VERSION "dbc-export 1 2025.20.8"

NS_ :

BS_:

BU_: ADSP APB APP APS APSB BB BMS CC CMP CMPD CP DAS DI DIF DIR DPB EPAS3P EPAS3S EPASTP EPASTS EPBL EPBR ESP EVSE FC GTW HCML HCMR HVP IBST ICR IDB LS OCS1P ODIN PARK PCS PLG PM PMF PMR PNCD PTC RADC RCM RCM2 RCM3 RCU SCCM SCM SCS SDCR TAS TCU TPMS TRCM UDS UI UIS UMC USM VC VCFRONT VCLEFT VCRIGHT VCSEC VEH

BO_ 1319 DI_alertLog: 8 DI
 SG_ DI_alertID M : 0|8@1+ (1,0) [0|255] "" Vector__XXX
 SG_ DI_alertState : 15|1@1+ (1,0) [0|1] "" Vector__XXX
 SG_ DI_a004_unavailableReason m4 : 16|5@1+ (1,0) [1|31] "" Vector__XXX
 SG_ DI_a007_button m7 : 16|2@1+ (1,0) [0|3] "" Vector__XXX
 SG_ DI_a007_buttonStuckTime m7 : 24|15@1+ (0.25,0) [0|8191.75] "second" Vector__XXX
 SG_ DI_a010_sccReset m10 : 16|1@1+ (1,0) [0|1] "" Vector__XXX
 SG_ DI_a010_hibernate m10 : 17|1@1+ (1,0) [0|1] "" Vector__XXX
 SG_ DI_a010_hwBist m10 : 18|1@1+ (1,0) [0|1] "" Vector__XXX
 SG_ DI_a010_nmiWatchdog m10 : 19|1@1+ (1,0) [0|1] "" Vector__XXX
 SG_ DI_a010_watchdog m10 : 20|1@1+ (1,0) [0|1] "" Vector__XXX
 SG_ DI_a010_clockFailNmi m10 : 21|1@1+ (1,0) [0|1] "" Vector__XXX
 SG_ DI_a010_ramUncErrorNmi m10 : 22|1@1+ (1,0) [0|1] "" Vector__XXX
 SG_ DI_a010_flashUncErrorNmi m10 : 23|1@1+ (1,0) [0|1] "" Vector__XXX
 SG_ DI_a010_cpu1signMismatchNmi m10 : 24|1@1+ (1,0) [0|1] "" Vector__XXX
 SG_ DI_a010_cpu2signMismatchNmi m10 : 25|1@1+ (1,0) [0|1] "" Vector__XXX
 SG_ DI_a010_pieVectErrorNmi m10 : 26|1@1+ (1,0) [0|1] "" Vector__XXX
 SG_ DI_a010_sysDbgNmi m10 : 27|1@1+ (1,0) [0|1] "" Vector__XXX
 SG_ DI_a010_rlNmi m10 : 28|1@1+ (1,0) [0|1] "" Vector__XXX
 SG_ DI_a010_ovfNmi m10 : 29|1@1+ (1,0) [0|1] "" Vector__XXX
 SG_ DI_a010_wdtFlags m10 : 32|16@1+ (1,0) [0|65535] "" Vector__XXX
 SG_ DI_a012_accel1SupplyV m12 : 16|16@1+ (0.001,0) [0|65.535] "V" Vector__XXX
 SG_ DI_a012_accel2SupplyV m12 : 32|16@1+ (0.001,0) [0|65.535] "V" Vector__XXX
 SG_ DI_a013_address m13 : 16|32@1+ (1,0) [0|4294967295] "" Vector__XXX
 SG_ DI_a013_errorType m13 : 48|4@1+ (1,0) [0|15] "" Vector__XXX
 SG_ DI_a015_reason m15 : 16|1@1+ (1,0) [0|1] "" Vector__XXX
 SG_ DI_a020_difHvilStatus m20 : 16|2@1+ (1,0) [0|2] "" Vector__XXX
 SG_ DI_a020_difStatusValid m20 : 18|1@1+ (1,0) [0|1] "" Vector__XXX
 SG_ DI_a020_dirHvilStatus m20 : 19|2@1+ (1,0) [0|2] "" Vector__XXX
 SG_ DI_a020_dirStatusValid m20 : 21|1@1+ (1,0) [0|1] "" Vector__XXX
 SG_ DI_a020_vehiclePowerState m20 : 22|2@1+ (1,0) [0|3] "" Vector__XXX
 SG_ DI_a020_hvilSystemStatus m20 : 24|2@1+ (1,0) [0|2] "" Vector__XXX
 SG_ DI_a021_packVoltage m21 : 16|16@1+ (0.1,0) [0|6553.5] "V" Vector__XXX
 SG_ DI_a021_maxBusVoltage m21 : 32|16@1+ (0.1,0) [0|6553.5] "V" Vector__XXX
 SG_ DI_a024_pedalPos m24 : 16|8@1+ (0.4,0) [0|102] "%" Vector__XXX
 SG_ DI_a024_brakePressed m24 : 24|1@1+ (1,0) [0|1] "" Vector__XXX
 SG_ DI_a024_currentGear m24 : 25|3@1+ (1,0) [0|6] "" Vector__XXX
 SG_ DI_a025_backfillState m25 : 16|2@1+ (1,0) [0|3] "" Vector__XXX
 SG_ DI_a025_bfillUnavailableReason m25 : 18|5@1+ (1,0) [0|31] "" Vector__XXX
 SG_ DI_a036_numFaultedUnits m36 : 16|4@1+ (1,0) [0|15] "" Vector__XXX
 SG_ DI_a036_numAvailableUnits m36 : 20|4@1+ (1,0) [0|15] "" Vector__XXX
 SG_ DI_a040_torque m40 : 16|1@1+ (1,0) [0|1] "" Vector__XXX
 SG_ DI_a040_capability m40 : 17|1@1+ (1,0) [0|1] "" Vector__XXX
 SG_ DI_a040_power m40 : 18|1@1+ (1,0) [0|1] "" Vector__XXX
 SG_ DI_a040_status m40 : 19|1@1+ (1,0) [0|1] "" Vector__XXX
 SG_ DI_a040_capability2 m40 : 20|1@1+ (1,0) [0|1] "" Vector__XXX
 SG_ DI_a040_hvStatus m40 : 21|1@1+ (1,0) [0|1] "" Vector__XXX
 SG_ DI_a040_temperature m40 : 22|1@1+ (1,0) [0|1] "" Vector__XXX
 SG_ DI_a042_state4 m42 : 16|1@1+ (1,0) [0|1] "" Vector__XXX
 SG_ DI_a043_state4 m43 : 16|1@1+ (1,0) [0|1] "" Vector__XXX
 SG_ DI_a051_dcCableCurrentEst m51 : 16|16@1- (0.1,0) [-3276.8|3276.7] "A" Vector__XXX
 SG_ DI_a051_packCurrent m51 : 32|16@1- (0.1,0) [-3276.8|3276.7] "A" Vector__XXX
 SG_ DI_a052_torque m52 : 16|1@1+ (1,0) [0|1] "" Vector__XXX
 SG_ DI_a052_capability m52 : 17|1@1+ (1,0) [0|1] "" Vector__XXX
 SG_ DI_a052_power m52 : 18|1@1+ (1,0) [0|1] "" Vector__XXX
 SG_ DI_a052_status m52 : 19|1@1+ (1,0) [0|1] "" Vector__XXX
 SG_ DI_a052_capability2 m52 : 20|1@1+ (1,0) [0|1] "" Vector__XXX
 SG_ DI_a052_hvStatus m52 : 21|1@1+ (1,0) [0|1] "" Vector__XXX
 SG_ DI_a052_temperature m52 : 22|1@1+ (1,0) [0|1] "" Vector__XXX
 SG_ DI_a053_badValue1 m53 : 16|16@1+ (1,0) [0|65535] "" Vector__XXX
 SG_ DI_a053_badValue2 m53 : 32|16@1+ (1,0) [0|65535] "" Vector__XXX
 SG_ DI_a053_canID m53 : 48|12@1+ (1,0) [0|4095] "" Vector__XXX
 SG_ DI_a053_errorType m53 : 60|3@1+ (1,0) [0|7] "" Vector__XXX
 SG_ DI_a056_badValue1 m56 : 16|16@1+ (1,0) [0|65535] "" Vector__XXX
 SG_ DI_a056_badValue2 m56 : 32|16@1+ (1,0) [0|65535] "" Vector__XXX
 SG_ DI_a056_canID m56 : 48|12@1+ (1,0) [0|4095] "" Vector__XXX
 SG_ DI_a056_errorType m56 : 60|3@1+ (1,0) [0|7] "" Vector__XXX
 SG_ DI_a059_badValue1 m59 : 16|16@1+ (1,0) [0|65535] "" Vector__XXX
 SG_ DI_a059_badValue2 m59 : 32|16@1+ (1,0) [0|65535] "" Vector__XXX
 SG_ DI_a059_canID m59 : 48|12@1+ (1,0) [0|4095] "" Vector__XXX
 SG_ DI_a059_errorType m59 : 60|3@1+ (1,0) [0|7] "" Vector__XXX
 SG_ DI_a062_limpReason m62 : 16|6@1+ (1,0) [0|63] "" Vector__XXX
 SG_ DI_a063_gpoReason m63 : 16|4@1+ (1,0) [0|15] "" Vector__XXX
 SG_ DI_a064_hvState m64 : 16|3@1+ (1,0) [0|7] "" Vector__XXX
 SG_ DI_a064_vehiclePowerState m64 : 19|2@1+ (1,0) [0|3] "" Vector__XXX
 SG_ DI_a064_vehicleSpeed m64 : 24|12@1+ (0.08,-40) [-40|287.6] "kph" Vector__XXX
 SG_ DI_a066_badValue1 m66 : 16|16@1+ (1,0) [0|65535] "" Vector__XXX
 SG_ DI_a066_badValue2 m66 : 32|16@1+ (1,0) [0|65535] "" Vector__XXX
 SG_ DI_a066_canID m66 : 48|12@1+ (1,0) [0|4095] "" Vector__XXX
 SG_ DI_a066_errorType m66 : 60|3@1+ (1,0) [0|7] "" Vector__XXX
 SG_ DI_a076_lvSupplyV m76 : 16|16@1+ (0.001,0) [0|65.535] "V" Vector__XXX
 SG_ DI_a077_lvSupplyV m77 : 16|16@1+ (0.001,0) [0|65.535] "V" Vector__XXX
 SG_ DI_a078_adcRefChan m78 : 16|4@1+ (1,0) [0|15] "" Vector__XXX
 SG_ DI_a078_adcRefLowAvg m78 : 24|16@1+ (1,0) [0|65535] "" Vector__XXX
 SG_ DI_a079_adcRefChan m79 : 16|4@1+ (1,0) [0|15] "" Vector__XXX
 SG_ DI_a079_adcRefHighAvg m79 : 24|16@1+ (1,0) [0|65535] "" Vector__XXX
 SG_ DI_a083_brakeSwitchNO m83 : 16|1@1+ (1,0) [0|1] "" Vector__XXX
 SG_ DI_a083_brakeSwitchNC m83 : 17|1@1+ (1,0) [0|1] "" Vector__XXX
 SG_ DI_a083_brakeSwitchIrrationalNO m83 : 18|1@1+ (1,0) [0|1] "" Vector__XXX
 SG_ DI_a083_brakeSwitchIrrationalNC m83 : 19|1@1+ (1,0) [0|1] "" Vector__XXX
 SG_ DI_a086_DPB_actuator3 m86 : 16|1@1+ (1,0) [0|1] "" Vector__XXX
 SG_ DI_a087_gtwCarConfig m87 : 16|1@1+ (1,0) [0|1] "" Vector__XXX
 SG_ DI_a087_gtwTime m87 : 17|1@1+ (1,0) [0|1] "" Vector__XXX
 SG_ DI_a087_gtwUpdateStatus m87 : 18|1@1+ (1,0) [0|1] "" Vector__XXX
 SG_ DI_a087_gearControl m87 : 19|1@1+ (1,0) [0|1] "" Vector__XXX
 SG_ DI_a087_carState m87 : 20|1@1+ (1,0) [0|1] "" Vector__XXX
 SG_ DI_a089_SCCM_rightStalk m89 : 16|1@1+ (1,0) [0|1] "" Vector__XXX
 SG_ DI_a090_reason m90 : 16|1@1+ (1,0) [0|1] "" Vector__XXX
 SG_ DI_a090_systemState m90 : 17|1@1+ (1,0) [0|1] "" Vector__XXX
 SG_ DI_a090_state m90 : 18|1@1+ (1,0) [0|1] "" Vector__XXX
 SG_ DI_a090_locState m90 : 19|1@1+ (1,0) [0|1] "" Vector__XXX
 SG_ DI_a090_state2 m90 : 20|1@1+ (1,0) [0|1] "" Vector__XXX
 SG_ DI_a090_state4 m90 : 21|1@1+ (1,0) [0|1] "" Vector__XXX
 SG_ DI_a091_ESP_brakeTorque m91 : 16|1@1+ (1,0) [0|1] "" Vector__XXX
 SG_ DI_a091_ESP_wheelSpeeds m91 : 17|1@1+ (1,0) [0|1] "" Vector__XXX
 SG_ DI_a091_ESP_wheelRotation m91 : 18|1@1+ (1,0) [0|1] "" Vector__XXX
 SG_ DI_a091_ESP_motorLimits m91 : 19|1@1+ (1,0) [0|1] "" Vector__XXX
 SG_ DI_a091_ESP_offsets m91 : 20|1@1+ (1,0) [0|1] "" Vector__XXX
 SG_ DI_a091_ESP_status m91 : 21|1@1+ (1,0) [0|1] "" Vector__XXX
 SG_ DI_a091_ESP_party3 m91 : 22|1@1+ (1,0) [0|1] "" Vector__XXX
 SG_ DI_a092_bmsStatus m92 : 16|1@1+ (1,0) [0|1] "" Vector__XXX
 SG_ DI_a092_bmsDriveLimits m92 : 17|1@1+ (1,0) [0|1] "" Vector__XXX
 SG_ DI_a092_bmsHvBusStatus m92 : 18|1@1+ (1,0) [0|1] "" Vector__XXX
 SG_ DI_a092_bmsPowerAvailable m92 : 19|1@1+ (1,0) [0|1] "" Vector__XXX
 SG_ DI_a092_bmsBmbMinMax m92 : 20|1@1+ (1,0) [0|1] "" Vector__XXX
 SG_ DI_a092_bmsSocStatus m92 : 21|1@1+ (1,0) [0|1] "" Vector__XXX
 SG_ DI_a092_bmsThermalStatus m92 : 22|1@1+ (1,0) [0|1] "" Vector__XXX
 SG_ DI_a092_bmsCtrStatus m92 : 23|1@1+ (1,0) [0|1] "" Vector__XXX
 SG_ DI_a092_bmsVoltageRegGain m92 : 24|1@1+ (1,0) [0|1] "" Vector__XXX
 SG_ DI_a092_bmsPackConfig m92 : 25|1@1+ (1,0) [0|1] "" Vector__XXX
 SG_ DI_a092_bmsSystemStatus m92 : 26|1@1+ (1,0) [0|1] "" Vector__XXX
 SG_ DI_a094_canID m94 : 16|12@1+ (1,0) [0|4095] "" Vector__XXX
 SG_ DI_a094_errorType m94 : 28|3@1+ (1,0) [0|7] "" Vector__XXX
 SG_ DI_a094_badValue1 m94 : 32|16@1+ (1,0) [0|65535] "" Vector__XXX
 SG_ DI_a094_badValue2 m94 : 48|16@1+ (1,0) [0|65535] "" Vector__XXX
 SG_ DI_a096_const_fast m96 : 16|1@1+ (1,0) [0|1] "" Vector__XXX
 SG_ DI_a096_text_fast m96 : 17|1@1+ (1,0) [0|1] "" Vector__XXX
 SG_ DI_a096_text_flash m96 : 18|1@1+ (1,0) [0|1] "" Vector__XXX
 SG_ DI_a096_mem_data m96 : 19|1@1+ (1,0) [0|1] "" Vector__XXX
 SG_ DI_a096_mem_regs m96 : 20|1@1+ (1,0) [0|1] "" Vector__XXX
 SG_ DI_a096_boot_flash m96 : 21|1@1+ (1,0) [0|1] "" Vector__XXX
 SG_ DI_a096_word1 m96 : 24|16@1+ (1,0) [0|65535] "" Vector__XXX
 SG_ DI_a096_word2 m96 : 40|16@1+ (1,0) [0|65535] "" Vector__XXX
 SG_ DI_a097_errorType m97 : 16|3@1+ (1,0) [0|7] "" Vector__XXX
 SG_ DI_a097_lineNumber m97 : 24|16@1+ (1,0) [0|65535] "" Vector__XXX
 SG_ DI_a097_argument m97 : 40|16@1+ (1,0) [0|65535] "" Vector__XXX
 SG_ DI_a098_page0Counter m98 : 16|8@1+ (1,0) [0|255] "" Vector__XXX
 SG_ DI_a098_page1Counter m98 : 24|8@1+ (1,0) [0|255] "" Vector__XXX
 SG_ DI_a098_page2Counter m98 : 32|8@1+ (1,0) [0|255] "" Vector__XXX
 SG_ DI_a098_pageID m98 : 40|2@1+ (1,0) [0|3] "" Vector__XXX
 SG_ DI_a098_recordID m98 : 42|4@1+ (1,0) [0|15] "" Vector__XXX
 SG_ DI_a098_errorCode m98 : 48|4@1+ (1,0) [0|15] "" Vector__XXX
 SG_ DI_a103_BB_status m103 : 16|1@1+ (1,0) [0|1] "" Vector__XXX
 SG_ DI_a103_BB_brakeActuation m103 : 17|1@1+ (1,0) [0|1] "" Vector__XXX
 SG_ DI_a104_proxIrrationalReason m104 : 16|1@1+ (1,0) [0|1] "" Vector__XXX
 SG_ DI_a105_cpStatus m105 : 16|1@1+ (1,0) [0|1] "" Vector__XXX
 SG_ DI_a110_EPBL_status m110 : 16|1@1+ (1,0) [0|1] "" Vector__XXX
 SG_ DI_a110_EPBR_status m110 : 17|1@1+ (1,0) [0|1] "" Vector__XXX
 SG_ DI_a115_faultAddress m115 : 16|32@1+ (1,0) [0|4294967295] "" Vector__XXX
 SG_ DI_a115_isWriteNotRead m115 : 48|1@1+ (1,0) [0|1] "" Vector__XXX
 SG_ DI_a120_blendingState m120 : 16|2@1+ (1,0) [0|3] "" Vector__XXX
 SG_ DI_a120_blendingUnavailableReaso m120 : 18|5@1+ (1,0) [0|31] "" Vector__XXX
 SG_ DI_a124_undrivenWheelMPH m124 : 16|16@1+ (0.1,0) [0|6553.5] "MPH" Vector__XXX
 SG_ DI_a124_cruiseFaultReason m124 : 32|5@1+ (1,0) [0|31] "" Vector__XXX
 SG_ DI_a125_maxDischargeCurrent m125 : 16|16@1- (0.1,0) [-3276.8|3276.7] "A" Vector__XXX
 SG_ DI_a125_maxChargeCurrent m125 : 32|16@1- (0.1,0) [-3276.8|3276.7] "A" Vector__XXX
 SG_ DI_a125_minBusVoltage m125 : 48|16@1+ (0.1,0) [0|6553.5] "V" Vector__XXX
 SG_ DI_a130_aebFaultReason m130 : 16|4@1+ (1,0) [0|15] "" Vector__XXX
 SG_ DI_a130_aebSmState m130 : 20|3@1+ (1,0) [0|7] "" Vector__XXX
 SG_ DI_a130_dasAebEvent m130 : 24|2@1+ (1,0) [0|2] "" Vector__XXX
 SG_ DI_a130_aebBrakeTorqueCommand m130 : 26|13@1+ (3,0) [0|24573] "Nm" Vector__XXX
 SG_ DI_a131_totalTimeRemaining m131 : 16|16@1+ (1,0) [0|65535] "" Vector__XXX
 SG_ DI_a131_warnSpeedLimit m131 : 32|16@1+ (1,0) [0|65535] "RPM" Vector__XXX
 SG_ DI_a131_warnTimeRemaining m131 : 48|16@1+ (1,0) [0|65535] "" Vector__XXX
 SG_ DI_a133_vhldSmState m133 : 16|4@1+ (1,0) [0|15] "" Vector__XXX
 SG_ DI_a133_reverseGear m133 : 20|1@1+ (1,0) [0|1] "" Vector__XXX
 SG_ DI_a133_vhldGrade m133 : 24|8@1+ (0.01,-1) [-1|1.55] "G" Vector__XXX
 SG_ DI_a134_wheelSpeedDiffFrL m134 : 16|12@1- (0.0625,0) [-128|127.9375] "kph" Vector__XXX
 SG_ DI_a134_wheelSpeedDiffFrR m134 : 28|12@1- (0.0625,0) [-128|127.9375] "kph" Vector__XXX
 SG_ DI_a134_wheelSpeedDiffReL m134 : 40|12@1- (0.0625,0) [-128|127.9375] "kph" Vector__XXX
 SG_ DI_a134_wheelSpeedDiffReR m134 : 52|12@1- (0.0625,0) [-128|127.9375] "kph" Vector__XXX
 SG_ DI_a135_vhldFaultReason m135 : 16|4@1+ (1,0) [0|15] "" Vector__XXX
 SG_ DI_a135_vhldSmState m135 : 20|4@1+ (1,0) [0|15] "" Vector__XXX
 SG_ DI_a135_vhldBrakeApply m135 : 24|1@1+ (1,0) [0|1] "" Vector__XXX
 SG_ DI_a135_vhldBrakeTorqueCommand m135 : 25|10@1+ (10,0) [0|10230] "Nm" Vector__XXX
 SG_ DI_a135_vhldTotalBrakeTorque m135 : 35|10@1+ (10,0) [0|10230] "Nm" Vector__XXX
 SG_ DI_a135_vhldPropulsiveTorque m135 : 45|10@1- (1,0) [-512|511] "Nm" Vector__XXX
 SG_ DI_a135_vhldGrade m135 : 56|8@1+ (0.01,-1) [-1|1.55] "G" Vector__XXX
 SG_ DI_a140_PTC_feedbackStatus m140 : 16|1@1+ (1,0) [0|1] "" Vector__XXX
 SG_ DI_a141_DAS_control m141 : 16|1@1+ (1,0) [0|1] "" Vector__XXX
 SG_ DI_a141_DAS_pmmControl m141 : 17|1@1+ (1,0) [0|1] "" Vector__XXX
 SG_ DI_a141_DAS_status m141 : 18|1@1+ (1,0) [0|1] "" Vector__XXX
 SG_ DI_a141_DAS_status2 m141 : 19|1@1+ (1,0) [0|1] "" Vector__XXX
 SG_ DI_a141_DAS_smartShift m141 : 20|1@1+ (1,0) [0|1] "" Vector__XXX
 SG_ DI_a141_DAS_longControl m141 : 21|1@1+ (1,0) [0|1] "" Vector__XXX
 SG_ DI_a141_DAS_longControlTuningPar m141 : 22|1@1+ (1,0) [0|1] "" Vector__XXX
 SG_ DI_a141_DAS_autonomyControl m141 : 23|1@1+ (1,0) [0|1] "" Vector__XXX
 SG_ DI_a143_mechPowerLimit m143 : 16|1@1+ (1,0) [0|1] "" Vector__XXX
 SG_ DI_a143_systemTorqueLimit m143 : 17|1@1+ (1,0) [0|1] "" Vector__XXX
 SG_ DI_a144_autopilot m144 : 16|1@1+ (1,0) [0|1] "" Vector__XXX
 SG_ DI_a144_chassisType m144 : 17|1@1+ (1,0) [0|1] "" Vector__XXX
 SG_ DI_a144_drivetrainType m144 : 18|1@1+ (1,0) [0|1] "" Vector__XXX
 SG_ DI_a144_packEnergy m144 : 19|1@1+ (1,0) [0|1] "" Vector__XXX
 SG_ DI_a144_packPerformanceDeviation m144 : 20|1@1+ (1,0) [0|1] "" Vector__XXX
 SG_ DI_a144_performancePackage m144 : 21|1@1+ (1,0) [0|1] "" Vector__XXX
 SG_ DI_a144_vdcType m144 : 22|1@1+ (1,0) [0|1] "" Vector__XXX
 SG_ DI_a144_brakeHWType m144 : 23|1@1+ (1,0) [0|1] "" Vector__XXX
 SG_ DI_a144_inverterHardware m144 : 24|1@1+ (1,0) [0|1] "" Vector__XXX
 SG_ DI_a144_cabinPTCHeaterType m144 : 25|1@1+ (1,0) [0|1] "" Vector__XXX
 SG_ DI_a144_frunkLatchType m144 : 26|1@1+ (1,0) [0|1] "" Vector__XXX
 SG_ DI_a144_platformMaxBusVoltage m144 : 27|1@1+ (1,0) [0|1] "" Vector__XXX
 SG_ DI_a144_oilPump1HwType m144 : 28|1@1+ (1,0) [0|1] "" Vector__XXX
 SG_ DI_a144_oilPump2HwType m144 : 29|1@1+ (1,0) [0|1] "" Vector__XXX
 SG_ DI_a144_heatsinkType m144 : 30|1@1+ (1,0) [0|1] "" Vector__XXX
 SG_ DI_a144_softPerformanceLimit m144 : 31|1@1+ (1,0) [0|1] "" Vector__XXX
 SG_ DI_a144_brakeActuationType m144 : 32|1@1+ (1,0) [0|1] "" Vector__XXX
 SG_ DI_a144_dasHw m144 : 33|1@1+ (1,0) [0|1] "" Vector__XXX
 SG_ DI_a144_chassisSubType m144 : 34|1@1+ (1,0) [0|1] "" Vector__XXX
 SG_ DI_a146_panicReason m146 : 16|3@1+ (1,0) [0|7] "" Vector__XXX
 SG_ DI_a155_sensors m155 : 16|1@1+ (1,0) [0|1] "" Vector__XXX
 SG_ DI_a155_coolant m155 : 17|1@1+ (1,0) [0|1] "" Vector__XXX
 SG_ DI_a155_LVPowerState m155 : 18|1@1+ (1,0) [0|1] "" Vector__XXX
 SG_ DI_a155_vehicleStatus m155 : 19|1@1+ (1,0) [0|1] "" Vector__XXX
 SG_ DI_a155_status m155 : 20|1@1+ (1,0) [0|1] "" Vector__XXX
 SG_ DI_a155_leftDoorStatus m155 : 21|1@1+ (1,0) [0|1] "" Vector__XXX
 SG_ DI_a155_rightDoorStatus m155 : 22|1@1+ (1,0) [0|1] "" Vector__XXX
 SG_ DI_a155_vcleftSwitchStatus m155 : 23|1@1+ (1,0) [0|1] "" Vector__XXX
 SG_ DI_a155_restraintStatus m155 : 24|1@1+ (1,0) [0|1] "" Vector__XXX
 SG_ DI_a155_systemStatus m155 : 25|1@1+ (1,0) [0|1] "" Vector__XXX
 SG_ DI_a155_prndStatus m155 : 26|1@1+ (1,0) [0|1] "" Vector__XXX
 SG_ DI_a155_liftgateStatus m155 : 27|1@1+ (1,0) [0|1] "" Vector__XXX
 SG_ DI_a157_RCM_inertial1 m157 : 16|1@1+ (1,0) [0|1] "" Vector__XXX
 SG_ DI_a157_RCM_inertial2 m157 : 17|1@1+ (1,0) [0|1] "" Vector__XXX
 SG_ DI_a158_IBST_party1 m158 : 16|1@1+ (1,0) [0|1] "" Vector__XXX
 SG_ DI_a158_BUS1_IBST_status m158 : 17|1@1+ (1,0) [0|1] "" Vector__XXX
 SG_ DI_a158_BUS2_IBST_status m158 : 18|1@1+ (1,0) [0|1] "" Vector__XXX
 SG_ DI_a160_kTire m160 : 16|7@1+ (0.001,0.008) [0.008|0.135] "-" Vector__XXX
 SG_ DI_a160_tireFitment m160 : 24|2@1+ (1,0) [0|2] "" Vector__XXX
 SG_ DI_a160_wearFactorFrL m160 : 26|6@1+ (0.00125,0.96) [0.96|1.03875] "ratio" Vector__XXX
 SG_ DI_a160_wearFactorFrR m160 : 32|6@1+ (0.00125,0.96) [0.96|1.03875] "ratio" Vector__XXX
 SG_ DI_a160_wearFactorReL m160 : 40|6@1+ (0.00125,0.96) [0.96|1.03875] "ratio" Vector__XXX
 SG_ DI_a160_distanceSinceLastTireCon m160 : 48|12@1+ (0.01,0) [0|40.94] "km" Vector__XXX
 SG_ DI_a161_EPAS3P_sysStatus m161 : 16|1@1+ (1,0) [0|1] "" Vector__XXX
 SG_ DI_a161_EPAS3P_angleCalib m161 : 17|1@1+ (1,0) [0|1] "" Vector__XXX
 SG_ DI_a162_shiftDeniedReason m162 : 16|4@1+ (1,0) [0|15] "" Vector__XXX
 SG_ DI_a162_motorSpeed m162 : 20|10@1- (0.2,0) [-102.4|102.2] "MPH" Vector__XXX
 SG_ DI_a162_essContClosed m162 : 30|1@1+ (1,0) [0|1] "" Vector__XXX
 SG_ DI_a162_manualDrivingProhibited m162 : 31|1@1+ (1,0) [0|1] "" Vector__XXX
 SG_ DI_a162_pedalPos m162 : 32|8@1+ (0.4,0) [0|102] "%" Vector__XXX
 SG_ DI_a162_currentGear m162 : 40|3@1+ (1,0) [0|6] "" Vector__XXX
 SG_ DI_a162_requestedGear m162 : 43|3@1+ (1,0) [0|6] "" Vector__XXX
 SG_ DI_a162_requestSource m162 : 46|4@1+ (1,0) [0|15] "" Vector__XXX
 SG_ DI_a162_timeSinceCruiseCancel m162 : 50|7@1+ (0.5,0) [0|63.5] "second" Vector__XXX
 SG_ DI_a162_chargeCableConnected m162 : 57|1@1+ (1,0) [0|1] "" Vector__XXX
 SG_ DI_a162_frunkOpen m162 : 58|1@1+ (1,0) [0|1] "" Vector__XXX
 SG_ DI_a162_sysStateExitCondition m162 : 59|5@1+ (1,0) [0|31] "" Vector__XXX
 SG_ DI_a163_motorSpeed m163 : 16|16@1- (0.01,0) [-327.68|327.67] "MPH" Vector__XXX
 SG_ DI_a163_currentGear m163 : 32|3@1+ (1,0) [0|6] "" Vector__XXX
 SG_ DI_a163_requestedGear m163 : 35|3@1+ (1,0) [0|6] "" Vector__XXX
 SG_ DI_a163_requestSource m163 : 40|4@1+ (1,0) [0|15] "" Vector__XXX
 SG_ DI_a164_motorSpeed m164 : 16|16@1- (0.01,0) [-327.68|327.67] "MPH" Vector__XXX
 SG_ DI_a164_pedalPos m164 : 32|8@1+ (0.4,0) [0|102] "%" Vector__XXX
 SG_ DI_a164_torqueDriver m164 : 40|14@1- (0.2,0) [-1638.4|1638.2] "Nm" Vector__XXX
 SG_ DI_a165_crsCancelReason m165 : 16|4@1+ (1,0) [0|15] "" Vector__XXX
 SG_ DI_a170_tireSeasonSelected m170 : 16|1@1+ (1,0) [0|1] "" Vector__XXX
 SG_ DI_a170_kTire m170 : 17|7@1+ (0.001,0.008) [0.008|0.135] "-" Vector__XXX
 SG_ DI_a170_tireFitment m170 : 24|2@1+ (1,0) [0|2] "" Vector__XXX
 SG_ DI_a170_wearFactorFrL m170 : 26|6@1+ (0.00125,0.96) [0.96|1.03875] "ratio" Vector__XXX
 SG_ DI_a170_wearFactorFrR m170 : 32|6@1+ (0.00125,0.96) [0.96|1.03875] "ratio" Vector__XXX
 SG_ DI_a170_wearFactorReL m170 : 38|6@1+ (0.00125,0.96) [0.96|1.03875] "ratio" Vector__XXX
 SG_ DI_a170_odometer m170 : 44|12@1+ (500,0) [0|2047000] "km" Vector__XXX
 SG_ DI_a170_distanceSinceLastTireCon m170 : 56|6@1+ (500,0) [0|31000] "km" Vector__XXX
 SG_ DI_a170_treadDepthAlertSet m170 : 62|1@1+ (1,0) [0|1] "" Vector__XXX
 SG_ DI_a172_motorSpeed m172 : 16|16@1- (0.01,0) [-327.68|327.67] "MPH" Vector__XXX
 SG_ DI_a172_pedalPos m172 : 32|8@1+ (0.4,0) [0|102] "%" Vector__XXX
 SG_ DI_a172_currentGear m172 : 40|3@1+ (1,0) [0|6] "" Vector__XXX
 SG_ DI_a172_timeSinceCruiseCancel m172 : 48|7@1+ (0.5,0) [0|63.5] "second" Vector__XXX
 SG_ DI_a173_brakeApply m173 : 16|16@1- (0.01,0) [-327.68|327.67] "bar" Vector__XXX
 SG_ DI_a173_pedalPos m173 : 32|8@1+ (0.4,0) [0|102] "%" Vector__XXX
 SG_ DI_a175_crsNotAvailableReason m175 : 16|6@1+ (1,0) [0|63] "" Vector__XXX
 SG_ DI_a177_newFitment m177 : 16|2@1+ (1,0) [0|2] "" Vector__XXX
 SG_ DI_a178_offsetValue m178 : 16|8@1- (0.16,0) [-20.48|20.32] "deg" Vector__XXX
 SG_ DI_a180_crsNotAvailableReason m180 : 16|6@1+ (1,0) [0|63] "" Vector__XXX
 SG_ DI_a184_apcCancelReason m184 : 16|5@1+ (1,0) [0|31] "" Vector__XXX
 SG_ DI_a184_apcUnavailableReason m184 : 24|4@1+ (1,0) [0|15] "" Vector__XXX
 SG_ DI_a184_autoparkInternalState m184 : 32|5@1+ (1,0) [0|31] "" Vector__XXX
 SG_ DI_a185_summonActive m185 : 16|1@1+ (1,0) [0|1] "" Vector__XXX
 SG_ DI_a185_apcCancelReason m185 : 17|5@1+ (1,0) [0|31] "" Vector__XXX
 SG_ DI_a185_apcUnavailableReason m185 : 24|4@1+ (1,0) [0|15] "" Vector__XXX
 SG_ DI_a185_crsNotAvailableReason m185 : 32|6@1+ (1,0) [0|63] "" Vector__XXX
 SG_ DI_a185_crsFaultReason m185 : 40|5@1+ (1,0) [0|31] "" Vector__XXX
 SG_ DI_a185_autoparkInternalState m185 : 48|5@1+ (1,0) [0|31] "" Vector__XXX
 SG_ DI_a187_filteredAccel m187 : 16|16@1- (0.01,0) [-327.68|327.67] "m/s^2" Vector__XXX
 SG_ DI_a187_rawPedal m187 : 32|8@1+ (0.4,0) [0|102] "%" Vector__XXX
 SG_ DI_a187_systemTorqueCommand m187 : 40|16@1- (1,0) [-32768|32767] "Nm" Vector__XXX
 SG_ DI_a189_accelPedal m189 : 16|5@1+ (3.125,0) [0|96.875] "%" Vector__XXX
 SG_ DI_a189_grade m189 : 24|4@1- (4,0) [-32|28] "%" Vector__XXX
 SG_ DI_a189_brakePressed m189 : 28|1@1+ (1,0) [0|1] "" Vector__XXX
 SG_ DI_a189_systemTorque m189 : 32|8@1- (10,0) [-1280|1270] "Nm" Vector__XXX
 SG_ DI_a189_motorSpeed m189 : 40|5@1- (0.5,0) [-8|7.5] "MPH" Vector__XXX
 SG_ DI_a190_relativeTireTreadDepth m190 : 16|6@1+ (0.2,0) [0|12.6] "mm" Vector__XXX
 SG_ DI_a190_treadWearFactorFrL m190 : 24|6@1+ (0.001,0.969) [0.969|1.032] "ratio" Vector__XXX
 SG_ DI_a190_treadWearFactorFrR m190 : 32|6@1+ (0.001,0.969) [0.969|1.032] "ratio" Vector__XXX
 SG_ DI_a190_treadWearFactorReL m190 : 40|6@1+ (0.001,0.969) [0.969|1.032] "ratio" Vector__XXX
 SG_ DI_a190_treadWearFactorAvgConfid m190 : 48|5@1+ (0.05,0) [0|1.55] "ratio" Vector__XXX
 SG_ DI_a191_motorSpeed m191 : 16|16@1- (0.01,0) [-327.68|327.67] "MPH" Vector__XXX
 SG_ DI_a191_reverseDeniedAfterCruise m191 : 32|1@1+ (1,0) [0|1] "" Vector__XXX
 SG_ DI_a191_currentGear m191 : 33|3@1+ (1,0) [0|6] "" Vector__XXX
 SG_ DI_a191_requestedGear m191 : 36|3@1+ (1,0) [0|6] "" Vector__XXX
 SG_ DI_a191_requestSource m191 : 40|4@1+ (1,0) [0|15] "" Vector__XXX
 SG_ DI_a191_timeSinceCruiseCancel m191 : 48|7@1+ (0.5,0) [0|63.5] "second" Vector__XXX
 SG_ DI_a193_brakeTorqueFrL m193 : 16|3@1+ (1,0) [0|7] "" Vector__XXX
 SG_ DI_a193_brakeTorqueFrLLastVal m193 : 19|10@1+ (12,0) [0|12276] "Nm" Vector__XXX
 SG_ DI_a193_brakeTorqueFrLCurrVal m193 : 29|10@1+ (12,0) [0|12276] "Nm" Vector__XXX
 SG_ DI_a193_brakeTorqueFrR m193 : 40|3@1+ (1,0) [0|7] "" Vector__XXX
 SG_ DI_a193_brakeTorqueFrRLastVal m193 : 43|10@1+ (12,0) [0|12276] "Nm" Vector__XXX
 SG_ DI_a193_brakeTorqueFrRCurrVal m193 : 53|10@1+ (12,0) [0|12276] "Nm" Vector__XXX
 SG_ DI_a194_brakeTorqueReL m194 : 16|3@1+ (1,0) [0|7] "" Vector__XXX
 SG_ DI_a194_brakeTorqueReLLastVal m194 : 19|10@1+ (12,0) [0|12276] "Nm" Vector__XXX
 SG_ DI_a194_brakeTorqueReLCurrVal m194 : 29|10@1+ (12,0) [0|12276] "Nm" Vector__XXX
 SG_ DI_a194_brakeTorqueReR m194 : 40|3@1+ (1,0) [0|7] "" Vector__XXX
 SG_ DI_a194_brakeTorqueReRLastVal m194 : 43|10@1+ (12,0) [0|12276] "Nm" Vector__XXX
 SG_ DI_a194_brakeTorqueReRCurrVal m194 : 53|10@1+ (12,0) [0|12276] "Nm" Vector__XXX
 SG_ DI_a199_muVehicleLearnDown m199 : 16|5@1+ (0.05,0) [0|1.55] "-" Vector__XXX
 SG_ DI_a199_muVehicleDecFilt m199 : 21|5@1+ (0.05,0) [0|1.55] "-" Vector__XXX
 SG_ DI_a199_bankAngle m199 : 26|6@1- (0.016,0) [-0.512|0.496] "rad" Vector__XXX
 SG_ DI_a199_lateralAccelFilt m199 : 32|6@1- (0.5,0) [-16|15.5] "m/s^2" Vector__XXX
 SG_ DI_a199_driverIntendedYawRate m199 : 38|7@1- (0.024,0) [-1.536|1.512] "rad/s" Vector__XXX
 SG_ DI_a199_vehicleVelocity m199 : 45|5@1+ (2,0) [0|62] "m/s" Vector__XXX
 SG_ DI_a199_sensorYawRate m199 : 50|7@1- (0.024,0) [-1.536|1.512] "rad/s" Vector__XXX
 SG_ DI_a199_preControlActive m199 : 57|1@1+ (1,0) [0|1] "" Vector__XXX
 SG_ DI_a199_oversteerdMzActive m199 : 58|1@1+ (1,0) [0|1] "" Vector__XXX
 SG_ DI_a199_decelControlActive m199 : 59|1@1+ (1,0) [0|1] "" Vector__XXX
 SG_ DI_a199_understeerdMzActive m199 : 60|1@1+ (1,0) [0|1] "" Vector__XXX
 SG_ DI_a199_vdcMode m199 : 61|2@1+ (1,0) [0|3] "" Vector__XXX
 SG_ DI_a200_MBPCheckStatus m200 : 16|1@1+ (1,0) [0|1] "" Vector__XXX
 SG_ DI_a200_MBPFailedCase m200 : 17|6@1+ (1,0) [0|63] "" Vector__XXX
 SG_ DI_a200_MBPFaultProbability m200 : 24|10@1+ (0.008,0) [0|8.184] "-" Vector__XXX
 SG_ DI_a202_reason m202 : 16|4@1+ (1,0) [0|15] "" Vector__XXX
 SG_ DI_a202_movement m202 : 20|9@1+ (0.005,0) [0|2.555] "m" Vector__XXX
 SG_ DI_a202_sysStateExitCondition m202 : 32|5@1+ (1,0) [0|31] "" Vector__XXX
 SG_ DI_a203_ptcStateLocal m203 : 16|3@1+ (1,0) [0|7] "" Vector__XXX
 SG_ DI_a203_btcState m203 : 19|1@1+ (1,0) [0|1] "" Vector__XXX
 SG_ DI_a204_longAccel m204 : 16|3@1+ (1,0) [0|7] "" Vector__XXX
 SG_ DI_a204_longAccelLastVal m204 : 19|10@1- (0.08,0) [-40.96|40.88] "m/s^2" Vector__XXX
 SG_ DI_a204_longAccelCurrVal m204 : 29|10@1- (0.08,0) [-40.96|40.88] "m/s^2" Vector__XXX
 SG_ DI_a204_rollRate m204 : 40|3@1+ (1,0) [0|7] "" Vector__XXX
 SG_ DI_a204_rollRateLastVal m204 : 43|10@1- (0.006,0) [-3.072|3.066] "rad/s" Vector__XXX
 SG_ DI_a204_rollRateCurrVal m204 : 53|10@1- (0.006,0) [-3.072|3.066] "rad/s" Vector__XXX
 SG_ DI_a205_latAccel m205 : 16|3@1+ (1,0) [0|7] "" Vector__XXX
 SG_ DI_a205_latAccelLastVal m205 : 19|10@1- (0.08,0) [-40.96|40.88] "m/s^2" Vector__XXX
 SG_ DI_a205_latAccelCurrVal m205 : 29|10@1- (0.08,0) [-40.96|40.88] "m/s^2" Vector__XXX
 SG_ DI_a205_pitchRate m205 : 40|3@1+ (1,0) [0|7] "" Vector__XXX
 SG_ DI_a205_pitchRateLastVal m205 : 43|10@1- (0.006,0) [-3.072|3.066] "rad/s" Vector__XXX
 SG_ DI_a205_pitchRateCurrVal m205 : 53|10@1- (0.006,0) [-3.072|3.066] "rad/s" Vector__XXX
 SG_ DI_a206_verticalAccel m206 : 16|3@1+ (1,0) [0|7] "" Vector__XXX
 SG_ DI_a206_verticalAccelLastVal m206 : 19|10@1- (0.08,0) [-40.96|40.88] "m/s^2" Vector__XXX
 SG_ DI_a206_verticalAccelCurrVal m206 : 29|10@1- (0.08,0) [-40.96|40.88] "m/s^2" Vector__XXX
 SG_ DI_a206_yawRate m206 : 40|3@1+ (1,0) [0|7] "" Vector__XXX
 SG_ DI_a206_yawRateLastVal m206 : 43|10@1- (0.006,0) [-3.072|3.066] "rad/s" Vector__XXX
 SG_ DI_a206_yawRateCurrVal m206 : 53|10@1- (0.006,0) [-3.072|3.066] "rad/s" Vector__XXX
 SG_ DI_a210_ptcStateGlobal m210 : 16|2@1+ (1,0) [0|2] "" Vector__XXX
 SG_ DI_a210_espActuatorState m210 : 18|2@1+ (1,0) [0|3] "" Vector__XXX
 SG_ DI_a210_brakeTmpEstStateFaulted m210 : 20|1@1+ (1,0) [0|1] "" Vector__XXX
 SG_ DI_a210_secondaryBrakeActuatorIs m210 : 21|1@1+ (1,0) [0|1] "" Vector__XXX
 SG_ DI_a223_ptcStateLocal m223 : 16|3@1+ (1,0) [0|7] "" Vector__XXX
 SG_ DI_a223_btcState m223 : 19|1@1+ (1,0) [0|1] "" Vector__XXX
 SG_ DI_a223_velocityEstimatorState m223 : 20|3@1+ (1,0) [0|7] "" Vector__XXX
 SG_ DI_a223_addState_dir m223 : 24|2@1+ (1,0) [0|3] "" Vector__XXX
 SG_ DI_a223_addState_dif m223 : 26|2@1+ (1,0) [0|3] "" Vector__XXX
 SG_ DI_a223_DI_tractionControlMode m223 : 28|3@1+ (1,0) [0|7] "" Vector__XXX
 SG_ DI_a223_UI_tractionControlMode m223 : 32|3@1+ (1,0) [0|7] "" Vector__XXX
 SG_ DI_a223_vehicleVelocity m223 : 40|7@1- (1,48) [-16|111] "m/s" Vector__XXX
 SG_ DI_a223_musurf m223 : 48|4@1+ (0.1,0) [0|1.5] "-" Vector__XXX
 SG_ DI_a223_musurfHigh m223 : 52|4@1+ (0.1,0) [0|1.5] "-" Vector__XXX
 SG_ DI_a223_driveTCActive m223 : 56|1@1+ (1,0) [0|1] "" Vector__XXX
 SG_ DI_a223_regenTCActive m223 : 57|1@1+ (1,0) [0|1] "" Vector__XXX
 SG_ DI_a223_surfaceUtility m223 : 58|3@1+ (15,0) [0|105] "%" Vector__XXX
 SG_ DI_a224_brakeFLTemp m224 : 16|10@1- (1,300) [-212|811] "degC" Vector__XXX
 SG_ DI_a224_brakeFRTemp m224 : 26|10@1- (1,300) [-212|811] "degC" Vector__XXX
 SG_ DI_a224_brakeRLTemp m224 : 36|10@1- (1,300) [-212|811] "degC" Vector__XXX
 SG_ DI_a224_brakeRRTemp m224 : 46|10@1- (1,300) [-212|811] "degC" Vector__XXX
 SG_ DI_a226_systState m226 : 16|4@1+ (1,0) [0|15] "" Vector__XXX
 SG_ DI_a226_hvStateNotUpForDrive m226 : 20|1@1+ (1,0) [0|1] "" Vector__XXX
 SG_ DI_a226_frunkNotLatched m226 : 21|1@1+ (1,0) [0|1] "" Vector__XXX
 SG_ DI_a226_proxDetected m226 : 22|1@1+ (1,0) [0|1] "" Vector__XXX
 SG_ DI_a226_falconDoorOpen m226 : 23|1@1+ (1,0) [0|1] "" Vector__XXX
 SG_ DI_a226_trunkOpen m226 : 24|1@1+ (1,0) [0|1] "" Vector__XXX
 SG_ DI_a227_hvState m227 : 16|3@1+ (1,0) [0|7] "" Vector__XXX
 SG_ DI_a227_vehiclePowerState m227 : 19|2@1+ (1,0) [0|3] "" Vector__XXX
 SG_ DI_a230_CMP_HVStatus m230 : 16|1@1+ (1,0) [0|1] "" Vector__XXX
 SG_ DI_a230_CMPD_state m230 : 17|1@1+ (1,0) [0|1] "" Vector__XXX
 SG_ DI_a232_velocityEstimatorState m232 : 16|3@1+ (1,0) [0|7] "" Vector__XXX
 SG_ DI_a232_UI_tractionControlMode m232 : 19|3@1+ (1,0) [0|7] "" Vector__XXX
 SG_ DI_a232_vehicleVelocity m232 : 24|6@1+ (1,0) [0|63] "m/s" Vector__XXX
 SG_ DI_a232_musurf m232 : 32|3@1+ (0.15,0.15) [0.15|1.2] "-" Vector__XXX
 SG_ DI_a232_musurfHigh m232 : 35|3@1+ (0.15,0.15) [0.15|1.2] "-" Vector__XXX
 SG_ DI_a232_allWhlSpeedRotationAvail m232 : 38|1@1+ (1,0) [0|1] "" Vector__XXX
 SG_ DI_a232_BrakeMasterCylPressValid m232 : 39|1@1+ (1,0) [0|1] "" Vector__XXX
 SG_ DI_a232_WheelBrakeTorquesValid m232 : 40|1@1+ (1,0) [0|1] "" Vector__XXX
 SG_ DI_a232_AbsBrakeEventActiveValid m232 : 41|1@1+ (1,0) [0|1] "" Vector__XXX
 SG_ DI_a232_UndersteerActiveValid m232 : 42|1@1+ (1,0) [0|1] "" Vector__XXX
 SG_ DI_a232_OversteerActiveValid m232 : 43|1@1+ (1,0) [0|1] "" Vector__XXX
 SG_ DI_a232_allMotorTorquesValid m232 : 44|1@1+ (1,0) [0|1] "" Vector__XXX
 SG_ DI_a232_lateralAccelValid m232 : 45|1@1+ (1,0) [0|1] "" Vector__XXX
 SG_ DI_a232_longitudinalAccelValid m232 : 46|1@1+ (1,0) [0|1] "" Vector__XXX
 SG_ DI_a232_yawRateValid m232 : 47|1@1+ (1,0) [0|1] "" Vector__XXX
 SG_ DI_a232_steerAngleValid m232 : 48|1@1+ (1,0) [0|1] "" Vector__XXX
 SG_ DI_a236_states m236 : 16|1@1+ (1,0) [0|1] "" Vector__XXX
 SG_ DI_a239_numRequests m239 : 16|16@1+ (1,0) [0|65535] "" Vector__XXX
 SG_ DI_a243_RCU_status m243 : 16|1@1+ (1,0) [0|1] "" Vector__XXX
 SG_ DI_a243_RCU_actuation m243 : 17|1@1+ (1,0) [0|1] "" Vector__XXX
 SG_ DI_a245_ebrStatus m245 : 16|2@1+ (1,0) [0|3] "" Vector__XXX
 SG_ DI_a245_vehicleHoldState m245 : 18|3@1+ (1,0) [0|7] "" Vector__XXX
 SG_ DI_a246_onePedalDrivingState m246 : 16|4@1+ (1,0) [0|15] "" Vector__XXX
 SG_ DI_a246_opdUnavailableReason m246 : 24|5@1+ (1,0) [0|31] "" Vector__XXX
 SG_ DI_a249_learning_DIF m249 : 16|1@1+ (1,0) [0|1] "" Vector__XXX
 SG_ DI_a249_learning_DIR m249 : 17|1@1+ (1,0) [0|1] "" Vector__XXX
 SG_ DI_a250_tasRequest m250 : 16|1@1+ (1,0) [0|1] "" Vector__XXX
 SG_ DI_a250_tasMIA m250 : 17|1@1+ (1,0) [0|1] "" Vector__XXX

BO_ 871 DI_alertMatrix1: 8 DI
 SG_ DI_a001_frunkSpeedLimitActive : 0|1@1+ (1,0) [0|1] "" Vector__XXX
 SG_ DI_a002_parkButtonDuringStalkReq : 1|1@1+ (1,0) [0|1] "" Vector__XXX
 SG_ DI_a003_suggestedGearOverride : 2|1@1+ (1,0) [0|1] "" Vector__XXX
 SG_ DI_a004_smartShiftUnavailable : 3|1@1+ (1,0) [0|1] "" Vector__XXX
 SG_ DI_a005_stalkPanicked : 4|1@1+ (1,0) [0|1] "" Vector__XXX
 SG_ DI_a006_shifterUnavailable : 5|1@1+ (1,0) [0|1] "" Vector__XXX
 SG_ DI_a007_secGearSelButtonStuck : 6|1@1+ (1,0) [0|1] "" Vector__XXX
 SG_ DI_a010_unintendedReset : 9|1@1+ (1,0) [0|1] "" Vector__XXX
 SG_ DI_a012_accel5VSupply : 11|1@1+ (1,0) [0|1] "" Vector__XXX
 SG_ DI_a013_eccError : 12|1@1+ (1,0) [0|1] "" Vector__XXX
 SG_ DI_a014_secGearSelActivated : 13|1@1+ (1,0) [0|1] "" Vector__XXX
 SG_ DI_a015_immobilizer : 14|1@1+ (1,0) [0|1] "" Vector__XXX
 SG_ DI_a016_parkRequestByPM : 15|1@1+ (1,0) [0|1] "" Vector__XXX
 SG_ DI_a017_hwPedalMonitor : 16|1@1+ (1,0) [0|1] "" Vector__XXX
 SG_ DI_a018_hwLVSupplyUV : 17|1@1+ (1,0) [0|1] "" Vector__XXX
 SG_ DI_a019_hwAccelPedalPower : 18|1@1+ (1,0) [0|1] "" Vector__XXX
 SG_ DI_a020_systemHvilNotClosed : 19|1@1+ (1,0) [0|1] "" Vector__XXX
 SG_ DI_a021_packOvervoltage : 20|1@1+ (1,0) [0|1] "" Vector__XXX
 SG_ DI_a022_hw5vSupplyUV : 21|1@1+ (1,0) [0|1] "" Vector__XXX
 SG_ DI_a023_carNotParked : 22|1@1+ (1,0) [0|1] "" Vector__XXX
 SG_ DI_a024_holdNForNeutral : 23|1@1+ (1,0) [0|1] "" Vector__XXX
 SG_ DI_a025_regenBackfillUnavailable : 24|1@1+ (1,0) [0|1] "" Vector__XXX
 SG_ DI_a026_parkPressedWithHighAPeda : 25|1@1+ (1,0) [0|1] "" Vector__XXX
 SG_ DI_a031_closureAccelerationLimit : 30|1@1+ (1,0) [0|1] "" Vector__XXX
 SG_ DI_a036_sysStandbyUnitLimitedWai : 35|1@1+ (1,0) [0|1] "" Vector__XXX
 SG_ DI_a038_idleTaskStarving : 37|1@1+ (1,0) [0|1] "" Vector__XXX
 SG_ DI_a039_exceptionUndefinedInstru : 38|1@1+ (1,0) [0|1] "" Vector__XXX
 SG_ DI_a040_difMIA : 39|1@1+ (1,0) [0|1] "" Vector__XXX
 SG_ DI_a041_driverBrakeApplyStuck : 40|1@1+ (1,0) [0|1] "" Vector__XXX
 SG_ DI_a042_pmfMIA : 41|1@1+ (1,0) [0|1] "" Vector__XXX
 SG_ DI_a043_pmrMIA : 42|1@1+ (1,0) [0|1] "" Vector__XXX
 SG_ DI_a048_ecuLogAvailable : 47|1@1+ (1,0) [0|1] "" Vector__XXX
 SG_ DI_a049_P0632_DI_ECU_OdometerNot : 48|1@1+ (1,0) [0|1] "" Vector__XXX
 SG_ DI_a050_P1234_DI_ECU_DemoTimer : 49|1@1+ (1,0) [0|1] "" Vector__XXX
 SG_ DI_a051_batteryOvercurrent : 50|1@1+ (1,0) [0|1] "" Vector__XXX
 SG_ DI_a052_dirMIA : 51|1@1+ (1,0) [0|1] "" Vector__XXX
 SG_ DI_a053_canDataBusC : 52|1@1+ (1,0) [0|1] "" Vector__XXX
 SG_ DI_a054_canOverrunBusC : 53|1@1+ (1,0) [0|1] "" Vector__XXX
 SG_ DI_a055_canHardwareBusC : 54|1@1+ (1,0) [0|1] "" Vector__XXX
 SG_ DI_a056_canDataBusD : 55|1@1+ (1,0) [0|1] "" Vector__XXX
 SG_ DI_a057_canOverrunBusD : 56|1@1+ (1,0) [0|1] "" Vector__XXX
 SG_ DI_a058_canHardwareBusD : 57|1@1+ (1,0) [0|1] "" Vector__XXX
 SG_ DI_a059_canDataBusE : 58|1@1+ (1,0) [0|1] "" Vector__XXX
 SG_ DI_a060_canOverrunBusE : 59|1@1+ (1,0) [0|1] "" Vector__XXX
 SG_ DI_a061_canHardwareBusE : 60|1@1+ (1,0) [0|1] "" Vector__XXX
 SG_ DI_a062_systemLimpMode : 61|1@1+ (1,0) [0|1] "" Vector__XXX
 SG_ DI_a063_systemGracefulPowerOff : 62|1@1+ (1,0) [0|1] "" Vector__XXX
 SG_ DI_a064_pmsrmUnitMiaWithHvDown : 63|1@1+ (1,0) [0|1] "" Vector__XXX

BO_ 872 DI_alertMatrix2: 8 DI
 SG_ DI_a065_canHardwareBusB : 0|1@1+ (1,0) [0|1] "" Vector__XXX
 SG_ DI_a066_canDataBusB : 1|1@1+ (1,0) [0|1] "" Vector__XXX
 SG_ DI_a067_canOverrunBusB : 2|1@1+ (1,0) [0|1] "" Vector__XXX
 SG_ DI_a068_secondaryWheelSpeedIrrat : 3|1@1+ (1,0) [0|1] "" Vector__XXX
 SG_ DI_a069_P1234_DI_ECU_DemoWindow : 4|1@1+ (1,0) [0|1] "" Vector__XXX
 SG_ DI_a070_udsTransactionInitiated : 5|1@1+ (1,0) [0|1] "" Vector__XXX
 SG_ DI_a076_lvSupplyOV : 11|1@1+ (1,0) [0|1] "" Vector__XXX
 SG_ DI_a077_lvSupplyUV : 12|1@1+ (1,0) [0|1] "" Vector__XXX
 SG_ DI_a078_adcRefLow : 13|1@1+ (1,0) [0|1] "" Vector__XXX
 SG_ DI_a079_adcRefHigh : 14|1@1+ (1,0) [0|1] "" Vector__XXX
 SG_ DI_a080_accelSynch : 15|1@1+ (1,0) [0|1] "" Vector__XXX
 SG_ DI_a081_accelTrack1 : 16|1@1+ (1,0) [0|1] "" Vector__XXX
 SG_ DI_a082_accelTrack2 : 17|1@1+ (1,0) [0|1] "" Vector__XXX
 SG_ DI_a083_brakePedalSensor : 18|1@1+ (1,0) [0|1] "" Vector__XXX
 SG_ DI_a084_eccTestData0 : 19|1@1+ (1,0) [0|1] "" Vector__XXX
 SG_ DI_a085_proximityInEnable : 20|1@1+ (1,0) [0|1] "" Vector__XXX
 SG_ DI_a086_dpbMIA : 21|1@1+ (1,0) [0|1] "" Vector__XXX
 SG_ DI_a087_gtwMIA : 22|1@1+ (1,0) [0|1] "" Vector__XXX
 SG_ DI_a088_uiMIA : 23|1@1+ (1,0) [0|1] "" Vector__XXX
 SG_ DI_a089_sccmMIA : 24|1@1+ (1,0) [0|1] "" Vector__XXX
 SG_ DI_a090_pmMIA : 25|1@1+ (1,0) [0|1] "" Vector__XXX
 SG_ DI_a091_espMIA : 26|1@1+ (1,0) [0|1] "" Vector__XXX
 SG_ DI_a092_bmsMIA : 27|1@1+ (1,0) [0|1] "" Vector__XXX
 SG_ DI_a093_canHardwareBusA : 28|1@1+ (1,0) [0|1] "" Vector__XXX
 SG_ DI_a094_canDataBusA : 29|1@1+ (1,0) [0|1] "" Vector__XXX
 SG_ DI_a095_canOverrunBusA : 30|1@1+ (1,0) [0|1] "" Vector__XXX
 SG_ DI_a096_memoryError : 31|1@1+ (1,0) [0|1] "" Vector__XXX
 SG_ DI_a097_eepromError : 32|1@1+ (1,0) [0|1] "" Vector__XXX
 SG_ DI_a098_eepromManagerError : 33|1@1+ (1,0) [0|1] "" Vector__XXX
 SG_ DI_a099_threadOverrun : 34|1@1+ (1,0) [0|1] "" Vector__XXX
 SG_ DI_a100_nvramError : 35|1@1+ (1,0) [0|1] "" Vector__XXX
 SG_ DI_a101_eccTestData1 : 36|1@1+ (1,0) [0|1] "" Vector__XXX
 SG_ DI_a102_exceptionPrefetchAbort : 37|1@1+ (1,0) [0|1] "" Vector__XXX
 SG_ DI_a103_bbMIA : 38|1@1+ (1,0) [0|1] "" Vector__XXX
 SG_ DI_a104_proximityIrrational : 39|1@1+ (1,0) [0|1] "" Vector__XXX
 SG_ DI_a105_cpMIA : 40|1@1+ (1,0) [0|1] "" Vector__XXX
 SG_ DI_a108_appMIA : 43|1@1+ (1,0) [0|1] "" Vector__XXX
 SG_ DI_a109_ahbWriteError : 44|1@1+ (1,0) [0|1] "" Vector__XXX
 SG_ DI_a110_brakeMIA : 45|1@1+ (1,0) [0|1] "" Vector__XXX
 SG_ DI_a112_accelTrack1Incons : 47|1@1+ (1,0) [0|1] "" Vector__XXX
 SG_ DI_a114_exceptionDataAbort : 49|1@1+ (1,0) [0|1] "" Vector__XXX
 SG_ DI_a115_exceptionDataAbort2 : 50|1@1+ (1,0) [0|1] "" Vector__XXX
 SG_ DI_a116_motorRecovered : 51|1@1+ (1,0) [0|1] "" Vector__XXX
 SG_ DI_a117_latentFaultCheckTripped : 52|1@1+ (1,0) [0|1] "" Vector__XXX
 SG_ DI_a118_diImmobilizedForFactoryF : 53|1@1+ (1,0) [0|1] "" Vector__XXX
 SG_ DI_a119_latentFaultCheckFailedOn : 54|1@1+ (1,0) [0|1] "" Vector__XXX
 SG_ DI_a120_regenBlendingUnavailable : 55|1@1+ (1,0) [0|1] "" Vector__XXX
 SG_ DI_a121_qualifiedBrakeEventMitig : 56|1@1+ (1,0) [0|1] "" Vector__XXX
 SG_ DI_a122_highStackUsage : 57|1@1+ (1,0) [0|1] "" Vector__XXX
 SG_ DI_a124_cruiseFault : 59|1@1+ (1,0) [0|1] "" Vector__XXX
 SG_ DI_a125_noBatteryPower : 60|1@1+ (1,0) [0|1] "" Vector__XXX

BO_ 875 DI_alertMatrix3: 8 DI
 SG_ DI_a129_epbNotApplied : 0|1@1+ (1,0) [0|1] "" Vector__XXX
 SG_ DI_a130_aebFault : 1|1@1+ (1,0) [0|1] "" Vector__XXX
 SG_ DI_a131_highSpeedWearLimit : 2|1@1+ (1,0) [0|1] "" Vector__XXX
 SG_ DI_a133_vehicleHoldTimedOut : 4|1@1+ (1,0) [0|1] "" Vector__XXX
 SG_ DI_a134_wheelSpeedIrrational : 5|1@1+ (1,0) [0|1] "" Vector__XXX
 SG_ DI_a135_vehicleHoldFault : 6|1@1+ (1,0) [0|1] "" Vector__XXX
 SG_ DI_a137_noCapableDriveUnits : 8|1@1+ (1,0) [0|1] "" Vector__XXX
 SG_ DI_a138_frontUnitDisabled : 9|1@1+ (1,0) [0|1] "" Vector__XXX
 SG_ DI_a139_rearUnitDisabled : 10|1@1+ (1,0) [0|1] "" Vector__XXX
 SG_ DI_a140_ptcMIA : 11|1@1+ (1,0) [0|1] "" Vector__XXX
 SG_ DI_a141_dasMIA : 12|1@1+ (1,0) [0|1] "" Vector__XXX
 SG_ DI_a142_potholeDetected : 13|1@1+ (1,0) [0|1] "" Vector__XXX
 SG_ DI_a143_mcuLimitActive : 14|1@1+ (1,0) [0|1] "" Vector__XXX
 SG_ DI_a144_configMismatch : 15|1@1+ (1,0) [0|1] "" Vector__XXX
 SG_ DI_a146_pbrkPanicEpbFault : 17|1@1+ (1,0) [0|1] "" Vector__XXX
 SG_ DI_a154_vdcRearSteering : 25|1@1+ (1,0) [0|1] "" Vector__XXX
 SG_ DI_a155_vcfrontMIA : 26|1@1+ (1,0) [0|1] "" Vector__XXX
 SG_ DI_a157_rcmMIA : 28|1@1+ (1,0) [0|1] "" Vector__XXX
 SG_ DI_a158_ibstMIA : 29|1@1+ (1,0) [0|1] "" Vector__XXX
 SG_ DI_a159_cruiseSelfCheck : 30|1@1+ (1,0) [0|1] "" Vector__XXX
 SG_ DI_a160_fastLearnComplete : 31|1@1+ (1,0) [0|1] "" Vector__XXX
 SG_ DI_a161_epas3pMIA : 32|1@1+ (1,0) [0|1] "" Vector__XXX
 SG_ DI_a162_shiftDenied : 33|1@1+ (1,0) [0|1] "" Vector__XXX
 SG_ DI_a163_shiftMotorSpeed : 34|1@1+ (1,0) [0|1] "" Vector__XXX
 SG_ DI_a164_brakeOverride : 35|1@1+ (1,0) [0|1] "" Vector__XXX
 SG_ DI_a165_cruiseCancelled : 36|1@1+ (1,0) [0|1] "" Vector__XXX
 SG_ DI_a166_driverLeft : 37|1@1+ (1,0) [0|1] "" Vector__XXX
 SG_ DI_a167_keyNotAuthenticated : 38|1@1+ (1,0) [0|1] "" Vector__XXX
 SG_ DI_a168_proximityDriveDenial : 39|1@1+ (1,0) [0|1] "" Vector__XXX
 SG_ DI_a169_regenOffOverride : 40|1@1+ (1,0) [0|1] "" Vector__XXX
 SG_ DI_a170_tireConfigUpdated : 41|1@1+ (1,0) [0|1] "" Vector__XXX
 SG_ DI_a171_driveRailNotRequested : 42|1@1+ (1,0) [0|1] "" Vector__XXX
 SG_ DI_a172_accelPressedInNP : 43|1@1+ (1,0) [0|1] "" Vector__XXX
 SG_ DI_a173_bothPedalsPressed : 44|1@1+ (1,0) [0|1] "" Vector__XXX
 SG_ DI_a174_notOkToStartDrive : 45|1@1+ (1,0) [0|1] "" Vector__XXX
 SG_ DI_a175_crsNotAvailable : 46|1@1+ (1,0) [0|1] "" Vector__XXX
 SG_ DI_a176_EBRreleased : 47|1@1+ (1,0) [0|1] "" Vector__XXX
 SG_ DI_a177_tireFitmentChanged : 48|1@1+ (1,0) [0|1] "" Vector__XXX
 SG_ DI_a178_steeringAngleOffsetFault : 49|1@1+ (1,0) [0|1] "" Vector__XXX
 SG_ DI_a179_steeringAngleOffsetWarni : 50|1@1+ (1,0) [0|1] "" Vector__XXX
 SG_ DI_a180_crsSeatbeltUnbuckled : 51|1@1+ (1,0) [0|1] "" Vector__XXX
 SG_ DI_a181_rearMotorMode : 52|1@1+ (1,0) [0|1] "" Vector__XXX
 SG_ DI_a182_frontMotorMode : 53|1@1+ (1,0) [0|1] "" Vector__XXX
 SG_ DI_a183_holdReleaseRqrd : 54|1@1+ (1,0) [0|1] "" Vector__XXX
 SG_ DI_a184_autoparkCanceled : 55|1@1+ (1,0) [0|1] "" Vector__XXX
 SG_ DI_a185_autoparkAborted : 56|1@1+ (1,0) [0|1] "" Vector__XXX
 SG_ DI_a186_brakeStand : 57|1@1+ (1,0) [0|1] "" Vector__XXX
 SG_ DI_a187_pedalMisapplication : 58|1@1+ (1,0) [0|1] "" Vector__XXX
 SG_ DI_a188_tireRotationRecommendedG : 59|1@1+ (1,0) [0|1] "" Vector__XXX
 SG_ DI_a189_garageShiftWithPedal : 60|1@1+ (1,0) [0|1] "" Vector__XXX
 SG_ DI_a190_tireRotationRecommended : 61|1@1+ (1,0) [0|1] "" Vector__XXX
 SG_ DI_a191_brakeShiftReq : 62|1@1+ (1,0) [0|1] "" Vector__XXX
 SG_ DI_a192_invalidOdometer : 63|1@1+ (1,0) [0|1] "" Vector__XXX

BO_ 878 DI_alertMatrix4: 8 DI
 SG_ DI_a193_vdcBrakeTorqueFr : 0|1@1+ (1,0) [0|1] "" Vector__XXX
 SG_ DI_a194_vdcBrakeTorqueRe : 1|1@1+ (1,0) [0|1] "" Vector__XXX
 SG_ DI_a195_vdcEspSlipFr : 2|1@1+ (1,0) [0|1] "" Vector__XXX
 SG_ DI_a196_vdcEspSlipRe : 3|1@1+ (1,0) [0|1] "" Vector__XXX
 SG_ DI_a197_vdcEspWheelSaturations : 4|1@1+ (1,0) [0|1] "" Vector__XXX
 SG_ DI_a198_vdcEspMCPressAndSteering : 5|1@1+ (1,0) [0|1] "" Vector__XXX
 SG_ DI_a199_vdcFaulted : 6|1@1+ (1,0) [0|1] "" Vector__XXX
 SG_ DI_a200_vdcModelBasedPlausibilit : 7|1@1+ (1,0) [0|1] "" Vector__XXX
 SG_ DI_a201_decelTorqueLimited : 8|1@1+ (1,0) [0|1] "" Vector__XXX
 SG_ DI_a202_excessHeatUnavailable : 9|1@1+ (1,0) [0|1] "" Vector__XXX
 SG_ DI_a203_TCReducedByADD : 10|1@1+ (1,0) [0|1] "" Vector__XXX
 SG_ DI_a204_vdcRcmLongitudinal : 11|1@1+ (1,0) [0|1] "" Vector__XXX
 SG_ DI_a205_vdcRcmLateral : 12|1@1+ (1,0) [0|1] "" Vector__XXX
 SG_ DI_a206_vdcRcmVertical : 13|1@1+ (1,0) [0|1] "" Vector__XXX
 SG_ DI_a207_vdcPowertrainTorque_dif : 14|1@1+ (1,0) [0|1] "" Vector__XXX
 SG_ DI_a208_vdcPowertrainTorque_dir : 15|1@1+ (1,0) [0|1] "" Vector__XXX
 SG_ DI_a210_vdcOtherControllerStates : 17|1@1+ (1,0) [0|1] "" Vector__XXX
 SG_ DI_a211_vdcMotorSpeed_dif : 18|1@1+ (1,0) [0|1] "" Vector__XXX
 SG_ DI_a212_vdcWheelRotations : 19|1@1+ (1,0) [0|1] "" Vector__XXX
 SG_ DI_a213_lowMuProbabilityChange : 20|1@1+ (1,0) [0|1] "" Vector__XXX
 SG_ DI_a214_vdcWheelSpeedFr : 21|1@1+ (1,0) [0|1] "" Vector__XXX
 SG_ DI_a215_vdcWheelSpeedRe : 22|1@1+ (1,0) [0|1] "" Vector__XXX
 SG_ DI_a216_vdcMBPAlmostTripped : 23|1@1+ (1,0) [0|1] "" Vector__XXX
 SG_ DI_a217_vdcOutputIrrational : 24|1@1+ (1,0) [0|1] "" Vector__XXX
 SG_ DI_a218_vdcOSPreControlActive : 25|1@1+ (1,0) [0|1] "" Vector__XXX
 SG_ DI_a219_vdcOversteerdMzActive : 26|1@1+ (1,0) [0|1] "" Vector__XXX
 SG_ DI_a220_vdcUndersteerDecelActive : 27|1@1+ (1,0) [0|1] "" Vector__XXX
 SG_ DI_a221_vdcUndersteerdMzActive : 28|1@1+ (1,0) [0|1] "" Vector__XXX
 SG_ DI_a222_vdcDisabled : 29|1@1+ (1,0) [0|1] "" Vector__XXX
 SG_ DI_a223_tractionControlDisabled : 30|1@1+ (1,0) [0|1] "" Vector__XXX
 SG_ DI_a224_brakeOverTemp : 31|1@1+ (1,0) [0|1] "" Vector__XXX
 SG_ DI_a225_vyEstimatorDegradedDebug : 32|1@1+ (1,0) [0|1] "" Vector__XXX
 SG_ DI_a226_sysStartConditionNotMet : 33|1@1+ (1,0) [0|1] "" Vector__XXX
 SG_ DI_a227_contactorsNotClosed : 34|1@1+ (1,0) [0|1] "" Vector__XXX
 SG_ DI_a228_brakeTempEstUnavailable : 35|1@1+ (1,0) [0|1] "" Vector__XXX
 SG_ DI_a230_cmpMIA : 37|1@1+ (1,0) [0|1] "" Vector__XXX
 SG_ DI_a231_unintendedReset2 : 38|1@1+ (1,0) [0|1] "" Vector__XXX
 SG_ DI_a232_velocityEstimatorDegrade : 39|1@1+ (1,0) [0|1] "" Vector__XXX
 SG_ DI_a233_frontWheelImpactDetected : 40|1@1+ (1,0) [0|1] "" Vector__XXX
 SG_ DI_a235_trackModeActive : 42|1@1+ (1,0) [0|1] "" Vector__XXX
 SG_ DI_a236_tasMIA : 43|1@1+ (1,0) [0|1] "" Vector__XXX
 SG_ DI_a237_undersideAbuse : 44|1@1+ (1,0) [0|1] "" Vector__XXX
 SG_ DI_a238_secondaryCollisionMitiga : 45|1@1+ (1,0) [0|1] "" Vector__XXX
 SG_ DI_a239_neutralRequestByPM : 46|1@1+ (1,0) [0|1] "" Vector__XXX
 SG_ DI_a240_torqueSplitStuck : 47|1@1+ (1,0) [0|1] "" Vector__XXX
 SG_ DI_a241_vdcMotorSpeed_dir : 48|1@1+ (1,0) [0|1] "" Vector__XXX
 SG_ DI_a242_vdcTrailerSwayDetected : 49|1@1+ (1,0) [0|1] "" Vector__XXX
 SG_ DI_a243_rcuMIA : 50|1@1+ (1,0) [0|1] "" Vector__XXX
 SG_ DI_a244_vseRLSMassMismatch : 51|1@1+ (1,0) [0|1] "" Vector__XXX
 SG_ DI_a245_opdReducedWithoutEbr : 52|1@1+ (1,0) [0|1] "" Vector__XXX
 SG_ DI_a246_opdUnavailable : 53|1@1+ (1,0) [0|1] "" Vector__XXX
 SG_ DI_a248_vdcPreControlHighDynamic : 55|1@1+ (1,0) [0|1] "" Vector__XXX
 SG_ DI_a249_spinDownLearningInProgre : 56|1@1+ (1,0) [0|1] "" Vector__XXX
 SG_ DI_a250_tasSpeedLimitActive : 57|1@1+ (1,0) [0|1] "" Vector__XXX
 SG_ DI_a251_diPowerOnStateMismatch : 58|1@1+ (1,0) [0|1] "" Vector__XXX
 SG_ DI_a253_accelSynchWarn : 60|1@1+ (1,0) [0|1] "" Vector__XXX
 SG_ DI_a254_vehicleStuckDetected : 61|1@1+ (1,0) [0|1] "" Vector__XXX

BO_ 328 DI_chassisControl: 8 DI
 SG_ DI_chassisControlChecksum : 0|8@1+ (1,0) [0|255] "" Vector__XXX
 SG_ DI_chassisControlCounter : 8|4@1+ (1,0) [0|15] "" Vector__XXX
 SG_ DI_imuOffsetLearnRequest : 12|2@1+ (1,0) [0|3] "" Vector__XXX
 SG_ DI_brakeCommandType : 14|1@1+ (1,0) [0|1] "" Vector__XXX
 SG_ DI_brakeTorqueRequestActive : 15|1@1+ (1,0) [0|1] "" Vector__XXX
 SG_ DI_brakeTorqueCommand : 16|13@1+ (3,0) [0|24573] "Nm" Vector__XXX
 SG_ DI_ptcStateGlobal : 29|2@1+ (1,0) [0|2] "" Vector__XXX
 SG_ DI_ptcActive : 31|1@1+ (1,0) [0|1] "" Vector__XXX
 SG_ DI_vdcState : 32|2@1+ (1,0) [0|3] "" Vector__XXX
 SG_ DI_isAnyVdcControlActive : 34|2@1+ (1,0) [0|3] "" Vector__XXX
 SG_ DI_vdcMode : 36|2@1+ (1,0) [0|3] "" Vector__XXX
 SG_ DI_pedalAssistCurveSelect : 38|4@1+ (1,0) [0|15] "" Vector__XXX
 SG_ DI_isAnyTcActive : 42|1@1+ (1,0) [0|1] "" Vector__XXX
 SG_ DI_VehicleMuConfidence : 43|6@1+ (0.02,0) [0|1.26] "-" Vector__XXX
 SG_ DI_VehicleMu : 49|6@1+ (0.024,0) [0|1.512] "-" Vector__XXX
 SG_ DI_trailerSwayIndex : 55|5@1+ (0.035,0) [0|1] "-" Vector__XXX
 SG_ DI_vdcControlActive : 60|3@1+ (1,0) [0|7] "" Vector__XXX
 SG_ DI_treadDepthAlertSet : 63|1@1+ (1,0) [0|1] "" Vector__XXX

BO_ 1861 DI_chassisControl2: 8 DI
 SG_ DI_gradeAngle : 0|6@1- (0.01,0) [-0.3125|0.31] "rad" Vector__XXX
 SG_ DI_bankAngle : 6|6@1- (0.01,0) [-0.3125|0.31] "rad" Vector__XXX
 SG_ DI_chassisControlVideoRequest : 12|4@1+ (1,0) [0|15] "" Vector__XXX
 SG_ DI_tireUtilizationRatioFrL : 17|5@1+ (0.0625,0) [0|1.9375] "-" Vector__XXX
 SG_ DI_tireUtilizationRatioFrR : 22|5@1+ (0.0625,0) [0|1.9375] "-" Vector__XXX
 SG_ DI_tireUtilizationRatioReL : 27|5@1+ (0.0625,0) [0|1.9375] "-" Vector__XXX
 SG_ DI_tireUtilizationRatioReR : 32|5@1+ (0.0625,0) [0|1.9375] "-" Vector__XXX
 SG_ DI_counterSteerTarget : 37|2@1+ (1,0) [0|3] "" Vector__XXX
 SG_ DI_splitMuProbability : 39|2@1+ (0.334,0) [0|1] "-" Vector__XXX
 SG_ DI_mzError : 41|2@1+ (1667,0) [0|5000] "Nm" Vector__XXX
 SG_ DI_slipDifferenceFrontRear : 43|3@1- (0.133,0) [-0.52|0.399] "rad" Vector__XXX
 SG_ DI_highFreqYawRate : 46|2@1+ (0.334,0) [0|1] "-" Vector__XXX
 SG_ DI_turnDirection : 48|1@1+ (1,0) [0|1] "" Vector__XXX
 SG_ DI_absolutePreControlRequest : 49|2@1+ (5000,0) [0|15000] "Nm" Vector__XXX
 SG_ DI_oppositeBuildDirFrontAxle : 51|1@1+ (1,0) [0|1] "" Vector__XXX
 SG_ DI_oppositeBuildDirRearAxle : 52|1@1+ (1,0) [0|1] "" Vector__XXX
 SG_ DI_saturatedEffectiveness : 53|1@1+ (1,0) [0|1] "" Vector__XXX
 SG_ DI_driverPanicIndex : 54|2@1+ (0.334,0) [0|1] "-" Vector__XXX
 SG_ DI_learnDownMu : 56|2@1+ (0.334,0) [0|1] "mu" Vector__XXX
 SG_ DI_preControlOpposingTurnDir : 58|1@1+ (1,0) [0|1] "" Vector__XXX
 SG_ DI_driverFxError : 59|2@1+ (1000,0) [0|3000] "N" Vector__XXX
 SG_ DI_targetSaturation : 61|3@1+ (0.572,0) [0|4] "G" Vector__XXX

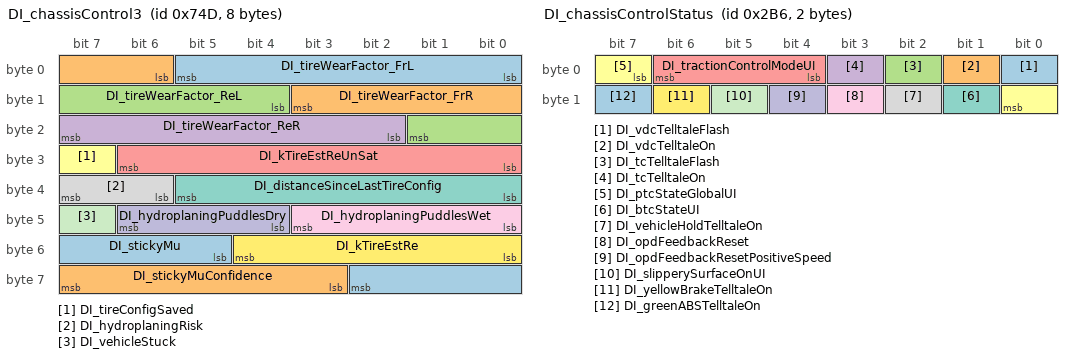
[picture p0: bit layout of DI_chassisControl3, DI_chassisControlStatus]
BO_ 1869 DI_chassisControl3: 8 DI
 SG_ DI_tireWearFactor_FrL : 0|6@1+ (0.00125,0.96) [0.96|1.03875] "ratio" Vector__XXX
 SG_ DI_tireWearFactor_FrR : 6|6@1+ (0.00125,0.96) [0.96|1.03875] "ratio" Vector__XXX
 SG_ DI_tireWearFactor_ReL : 12|6@1+ (0.00125,0.96) [0.96|1.03875] "ratio" Vector__XXX
 SG_ DI_tireWearFactor_ReR : 18|6@1+ (0.00125,0.96) [0.96|1.03875] "ratio" Vector__XXX
 SG_ DI_kTireEstReUnSat : 24|7@1+ (0.001,0.008) [0.008|0.075] "-" Vector__XXX
 SG_ DI_tireConfigSaved : 31|1@1+ (1,0) [0|1] "" Vector__XXX
 SG_ DI_distanceSinceLastTireConfig : 32|6@1+ (500,0) [0|31000] "km" Vector__XXX
 SG_ DI_hydroplaningRisk : 38|2@1+ (0.333333343267,0) [0|1] "-" Vector__XXX
 SG_ DI_hydroplaningPuddlesWet : 40|4@1+ (1,0) [0|15] "-" Vector__XXX
 SG_ DI_hydroplaningPuddlesDry : 44|3@1+ (1,0) [0|7] "-" Vector__XXX
 SG_ DI_vehicleStuck : 47|1@1+ (1,0) [0|1] "" Vector__XXX
 SG_ DI_kTireEstRe : 48|5@1+ (0.001,0.03) [0.03|0.06] "-" Vector__XXX
 SG_ DI_stickyMu : 53|6@1+ (0.025,0) [0|1.575] "-" Vector__XXX
 SG_ DI_stickyMuConfidence : 59|5@1+ (0.1,0) [0|3] "probability" Vector__XXX

BO_ 694 DI_chassisControlStatus: 2 DI
 SG_ DI_vdcTelltaleFlash : 0|1@1+ (1,0) [0|1] "" Vector__XXX
 SG_ DI_vdcTelltaleOn : 1|1@1+ (1,0) [0|1] "" Vector__XXX
 SG_ DI_tcTelltaleFlash : 2|1@1+ (1,0) [0|1] "" Vector__XXX
 SG_ DI_tcTelltaleOn : 3|1@1+ (1,0) [0|1] "" Vector__XXX
 SG_ DI_tractionControlModeUI : 4|3@1+ (1,0) [0|7] "" Vector__XXX
 SG_ DI_ptcStateGlobalUI : 7|2@1+ (1,0) [0|2] "" Vector__XXX
 SG_ DI_btcStateUI : 9|1@1+ (1,0) [0|1] "" Vector__XXX
 SG_ DI_vehicleHoldTelltaleOn : 10|1@1+ (1,0) [0|1] "" Vector__XXX
 SG_ DI_opdFeedbackReset : 11|1@1+ (1,0) [0|1] "" Vector__XXX
 SG_ DI_opdFeedbackResetPositiveSpeed : 12|1@1+ (1,0) [0|1] "" Vector__XXX
 SG_ DI_slipperySurfaceOnUI : 13|1@1+ (1,0) [0|1] "" Vector__XXX
 SG_ DI_yellowBrakeTelltaleOn : 14|1@1+ (1,0) [0|1] "" Vector__XXX
 SG_ DI_greenABSTelltaleOn : 15|1@1+ (1,0) [0|1] "" Vector__XXX

BO_ 2007 DI_debug: 8 DI
 SG_ DI_debugSelector M : 0|8@1+ (1,0) [0|255] "" Vector__XXX
 SG_ DI_regenBackfillCmd m39 : 8|13@1+ (2,0) [0|16382] "Nm" Vector__XXX
 SG_ DI_regenBackfillUnavailableReaso m39 : 21|5@1+ (1,0) [0|31] "" Vector__XXX
 SG_ DI_regenBackfillAbsSatState m39 : 26|2@1+ (1,0) [0|3] "" Vector__XXX
 SG_ DI_sysHeatPowerOptimal m50 : 8|8@1+ (0.08,0) [0|20] "kW" Vector__XXX
 SG_ DI_sysPostPedalMinTorque m53 : 8|15@1+ (0.5,-13000) [-13000|0] "Nm" Vector__XXX
 SG_ DI_sysPostPedalMaxTorque m53 : 24|15@1+ (0.5,0) [0|13000] "Nm" Vector__XXX
 SG_ DI_systemTorqueCommand m53 : 40|16@1- (0.5,0) [-13000|13000] "Nm" Vector__XXX

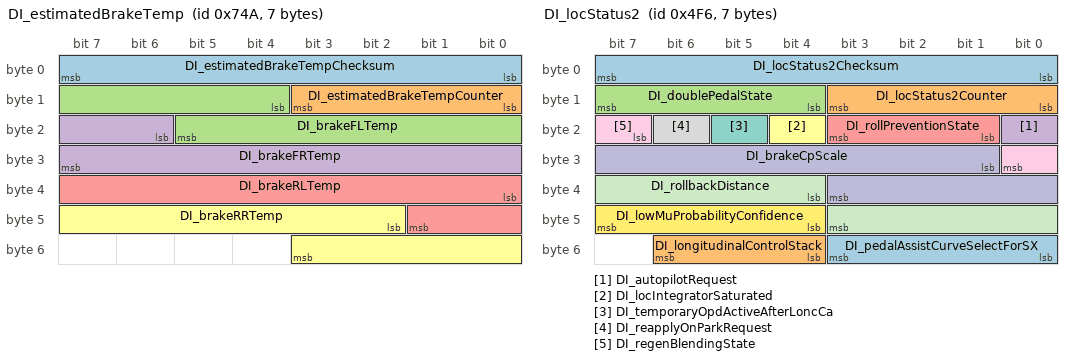
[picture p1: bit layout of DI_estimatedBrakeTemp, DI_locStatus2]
BO_ 1866 DI_estimatedBrakeTemp: 7 DI
 SG_ DI_estimatedBrakeTempChecksum : 0|8@1+ (1,0) [0|255] "" Vector__XXX
 SG_ DI_estimatedBrakeTempCounter : 8|4@1+ (1,0) [0|15] "" Vector__XXX
 SG_ DI_brakeFLTemp : 12|10@1+ (1,-40) [-40|982] "DegC" Vector__XXX
 SG_ DI_brakeFRTemp : 22|10@1+ (1,-40) [-40|982] "DegC" Vector__XXX
 SG_ DI_brakeRLTemp : 32|10@1+ (1,-40) [-40|982] "DegC" Vector__XXX
 SG_ DI_brakeRRTemp : 42|10@1+ (1,-40) [-40|982] "DegC" Vector__XXX

BO_ 1623 DI_info: 8 DI
 SG_ DI_infoIndex M : 0|8@1+ (1,0) [0|255] "" Vector__XXX
 SG_ DI_buildType m10 : 8|3@1+ (1,0) [0|7] "" Vector__XXX
 SG_ DI_buildConfigurationId m10 : 16|16@1+ (1,0) [0|65535] "" Vector__XXX
 SG_ DI_hardwareId m10 : 32|8@1+ (1,0) [0|252] "" Vector__XXX
 SG_ DI_componentId m10 : 48|16@1+ (1,0) [0|65535] "" Vector__XXX
 SG_ DI_pcbaId m11 : 16|8@1+ (1,0) [0|255] "" Vector__XXX
 SG_ DI_assemblyId m11 : 24|8@1+ (1,0) [0|255] "" Vector__XXX
 SG_ DI_usageId m11 : 32|16@1+ (1,0) [0|65535] "" Vector__XXX
 SG_ DI_subUsageId m11 : 48|16@1+ (1,0) [0|65535] "" Vector__XXX
 SG_ DI_applicationCrc m13 : 32|32@1+ (1,0) [0|4294967295] "" Vector__XXX
 SG_ DI_bootGitHash m18 : 8|56@1+ (1,0) [0|7.20575940379e+16] "" Vector__XXX

BO_ 646 DI_locStatus: 8 DI
 SG_ DI_locStatusChecksum : 0|8@1+ (1,0) [0|255] "" Vector__XXX
 SG_ DI_locStatusCounter : 8|4@1+ (1,0) [0|15] "" Vector__XXX
 SG_ DI_cruiseState : 12|3@1+ (1,0) [0|7] "" Vector__XXX
 SG_ DI_cruiseSetSpeed : 15|9@1+ (0.5,0) [0|255.5] "speed" Vector__XXX
 SG_ DI_cruiseSetSpeedUnits : 24|1@1+ (1,0) [0|1] "" Vector__XXX
 SG_ DI_autoparkState : 25|4@1+ (1,0) [0|14] "" Vector__XXX
 SG_ DI_parkBrakeState : 29|4@1+ (1,0) [0|14] "" Vector__XXX
 SG_ DI_aebState : 33|3@1+ (1,0) [0|6] "" Vector__XXX
 SG_ DI_loncDeactivationReason : 36|2@1+ (1,0) [0|3] "" Vector__XXX
 SG_ DI_vehicleHoldState : 38|3@1+ (1,0) [0|7] "" Vector__XXX
 SG_ DI_summonInPanic : 41|1@1+ (1,0) [0|1] "" Vector__XXX
 SG_ DI_onePedalDrivingState : 42|4@1+ (1,0) [0|15] "" Vector__XXX
 SG_ DI_brakeStandActive : 46|1@1+ (1,0) [0|1] "" Vector__XXX
 SG_ DI_regenBackfillState : 47|2@1+ (1,0) [0|3] "" Vector__XXX
 SG_ DI_cruiseNotAvailableReason : 49|6@1+ (1,0) [0|63] "" Vector__XXX
 SG_ DI_cruiseFaultReason : 55|5@1+ (1,0) [0|31] "" Vector__XXX
 SG_ DI_cruiseCancelReason : 60|4@1+ (1,0) [0|15] "" Vector__XXX

BO_ 1270 DI_locStatus2: 7 DI
 SG_ DI_locStatus2Checksum : 0|8@1+ (1,0) [0|255] "" Vector__XXX
 SG_ DI_locStatus2Counter : 8|4@1+ (1,0) [0|15] "" Vector__XXX
 SG_ DI_doublePedalState : 12|4@1+ (1,0) [0|15] "" Vector__XXX
 SG_ DI_autopilotRequest : 16|1@1+ (1,0) [0|1] "" Vector__XXX
 SG_ DI_rollPreventionState : 17|3@1+ (1,0) [0|7] "" Vector__XXX
 SG_ DI_locIntegratorSaturated : 20|1@1+ (1,0) [0|1] "" Vector__XXX
 SG_ DI_temporaryOpdActiveAfterLoncCa : 21|1@1+ (1,0) [0|1] "" Vector__XXX
 SG_ DI_reapplyOnParkRequest : 22|1@1+ (1,0) [0|1] "" Vector__XXX
 SG_ DI_regenBlendingState : 23|2@1+ (1,0) [0|3] "" Vector__XXX
 SG_ DI_brakeCpScale : 25|11@1+ (0.005,0) [0|10] "N/N" Vector__XXX
 SG_ DI_rollbackDistance : 36|8@1+ (0.005,0) [0|1.275] "m" Vector__XXX
 SG_ DI_lowMuProbabilityConfidence : 44|4@1+ (0.06666667,0) [0|1] "-" Vector__XXX
 SG_ DI_pedalAssistCurveSelectForSX : 48|4@1+ (1,0) [0|15] "" Vector__XXX
 SG_ DI_longitudinalControlStack : 52|3@1+ (1,0) [1|7] "" Vector__XXX

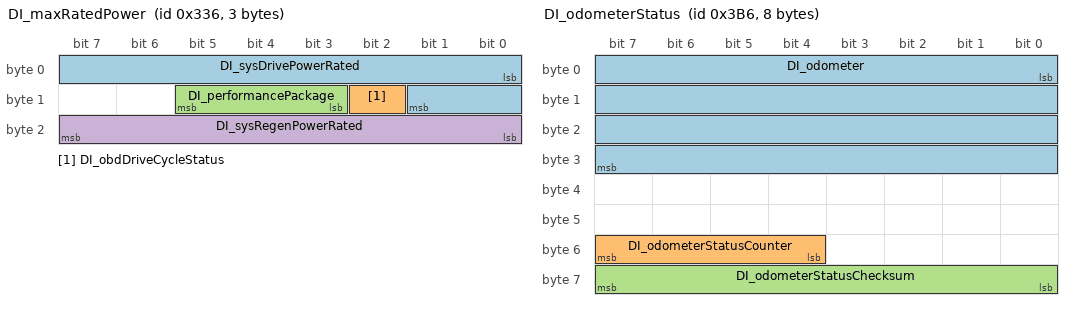
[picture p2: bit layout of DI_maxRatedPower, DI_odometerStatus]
BO_ 822 DI_maxRatedPower: 3 DI
 SG_ DI_sysDrivePowerRated : 0|10@1+ (1,0) [0|1023] "kW" Vector__XXX
 SG_ DI_obdDriveCycleStatus : 10|1@1+ (1,0) [0|1] "" Vector__XXX
 SG_ DI_performancePackage : 11|3@1+ (1,0) [0|6] "" Vector__XXX
 SG_ DI_sysRegenPowerRated : 16|8@1+ (1,-100) [-100|0] "kW" Vector__XXX

BO_ 950 DI_odometerStatus: 8 DI
 SG_ DI_odometer : 0|32@1+ (0.001,0) [0|4294967.294] "km" Vector__XXX
 SG_ DI_odometerStatusCounter : 52|4@1+ (1,0) [0|15] "" Vector__XXX
 SG_ DI_odometerStatusChecksum : 56|8@1+ (1,0) [0|255] "" Vector__XXX

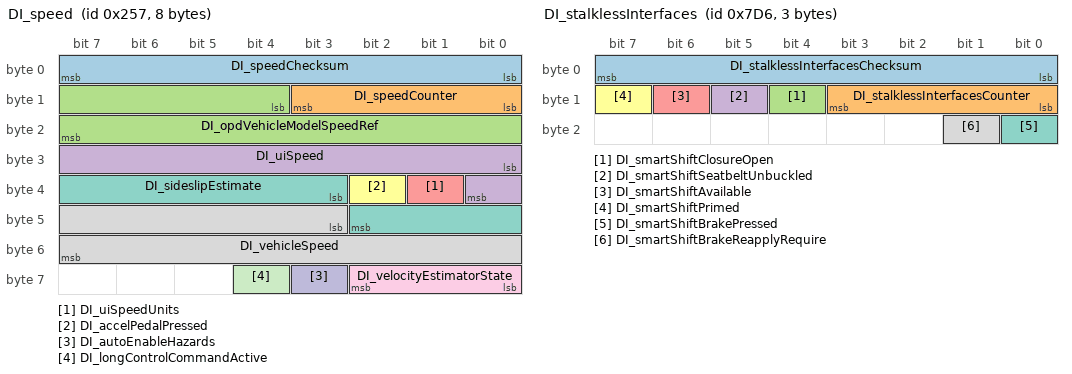
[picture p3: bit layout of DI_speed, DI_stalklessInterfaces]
BO_ 599 DI_speed: 8 DI
 SG_ DI_speedChecksum : 0|8@1+ (1,0) [0|255] "" Vector__XXX
 SG_ DI_speedCounter : 8|4@1+ (1,0) [0|15] "" Vector__XXX
 SG_ DI_opdVehicleModelSpeedRef : 12|12@1+ (0.08,-40) [-40|287.6] "kph" Vector__XXX
 SG_ DI_uiSpeed : 24|9@1+ (1,0) [0|510] "" Vector__XXX
 SG_ DI_uiSpeedUnits : 33|1@1+ (1,0) [0|1] "" Vector__XXX
 SG_ DI_accelPedalPressed : 34|1@1+ (1,0) [0|1] "" Vector__XXX
 SG_ DI_sideslipEstimate : 35|8@1- (0.0025,0) [-0.32|0.3175] "rad" Vector__XXX
 SG_ DI_vehicleSpeed : 43|13@1+ (0.08,-40) [-40|480] "kph" Vector__XXX
 SG_ DI_velocityEstimatorState : 56|3@1+ (1,0) [0|7] "" Vector__XXX
 SG_ DI_autoEnableHazards : 59|1@1+ (1,0) [0|1] "" Vector__XXX
 SG_ DI_longControlCommandActive : 60|1@1+ (1,0) [0|1] "" Vector__XXX

BO_ 2006 DI_stalklessInterfaces: 3 DI
 SG_ DI_stalklessInterfacesChecksum : 0|8@1+ (1,0) [0|255] "" Vector__XXX
 SG_ DI_stalklessInterfacesCounter : 8|4@1+ (1,0) [0|15] "" Vector__XXX
 SG_ DI_smartShiftClosureOpen : 12|1@1+ (1,0) [0|1] "" Vector__XXX
 SG_ DI_smartShiftSeatbeltUnbuckled : 13|1@1+ (1,0) [0|1] "" Vector__XXX
 SG_ DI_smartShiftAvailable : 14|1@1+ (1,0) [0|1] "" Vector__XXX
 SG_ DI_smartShiftPrimed : 15|1@1+ (1,0) [0|1] "" Vector__XXX
 SG_ DI_smartShiftBrakePressed : 16|1@1+ (1,0) [0|1] "" Vector__XXX
 SG_ DI_smartShiftBrakeReapplyRequire : 17|1@1+ (1,0) [0|1] "" Vector__XXX

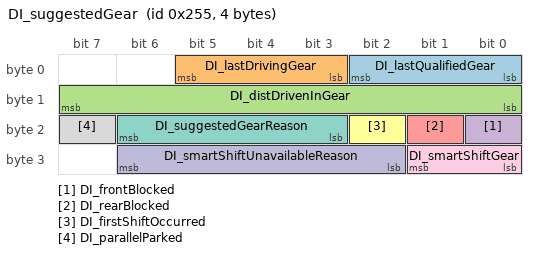
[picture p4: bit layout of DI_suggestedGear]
BO_ 597 DI_suggestedGear: 4 DI
 SG_ DI_lastQualifiedGear : 0|3@1+ (1,0) [0|6] "" Vector__XXX
 SG_ DI_lastDrivingGear : 3|3@1+ (1,0) [0|6] "" Vector__XXX
 SG_ DI_distDrivenInGear : 8|8@1+ (0.0235294122249,0) [0|6] "m" Vector__XXX
 SG_ DI_frontBlocked : 16|1@1+ (1,0) [0|1] "" Vector__XXX
 SG_ DI_rearBlocked : 17|1@1+ (1,0) [0|1] "" Vector__XXX
 SG_ DI_firstShiftOccurred : 18|1@1+ (1,0) [0|1] "" Vector__XXX
 SG_ DI_suggestedGearReason : 19|4@1+ (1,0) [0|15] "" Vector__XXX
 SG_ DI_parallelParked : 23|1@1+ (1,0) [0|1] "" Vector__XXX
 SG_ DI_smartShiftGear : 24|2@1+ (1,0) [0|3] "" Vector__XXX
 SG_ DI_smartShiftUnavailableReason : 26|5@1+ (1,0) [1|31] "" Vector__XXX

BO_ 296 DI_systemLimits: 4 DI
 SG_ DI_limitRegenPower : 0|1@1+ (1,0) [0|1] "" Vector__XXX
 SG_ DI_limitIBat : 1|1@1+ (1,0) [0|1] "" Vector__XXX
 SG_ DI_limitVBatLow : 2|1@1+ (1,0) [0|1] "" Vector__XXX
 SG_ DI_limitVBatHigh : 3|1@1+ (1,0) [0|1] "" Vector__XXX
 SG_ DI_limitObstacleDetection : 4|1@1+ (1,0) [0|1] "" Vector__XXX
 SG_ DI_limitSystemLimp : 5|1@1+ (1,0) [0|1] "" Vector__XXX
 SG_ DI_limitSystemGPO : 6|1@1+ (1,0) [0|1] "" Vector__XXX
 SG_ DI_limitShift : 7|1@1+ (1,0) [0|1] "" Vector__XXX
 SG_ DI_limitDriveTorque : 8|1@1+ (1,0) [0|1] "" Vector__XXX
 SG_ DI_limitRegenTorque : 9|1@1+ (1,0) [0|1] "" Vector__XXX
 SG_ DI_limitVehicleSpeed : 10|1@1+ (1,0) [0|1] "" Vector__XXX
 SG_ DI_limitBmsMiaFreeze : 11|1@1+ (1,0) [0|1] "" Vector__XXX
 SG_ DI_limitSystemSpinDownLearning : 12|1@1+ (1,0) [0|1] "" Vector__XXX
 SG_ DI_limitCdp : 13|1@1+ (1,0) [0|1] "" Vector__XXX
 SG_ DI_vehicleSpeedLimitType : 14|2@1+ (1,0) [0|3] "" Vector__XXX
 SG_ DI_vehicleSpeedLimit : 16|9@1+ (1,0) [0|510] "kph" Vector__XXX
 SG_ DI_vehicleSpeedLimitReason : 25|4@1+ (1,0) [0|15] "" Vector__XXX
 SG_ DI_limitClosureNotClosed : 29|1@1+ (1,0) [0|1] "" Vector__XXX
 SG_ DI_proximity : 30|1@1+ (1,0) [0|1] "" Vector__XXX
 SG_ DI_undersideAbuse : 31|1@1+ (1,0) [0|1] "" Vector__XXX

BO_TX_BU_ 1319 : DI;
BO_TX_BU_ 871 : DI;
BO_TX_BU_ 872 : DI;
BO_TX_BU_ 875 : DI;
BO_TX_BU_ 878 : DI;
BO_TX_BU_ 328 : DI;
BO_TX_BU_ 1861 : DI;
BO_TX_BU_ 1869 : DI;
BO_TX_BU_ 694 : DI;
BO_TX_BU_ 2007 : DI;
BO_TX_BU_ 1866 : DI;
BO_TX_BU_ 1623 : DI;
BO_TX_BU_ 646 : DI;
BO_TX_BU_ 1270 : DI;
BO_TX_BU_ 822 : DI;
BO_TX_BU_ 950 : DI;
BO_TX_BU_ 599 : DI;
BO_TX_BU_ 2006 : DI;
BO_TX_BU_ 597 : DI;
BO_TX_BU_ 296 : DI;
CM_ BO_ 1319 "Drive inverter message: alert log";
CM_ SG_ 1319 DI_alertID "Drive inverter: alert ID";
CM_ SG_ 1319 DI_alertState "Drive inverter: alert state";
CM_ SG_ 1319 DI_a004_unavailableReason "Drive inverter: a004 unavailable reason; raw 0 = signal not available (SNA)";
CM_ SG_ 1319 DI_a007_button "Drive inverter: a007 button";
CM_ SG_ 1319 DI_a007_buttonStuckTime "Drive inverter: a007 button stuck time";
CM_ SG_ 1319 DI_a010_sccReset "Drive inverter: a010 scc reset";
CM_ SG_ 1319 DI_a010_hibernate "Drive inverter: a010 hibernate";
CM_ SG_ 1319 DI_a010_hwBist "Drive inverter: a010 hw bist";
CM_ SG_ 1319 DI_a010_nmiWatchdog "Drive inverter: a010 nmi watchdog";
CM_ SG_ 1319 DI_a010_watchdog "Drive inverter: a010 watchdog";
CM_ SG_ 1319 DI_a010_clockFailNmi "Drive inverter: a010 clock fail nmi";
CM_ SG_ 1319 DI_a010_ramUncErrorNmi "Drive inverter: a010 ram unc error nmi";
CM_ SG_ 1319 DI_a010_flashUncErrorNmi "Drive inverter: a010 flash unc error nmi";
CM_ SG_ 1319 DI_a010_cpu1signMismatchNmi "Drive inverter: a010 cpu1sign mismatch nmi";
CM_ SG_ 1319 DI_a010_cpu2signMismatchNmi "Drive inverter: a010 cpu2sign mismatch nmi";
CM_ SG_ 1319 DI_a010_pieVectErrorNmi "Drive inverter: a010 pie vect error nmi";
CM_ SG_ 1319 DI_a010_sysDbgNmi "Drive inverter: a010 sys dbg nmi";
CM_ SG_ 1319 DI_a010_rlNmi "Drive inverter: a010 rl nmi";
CM_ SG_ 1319 DI_a010_ovfNmi "Drive inverter: a010 ovf nmi";
CM_ SG_ 1319 DI_a010_wdtFlags "Drive inverter: a010 wdt flags";
CM_ SG_ 1319 DI_a012_accel1SupplyV "Drive inverter: a012 accel1 supply v";
CM_ SG_ 1319 DI_a012_accel2SupplyV "Drive inverter: a012 accel2 supply v";
CM_ SG_ 1319 DI_a013_address "Drive inverter: a013 address";
CM_ SG_ 1319 DI_a013_errorType "Drive inverter: a013 error type";
CM_ SG_ 1319 DI_a015_reason "Drive inverter: a015 reason";
CM_ SG_ 1319 DI_a020_difHvilStatus "Drive inverter: a020 dif hvil status; raw 3 = signal not available (SNA)";
CM_ SG_ 1319 DI_a020_difStatusValid "Drive inverter: a020 dif status valid";
CM_ SG_ 1319 DI_a020_dirHvilStatus "Drive inverter: a020 dir hvil status; raw 3 = signal not available (SNA)";
CM_ SG_ 1319 DI_a020_dirStatusValid "Drive inverter: a020 dir status valid";
CM_ SG_ 1319 DI_a020_vehiclePowerState "Drive inverter: a020 vehicle power state";
CM_ SG_ 1319 DI_a020_hvilSystemStatus "Drive inverter: a020 hvil system status; raw 3 = signal not available (SNA)";
CM_ SG_ 1319 DI_a021_packVoltage "Drive inverter: a021 pack voltage";
CM_ SG_ 1319 DI_a021_maxBusVoltage "Drive inverter: a021 max bus voltage";
CM_ SG_ 1319 DI_a024_pedalPos "Drive inverter: a024 pedal pos";
CM_ SG_ 1319 DI_a024_brakePressed "Drive inverter: a024 brake pressed";
CM_ SG_ 1319 DI_a024_currentGear "Drive inverter: a024 current gear; raw 7 = signal not available (SNA)";
CM_ SG_ 1319 DI_a025_backfillState "Drive inverter: a025 backfill state";
CM_ SG_ 1319 DI_a025_bfillUnavailableReason "Drive inverter: a025 bfill unavailable reason";
CM_ SG_ 1319 DI_a036_numFaultedUnits "Drive inverter: a036 num faulted units";
CM_ SG_ 1319 DI_a036_numAvailableUnits "Drive inverter: a036 num available units";
CM_ SG_ 1319 DI_a040_torque "Drive inverter: a040 torque";
CM_ SG_ 1319 DI_a040_capability "Drive inverter: a040 capability";
CM_ SG_ 1319 DI_a040_power "Drive inverter: a040 power";
CM_ SG_ 1319 DI_a040_status "Drive inverter: a040 status";
CM_ SG_ 1319 DI_a040_capability2 "Drive inverter: a040 capability2";
CM_ SG_ 1319 DI_a040_hvStatus "Drive inverter: a040 hv status";
CM_ SG_ 1319 DI_a040_temperature "Drive inverter: a040 temperature";
CM_ SG_ 1319 DI_a042_state4 "Drive inverter: a042 state4";
CM_ SG_ 1319 DI_a043_state4 "Drive inverter: a043 state4";
CM_ SG_ 1319 DI_a051_dcCableCurrentEst "Drive inverter: a051 dc cable current est";
CM_ SG_ 1319 DI_a051_packCurrent "Drive inverter: a051 pack current";
CM_ SG_ 1319 DI_a052_torque "Drive inverter: a052 torque";
CM_ SG_ 1319 DI_a052_capability "Drive inverter: a052 capability";
CM_ SG_ 1319 DI_a052_power "Drive inverter: a052 power";
CM_ SG_ 1319 DI_a052_status "Drive inverter: a052 status";
CM_ SG_ 1319 DI_a052_capability2 "Drive inverter: a052 capability2";
CM_ SG_ 1319 DI_a052_hvStatus "Drive inverter: a052 hv status";
CM_ SG_ 1319 DI_a052_temperature "Drive inverter: a052 temperature";
CM_ SG_ 1319 DI_a053_badValue1 "Drive inverter: a053 bad value1";
CM_ SG_ 1319 DI_a053_badValue2 "Drive inverter: a053 bad value2";
CM_ SG_ 1319 DI_a053_canID "Drive inverter: a053 can ID";
CM_ SG_ 1319 DI_a053_errorType "Drive inverter: a053 error type";
CM_ SG_ 1319 DI_a056_badValue1 "Drive inverter: a056 bad value1";
CM_ SG_ 1319 DI_a056_badValue2 "Drive inverter: a056 bad value2";
CM_ SG_ 1319 DI_a056_canID "Drive inverter: a056 can ID";
CM_ SG_ 1319 DI_a056_errorType "Drive inverter: a056 error type";
CM_ SG_ 1319 DI_a059_badValue1 "Drive inverter: a059 bad value1";
CM_ SG_ 1319 DI_a059_badValue2 "Drive inverter: a059 bad value2";
CM_ SG_ 1319 DI_a059_canID "Drive inverter: a059 can ID";
CM_ SG_ 1319 DI_a059_errorType "Drive inverter: a059 error type";
CM_ SG_ 1319 DI_a062_limpReason "Drive inverter: a062 limp reason";
CM_ SG_ 1319 DI_a063_gpoReason "Drive inverter: a063 gpo reason";
CM_ SG_ 1319 DI_a064_hvState "Drive inverter: a064 hv state";
CM_ SG_ 1319 DI_a064_vehiclePowerState "Drive inverter: a064 vehicle power state";
CM_ SG_ 1319 DI_a064_vehicleSpeed "Drive inverter: a064 vehicle speed";
CM_ SG_ 1319 DI_a066_badValue1 "Drive inverter: a066 bad value1";
CM_ SG_ 1319 DI_a066_badValue2 "Drive inverter: a066 bad value2";
CM_ SG_ 1319 DI_a066_canID "Drive inverter: a066 can ID";
CM_ SG_ 1319 DI_a066_errorType "Drive inverter: a066 error type";
CM_ SG_ 1319 DI_a076_lvSupplyV "Drive inverter: a076 lv supply v";
CM_ SG_ 1319 DI_a077_lvSupplyV "Drive inverter: a077 lv supply v";
CM_ SG_ 1319 DI_a078_adcRefChan "Drive inverter: a078 adc ref chan";
CM_ SG_ 1319 DI_a078_adcRefLowAvg "Drive inverter: a078 adc ref low avg";
CM_ SG_ 1319 DI_a079_adcRefChan "Drive inverter: a079 adc ref chan";
CM_ SG_ 1319 DI_a079_adcRefHighAvg "Drive inverter: a079 adc ref high avg";
CM_ SG_ 1319 DI_a083_brakeSwitchNO "Drive inverter: a083 brake switch NO";
CM_ SG_ 1319 DI_a083_brakeSwitchNC "Drive inverter: a083 brake switch NC";
CM_ SG_ 1319 DI_a083_brakeSwitchIrrationalNO "Drive inverter: a083 brake switch irrational NO";
CM_ SG_ 1319 DI_a083_brakeSwitchIrrationalNC "Drive inverter: a083 brake switch irrational NC";
CM_ SG_ 1319 DI_a086_DPB_actuator3 "Drive inverter: a086 DPB actuator3";
CM_ SG_ 1319 DI_a087_gtwCarConfig "Drive inverter: a087 gtw car config";
CM_ SG_ 1319 DI_a087_gtwTime "Drive inverter: a087 gtw time";
CM_ SG_ 1319 DI_a087_gtwUpdateStatus "Drive inverter: a087 gtw update status";
CM_ SG_ 1319 DI_a087_gearControl "Drive inverter: a087 gear control";
CM_ SG_ 1319 DI_a087_carState "Drive inverter: a087 car state";
CM_ SG_ 1319 DI_a089_SCCM_rightStalk "Drive inverter: a089 SCCM right stalk";
CM_ SG_ 1319 DI_a090_reason "Drive inverter: a090 reason";
CM_ SG_ 1319 DI_a090_systemState "Drive inverter: a090 system state";
CM_ SG_ 1319 DI_a090_state "Drive inverter: a090 state";
CM_ SG_ 1319 DI_a090_locState "Drive inverter: a090 loc state";
CM_ SG_ 1319 DI_a090_state2 "Drive inverter: a090 state2";
CM_ SG_ 1319 DI_a090_state4 "Drive inverter: a090 state4";
CM_ SG_ 1319 DI_a091_ESP_brakeTorque "Drive inverter: a091 ESP brake torque";
CM_ SG_ 1319 DI_a091_ESP_wheelSpeeds "Drive inverter: a091 ESP wheel speeds";
CM_ SG_ 1319 DI_a091_ESP_wheelRotation "Drive inverter: a091 ESP wheel rotation";
CM_ SG_ 1319 DI_a091_ESP_motorLimits "Drive inverter: a091 ESP motor limits";
CM_ SG_ 1319 DI_a091_ESP_offsets "Drive inverter: a091 ESP offsets";
CM_ SG_ 1319 DI_a091_ESP_status "Drive inverter: a091 ESP status";
CM_ SG_ 1319 DI_a091_ESP_party3 "Drive inverter: a091 ESP party3";
CM_ SG_ 1319 DI_a092_bmsStatus "Drive inverter: a092 bms status";
CM_ SG_ 1319 DI_a092_bmsDriveLimits "Drive inverter: a092 bms drive limits";
CM_ SG_ 1319 DI_a092_bmsHvBusStatus "Drive inverter: a092 bms hv bus status";
CM_ SG_ 1319 DI_a092_bmsPowerAvailable "Drive inverter: a092 bms power available";
CM_ SG_ 1319 DI_a092_bmsBmbMinMax "Drive inverter: a092 bms bmb min max";
CM_ SG_ 1319 DI_a092_bmsSocStatus "Drive inverter: a092 bms soc status";
CM_ SG_ 1319 DI_a092_bmsThermalStatus "Drive inverter: a092 bms thermal status";
CM_ SG_ 1319 DI_a092_bmsCtrStatus "Drive inverter: a092 bms ctr status";
CM_ SG_ 1319 DI_a092_bmsVoltageRegGain "Drive inverter: a092 bms voltage reg gain";
CM_ SG_ 1319 DI_a092_bmsPackConfig "Drive inverter: a092 bms pack config";
CM_ SG_ 1319 DI_a092_bmsSystemStatus "Drive inverter: a092 bms system status";
CM_ SG_ 1319 DI_a094_canID "Drive inverter: a094 can ID";
CM_ SG_ 1319 DI_a094_errorType "Drive inverter: a094 error type";
CM_ SG_ 1319 DI_a094_badValue1 "Drive inverter: a094 bad value1";
CM_ SG_ 1319 DI_a094_badValue2 "Drive inverter: a094 bad value2";
CM_ SG_ 1319 DI_a096_const_fast "Drive inverter: a096 const fast";
CM_ SG_ 1319 DI_a096_text_fast "Drive inverter: a096 text fast";
CM_ SG_ 1319 DI_a096_text_flash "Drive inverter: a096 text flash";
CM_ SG_ 1319 DI_a096_mem_data "Drive inverter: a096 mem data";
CM_ SG_ 1319 DI_a096_mem_regs "Drive inverter: a096 mem regs";
CM_ SG_ 1319 DI_a096_boot_flash "Drive inverter: a096 boot flash";
CM_ SG_ 1319 DI_a096_word1 "Drive inverter: a096 word1";
CM_ SG_ 1319 DI_a096_word2 "Drive inverter: a096 word2";
CM_ SG_ 1319 DI_a097_errorType "Drive inverter: a097 error type";
CM_ SG_ 1319 DI_a097_lineNumber "Drive inverter: a097 line number";
CM_ SG_ 1319 DI_a097_argument "Drive inverter: a097 argument";
CM_ SG_ 1319 DI_a098_page0Counter "Drive inverter: a098 page0 counter";
CM_ SG_ 1319 DI_a098_page1Counter "Drive inverter: a098 page1 counter";
CM_ SG_ 1319 DI_a098_page2Counter "Drive inverter: a098 page2 counter";
CM_ SG_ 1319 DI_a098_pageID "Drive inverter: a098 page ID";
CM_ SG_ 1319 DI_a098_recordID "Drive inverter: a098 record ID";
CM_ SG_ 1319 DI_a098_errorCode "Drive inverter: a098 error code";
CM_ SG_ 1319 DI_a103_BB_status "Drive inverter: a103 BB status";
CM_ SG_ 1319 DI_a103_BB_brakeActuation "Drive inverter: a103 BB brake actuation";
CM_ SG_ 1319 DI_a104_proxIrrationalReason "Drive inverter: a104 prox irrational reason";
CM_ SG_ 1319 DI_a105_cpStatus "Drive inverter: a105 cp status";
CM_ SG_ 1319 DI_a110_EPBL_status "Drive inverter: a110 EPBL status";
CM_ SG_ 1319 DI_a110_EPBR_status "Drive inverter: a110 EPBR status";
CM_ SG_ 1319 DI_a115_faultAddress "Drive inverter: a115 fault address";
CM_ SG_ 1319 DI_a115_isWriteNotRead "Drive inverter: a115 is write not read";
CM_ SG_ 1319 DI_a120_blendingState "Drive inverter: a120 blending state";
CM_ SG_ 1319 DI_a120_blendingUnavailableReaso "Drive inverter: a120 blending unavailable reason";
CM_ SG_ 1319 DI_a124_undrivenWheelMPH "Drive inverter: a124 undriven wheel MPH";
CM_ SG_ 1319 DI_a124_cruiseFaultReason "Drive inverter: a124 cruise fault reason; raw 17 = signal not available (SNA)";
CM_ SG_ 1319 DI_a125_maxDischargeCurrent "Drive inverter: a125 max discharge current";
CM_ SG_ 1319 DI_a125_maxChargeCurrent "Drive inverter: a125 max charge current";
CM_ SG_ 1319 DI_a125_minBusVoltage "Drive inverter: a125 min bus voltage";
CM_ SG_ 1319 DI_a130_aebFaultReason "Drive inverter: a130 aeb fault reason; raw 6 = signal not available (SNA)";
CM_ SG_ 1319 DI_a130_aebSmState "Drive inverter: a130 aeb sm state";
CM_ SG_ 1319 DI_a130_dasAebEvent "Drive inverter: a130 das aeb event; raw 3 = signal not available (SNA)";
CM_ SG_ 1319 DI_a130_aebBrakeTorqueCommand "Drive inverter: a130 aeb brake torque command";
CM_ SG_ 1319 DI_a131_totalTimeRemaining "Drive inverter: a131 total time remaining";
CM_ SG_ 1319 DI_a131_warnSpeedLimit "Drive inverter: a131 warn speed limit";
CM_ SG_ 1319 DI_a131_warnTimeRemaining "Drive inverter: a131 warn time remaining";
CM_ SG_ 1319 DI_a133_vhldSmState "Drive inverter: a133 vhld sm state";
CM_ SG_ 1319 DI_a133_reverseGear "Drive inverter: a133 reverse gear";
CM_ SG_ 1319 DI_a133_vhldGrade "Drive inverter: a133 vhld grade";
CM_ SG_ 1319 DI_a134_wheelSpeedDiffFrL "Drive inverter: a134 wheel speed diff fr l";
CM_ SG_ 1319 DI_a134_wheelSpeedDiffFrR "Drive inverter: a134 wheel speed diff fr r";
CM_ SG_ 1319 DI_a134_wheelSpeedDiffReL "Drive inverter: a134 wheel speed diff re l";
CM_ SG_ 1319 DI_a134_wheelSpeedDiffReR "Drive inverter: a134 wheel speed diff re r";
CM_ SG_ 1319 DI_a135_vhldFaultReason "Drive inverter: a135 vhld fault reason";
CM_ SG_ 1319 DI_a135_vhldSmState "Drive inverter: a135 vhld sm state";
CM_ SG_ 1319 DI_a135_vhldBrakeApply "Drive inverter: a135 vhld brake apply";
CM_ SG_ 1319 DI_a135_vhldBrakeTorqueCommand "Drive inverter: a135 vhld brake torque command";
CM_ SG_ 1319 DI_a135_vhldTotalBrakeTorque "Drive inverter: a135 vhld total brake torque";
CM_ SG_ 1319 DI_a135_vhldPropulsiveTorque "Drive inverter: a135 vhld propulsive torque";
CM_ SG_ 1319 DI_a135_vhldGrade "Drive inverter: a135 vhld grade";
CM_ SG_ 1319 DI_a140_PTC_feedbackStatus "Drive inverter: a140 PTC feedback status";
CM_ SG_ 1319 DI_a141_DAS_control "Drive inverter: a141 DAS control";
CM_ SG_ 1319 DI_a141_DAS_pmmControl "Drive inverter: a141 DAS pmm control";
CM_ SG_ 1319 DI_a141_DAS_status "Drive inverter: a141 DAS status";
CM_ SG_ 1319 DI_a141_DAS_status2 "Drive inverter: a141 DAS status2";
CM_ SG_ 1319 DI_a141_DAS_smartShift "Drive inverter: a141 DAS smart shift";
CM_ SG_ 1319 DI_a141_DAS_longControl "Drive inverter: a141 DAS long control";
CM_ SG_ 1319 DI_a141_DAS_longControlTuningPar "Drive inverter: a141 DAS long control tuning parameters";
CM_ SG_ 1319 DI_a141_DAS_autonomyControl "Drive inverter: a141 DAS autonomy control";
CM_ SG_ 1319 DI_a143_mechPowerLimit "Drive inverter: a143 mech power limit";
CM_ SG_ 1319 DI_a143_systemTorqueLimit "Drive inverter: a143 system torque limit";
CM_ SG_ 1319 DI_a144_autopilot "Drive inverter: a144 autopilot";
CM_ SG_ 1319 DI_a144_chassisType "Drive inverter: a144 chassis type";
CM_ SG_ 1319 DI_a144_drivetrainType "Drive inverter: a144 drivetrain type";
CM_ SG_ 1319 DI_a144_packEnergy "Drive inverter: a144 pack energy";
CM_ SG_ 1319 DI_a144_packPerformanceDeviation "Drive inverter: a144 pack performance deviation";
CM_ SG_ 1319 DI_a144_performancePackage "Drive inverter: a144 performance package";
CM_ SG_ 1319 DI_a144_vdcType "Drive inverter: a144 vdc type";
CM_ SG_ 1319 DI_a144_brakeHWType "Drive inverter: a144 brake HW type";
CM_ SG_ 1319 DI_a144_inverterHardware "Drive inverter: a144 inverter hardware";
CM_ SG_ 1319 DI_a144_cabinPTCHeaterType "Drive inverter: a144 cabin PTC heater type";
CM_ SG_ 1319 DI_a144_frunkLatchType "Drive inverter: a144 frunk latch type";
CM_ SG_ 1319 DI_a144_platformMaxBusVoltage "Drive inverter: a144 platform max bus voltage";
CM_ SG_ 1319 DI_a144_oilPump1HwType "Drive inverter: a144 oil pump1 hw type";
CM_ SG_ 1319 DI_a144_oilPump2HwType "Drive inverter: a144 oil pump2 hw type";
CM_ SG_ 1319 DI_a144_heatsinkType "Drive inverter: a144 heatsink type";
CM_ SG_ 1319 DI_a144_softPerformanceLimit "Drive inverter: a144 soft performance limit";
CM_ SG_ 1319 DI_a144_brakeActuationType "Drive inverter: a144 brake actuation type";
CM_ SG_ 1319 DI_a144_dasHw "Drive inverter: a144 das hw";
CM_ SG_ 1319 DI_a144_chassisSubType "Drive inverter: a144 chassis sub type";
CM_ SG_ 1319 DI_a146_panicReason "Drive inverter: a146 panic reason";
CM_ SG_ 1319 DI_a155_sensors "Drive inverter: a155 sensors";
CM_ SG_ 1319 DI_a155_coolant "Drive inverter: a155 coolant";
CM_ SG_ 1319 DI_a155_LVPowerState "Drive inverter: a155 LV power state";
CM_ SG_ 1319 DI_a155_vehicleStatus "Drive inverter: a155 vehicle status";
CM_ SG_ 1319 DI_a155_status "Drive inverter: a155 status";
CM_ SG_ 1319 DI_a155_leftDoorStatus "Drive inverter: a155 left door status";
CM_ SG_ 1319 DI_a155_rightDoorStatus "Drive inverter: a155 right door status";
CM_ SG_ 1319 DI_a155_vcleftSwitchStatus "Drive inverter: a155 vcleft switch status";
CM_ SG_ 1319 DI_a155_restraintStatus "Drive inverter: a155 restraint status";
CM_ SG_ 1319 DI_a155_systemStatus "Drive inverter: a155 system status";
CM_ SG_ 1319 DI_a155_prndStatus "Drive inverter: a155 prnd status";
CM_ SG_ 1319 DI_a155_liftgateStatus "Drive inverter: a155 liftgate status";
CM_ SG_ 1319 DI_a157_RCM_inertial1 "Drive inverter: a157 RCM inertial1";
CM_ SG_ 1319 DI_a157_RCM_inertial2 "Drive inverter: a157 RCM inertial2";
CM_ SG_ 1319 DI_a158_IBST_party1 "Drive inverter: a158 IBST party1";
CM_ SG_ 1319 DI_a158_BUS1_IBST_status "Drive inverter: a158 BUS1 IBST status";
CM_ SG_ 1319 DI_a158_BUS2_IBST_status "Drive inverter: a158 BUS2 IBST status";
CM_ SG_ 1319 DI_a160_kTire "Drive inverter: a160 k tire";
CM_ SG_ 1319 DI_a160_tireFitment "Drive inverter: a160 tire fitment; raw 3 = signal not available (SNA)";
CM_ SG_ 1319 DI_a160_wearFactorFrL "Drive inverter: a160 wear factor fr l";
CM_ SG_ 1319 DI_a160_wearFactorFrR "Drive inverter: a160 wear factor fr r";
CM_ SG_ 1319 DI_a160_wearFactorReL "Drive inverter: a160 wear factor re l";
CM_ SG_ 1319 DI_a160_distanceSinceLastTireCon "Drive inverter: a160 distance since last tire config; raw 4095 = signal not available (SNA)";
CM_ SG_ 1319 DI_a161_EPAS3P_sysStatus "Drive inverter: a161 EPAS3 p sys status";
CM_ SG_ 1319 DI_a161_EPAS3P_angleCalib "Drive inverter: a161 EPAS3 p angle calib";
CM_ SG_ 1319 DI_a162_shiftDeniedReason "Drive inverter: a162 shift denied reason";
CM_ SG_ 1319 DI_a162_motorSpeed "Drive inverter: a162 motor speed";
CM_ SG_ 1319 DI_a162_essContClosed "Drive inverter: a162 ess cont closed";
CM_ SG_ 1319 DI_a162_manualDrivingProhibited "Drive inverter: a162 manual driving prohibited";
CM_ SG_ 1319 DI_a162_pedalPos "Drive inverter: a162 pedal pos";
CM_ SG_ 1319 DI_a162_currentGear "Drive inverter: a162 current gear; raw 7 = signal not available (SNA)";
CM_ SG_ 1319 DI_a162_requestedGear "Drive inverter: a162 requested gear; raw 7 = signal not available (SNA)";
CM_ SG_ 1319 DI_a162_requestSource "Drive inverter: a162 request source";
CM_ SG_ 1319 DI_a162_timeSinceCruiseCancel "Drive inverter: a162 time since cruise cancel";
CM_ SG_ 1319 DI_a162_chargeCableConnected "Drive inverter: a162 charge cable connected";
CM_ SG_ 1319 DI_a162_frunkOpen "Drive inverter: a162 frunk open";
CM_ SG_ 1319 DI_a162_sysStateExitCondition "Drive inverter: a162 sys state exit condition";
CM_ SG_ 1319 DI_a163_motorSpeed "Drive inverter: a163 motor speed";
CM_ SG_ 1319 DI_a163_currentGear "Drive inverter: a163 current gear; raw 7 = signal not available (SNA)";
CM_ SG_ 1319 DI_a163_requestedGear "Drive inverter: a163 requested gear; raw 7 = signal not available (SNA)";
CM_ SG_ 1319 DI_a163_requestSource "Drive inverter: a163 request source";
CM_ SG_ 1319 DI_a164_motorSpeed "Drive inverter: a164 motor speed";
CM_ SG_ 1319 DI_a164_pedalPos "Drive inverter: a164 pedal pos";
CM_ SG_ 1319 DI_a164_torqueDriver "Drive inverter: a164 torque driver";
CM_ SG_ 1319 DI_a165_crsCancelReason "Drive inverter: a165 crs cancel reason";
CM_ SG_ 1319 DI_a170_tireSeasonSelected "Drive inverter: a170 tire season selected";
CM_ SG_ 1319 DI_a170_kTire "Drive inverter: a170 k tire";
CM_ SG_ 1319 DI_a170_tireFitment "Drive inverter: a170 tire fitment; raw 3 = signal not available (SNA)";
CM_ SG_ 1319 DI_a170_wearFactorFrL "Drive inverter: a170 wear factor fr l";
CM_ SG_ 1319 DI_a170_wearFactorFrR "Drive inverter: a170 wear factor fr r";
CM_ SG_ 1319 DI_a170_wearFactorReL "Drive inverter: a170 wear factor re l";
CM_ SG_ 1319 DI_a170_odometer "Drive inverter: a170 odometer; raw 4095 = signal not available (SNA)";
CM_ SG_ 1319 DI_a170_distanceSinceLastTireCon "Drive inverter: a170 distance since last tire config; raw 63 = signal not available (SNA)";
CM_ SG_ 1319 DI_a170_treadDepthAlertSet "Drive inverter: a170 tread depth alert set";
CM_ SG_ 1319 DI_a172_motorSpeed "Drive inverter: a172 motor speed";
CM_ SG_ 1319 DI_a172_pedalPos "Drive inverter: a172 pedal pos";
CM_ SG_ 1319 DI_a172_currentGear "Drive inverter: a172 current gear; raw 7 = signal not available (SNA)";
CM_ SG_ 1319 DI_a172_timeSinceCruiseCancel "Drive inverter: a172 time since cruise cancel";
CM_ SG_ 1319 DI_a173_brakeApply "Drive inverter: a173 brake apply";
CM_ SG_ 1319 DI_a173_pedalPos "Drive inverter: a173 pedal pos";
CM_ SG_ 1319 DI_a175_crsNotAvailableReason "Drive inverter: a175 crs not available reason; raw 20 = signal not available (SNA)";
CM_ SG_ 1319 DI_a177_newFitment "Drive inverter: a177 new fitment; raw 3 = signal not available (SNA)";
CM_ SG_ 1319 DI_a178_offsetValue "Drive inverter: a178 offset value";
CM_ SG_ 1319 DI_a180_crsNotAvailableReason "Drive inverter: a180 crs not available reason; raw 20 = signal not available (SNA)";
CM_ SG_ 1319 DI_a184_apcCancelReason "Drive inverter: a184 apc cancel reason";
CM_ SG_ 1319 DI_a184_apcUnavailableReason "Drive inverter: a184 apc unavailable reason";
CM_ SG_ 1319 DI_a184_autoparkInternalState "Drive inverter: a184 autopark internal state";
CM_ SG_ 1319 DI_a185_summonActive "Drive inverter: a185 summon active";
CM_ SG_ 1319 DI_a185_apcCancelReason "Drive inverter: a185 apc cancel reason";
CM_ SG_ 1319 DI_a185_apcUnavailableReason "Drive inverter: a185 apc unavailable reason";
CM_ SG_ 1319 DI_a185_crsNotAvailableReason "Drive inverter: a185 crs not available reason; raw 20 = signal not available (SNA)";
CM_ SG_ 1319 DI_a185_crsFaultReason "Drive inverter: a185 crs fault reason; raw 17 = signal not available (SNA)";
CM_ SG_ 1319 DI_a185_autoparkInternalState "Drive inverter: a185 autopark internal state";
CM_ SG_ 1319 DI_a187_filteredAccel "Drive inverter: a187 filtered accel";
CM_ SG_ 1319 DI_a187_rawPedal "Drive inverter: a187 raw pedal";
CM_ SG_ 1319 DI_a187_systemTorqueCommand "Drive inverter: a187 system torque command";
CM_ SG_ 1319 DI_a189_accelPedal "Drive inverter: a189 accel pedal";
CM_ SG_ 1319 DI_a189_grade "Drive inverter: a189 grade";
CM_ SG_ 1319 DI_a189_brakePressed "Drive inverter: a189 brake pressed";
CM_ SG_ 1319 DI_a189_systemTorque "Drive inverter: a189 system torque";
CM_ SG_ 1319 DI_a189_motorSpeed "Drive inverter: a189 motor speed";
CM_ SG_ 1319 DI_a190_relativeTireTreadDepth "Drive inverter: a190 relative tire tread depth";
CM_ SG_ 1319 DI_a190_treadWearFactorFrL "Drive inverter: a190 tread wear factor fr l";
CM_ SG_ 1319 DI_a190_treadWearFactorFrR "Drive inverter: a190 tread wear factor fr r";
CM_ SG_ 1319 DI_a190_treadWearFactorReL "Drive inverter: a190 tread wear factor re l";
CM_ SG_ 1319 DI_a190_treadWearFactorAvgConfid "Drive inverter: a190 tread wear factor avg confidence";
CM_ SG_ 1319 DI_a191_motorSpeed "Drive inverter: a191 motor speed";
CM_ SG_ 1319 DI_a191_reverseDeniedAfterCruise "Drive inverter: a191 reverse denied after cruise";
CM_ SG_ 1319 DI_a191_currentGear "Drive inverter: a191 current gear; raw 7 = signal not available (SNA)";
CM_ SG_ 1319 DI_a191_requestedGear "Drive inverter: a191 requested gear; raw 7 = signal not available (SNA)";
CM_ SG_ 1319 DI_a191_requestSource "Drive inverter: a191 request source";
CM_ SG_ 1319 DI_a191_timeSinceCruiseCancel "Drive inverter: a191 time since cruise cancel";
CM_ SG_ 1319 DI_a193_brakeTorqueFrL "Drive inverter: a193 brake torque fr l";
CM_ SG_ 1319 DI_a193_brakeTorqueFrLLastVal "Drive inverter: a193 brake torque fr l last val";
CM_ SG_ 1319 DI_a193_brakeTorqueFrLCurrVal "Drive inverter: a193 brake torque fr l curr val";
CM_ SG_ 1319 DI_a193_brakeTorqueFrR "Drive inverter: a193 brake torque fr r";
CM_ SG_ 1319 DI_a193_brakeTorqueFrRLastVal "Drive inverter: a193 brake torque fr r last val";
CM_ SG_ 1319 DI_a193_brakeTorqueFrRCurrVal "Drive inverter: a193 brake torque fr r curr val";
CM_ SG_ 1319 DI_a194_brakeTorqueReL "Drive inverter: a194 brake torque re l";
CM_ SG_ 1319 DI_a194_brakeTorqueReLLastVal "Drive inverter: a194 brake torque re l last val";
CM_ SG_ 1319 DI_a194_brakeTorqueReLCurrVal "Drive inverter: a194 brake torque re l curr val";
CM_ SG_ 1319 DI_a194_brakeTorqueReR "Drive inverter: a194 brake torque re r";
CM_ SG_ 1319 DI_a194_brakeTorqueReRLastVal "Drive inverter: a194 brake torque re r last val";
CM_ SG_ 1319 DI_a194_brakeTorqueReRCurrVal "Drive inverter: a194 brake torque re r curr val";
CM_ SG_ 1319 DI_a199_muVehicleLearnDown "Drive inverter: a199 mu vehicle learn down";
CM_ SG_ 1319 DI_a199_muVehicleDecFilt "Drive inverter: a199 mu vehicle dec filt";
CM_ SG_ 1319 DI_a199_bankAngle "Drive inverter: a199 bank angle";
CM_ SG_ 1319 DI_a199_lateralAccelFilt "Drive inverter: a199 lateral accel filt";
CM_ SG_ 1319 DI_a199_driverIntendedYawRate "Drive inverter: a199 driver intended yaw rate";
CM_ SG_ 1319 DI_a199_vehicleVelocity "Drive inverter: a199 vehicle velocity";
CM_ SG_ 1319 DI_a199_sensorYawRate "Drive inverter: a199 sensor yaw rate";
CM_ SG_ 1319 DI_a199_preControlActive "Drive inverter: a199 pre control active";
CM_ SG_ 1319 DI_a199_oversteerdMzActive "Drive inverter: a199 oversteerd mz active";
CM_ SG_ 1319 DI_a199_decelControlActive "Drive inverter: a199 decel control active";
CM_ SG_ 1319 DI_a199_understeerdMzActive "Drive inverter: a199 understeerd mz active";
CM_ SG_ 1319 DI_a199_vdcMode "Drive inverter: a199 vdc mode";
CM_ SG_ 1319 DI_a200_MBPCheckStatus "Drive inverter: a200 MBP check status";
CM_ SG_ 1319 DI_a200_MBPFailedCase "Drive inverter: a200 MBP failed case";
CM_ SG_ 1319 DI_a200_MBPFaultProbability "Drive inverter: a200 MBP fault probability";
CM_ SG_ 1319 DI_a202_reason "Drive inverter: a202 reason";
CM_ SG_ 1319 DI_a202_movement "Drive inverter: a202 movement";
CM_ SG_ 1319 DI_a202_sysStateExitCondition "Drive inverter: a202 sys state exit condition";
CM_ SG_ 1319 DI_a203_ptcStateLocal "Drive inverter: a203 ptc state local; raw 6 = signal not available (SNA)";
CM_ SG_ 1319 DI_a203_btcState "Drive inverter: a203 btc state";
CM_ SG_ 1319 DI_a204_longAccel "Drive inverter: a204 long accel";
CM_ SG_ 1319 DI_a204_longAccelLastVal "Drive inverter: a204 long accel last val";
CM_ SG_ 1319 DI_a204_longAccelCurrVal "Drive inverter: a204 long accel curr val";
CM_ SG_ 1319 DI_a204_rollRate "Drive inverter: a204 roll rate";
CM_ SG_ 1319 DI_a204_rollRateLastVal "Drive inverter: a204 roll rate last val";
CM_ SG_ 1319 DI_a204_rollRateCurrVal "Drive inverter: a204 roll rate curr val";
CM_ SG_ 1319 DI_a205_latAccel "Drive inverter: a205 lat accel";
CM_ SG_ 1319 DI_a205_latAccelLastVal "Drive inverter: a205 lat accel last val";
CM_ SG_ 1319 DI_a205_latAccelCurrVal "Drive inverter: a205 lat accel curr val";
CM_ SG_ 1319 DI_a205_pitchRate "Drive inverter: a205 pitch rate";
CM_ SG_ 1319 DI_a205_pitchRateLastVal "Drive inverter: a205 pitch rate last val";
CM_ SG_ 1319 DI_a205_pitchRateCurrVal "Drive inverter: a205 pitch rate curr val";
CM_ SG_ 1319 DI_a206_verticalAccel "Drive inverter: a206 vertical accel";
CM_ SG_ 1319 DI_a206_verticalAccelLastVal "Drive inverter: a206 vertical accel last val";
CM_ SG_ 1319 DI_a206_verticalAccelCurrVal "Drive inverter: a206 vertical accel curr val";
CM_ SG_ 1319 DI_a206_yawRate "Drive inverter: a206 yaw rate";
CM_ SG_ 1319 DI_a206_yawRateLastVal "Drive inverter: a206 yaw rate last val";
CM_ SG_ 1319 DI_a206_yawRateCurrVal "Drive inverter: a206 yaw rate curr val";
CM_ SG_ 1319 DI_a210_ptcStateGlobal "Drive inverter: a210 ptc state global; raw 3 = signal not available (SNA)";
CM_ SG_ 1319 DI_a210_espActuatorState "Drive inverter: a210 esp actuator state";
CM_ SG_ 1319 DI_a210_brakeTmpEstStateFaulted "Drive inverter: a210 brake tmp est state faulted";
CM_ SG_ 1319 DI_a210_secondaryBrakeActuatorIs "Drive inverter: a210 secondary brake actuator is master";
CM_ SG_ 1319 DI_a223_ptcStateLocal "Drive inverter: a223 ptc state local; raw 6 = signal not available (SNA)";
CM_ SG_ 1319 DI_a223_btcState "Drive inverter: a223 btc state";
CM_ SG_ 1319 DI_a223_velocityEstimatorState "Drive inverter: a223 velocity estimator state";
CM_ SG_ 1319 DI_a223_addState_dir "Drive inverter: a223 add state dir";
CM_ SG_ 1319 DI_a223_addState_dif "Drive inverter: a223 add state dif";
CM_ SG_ 1319 DI_a223_DI_tractionControlMode "Drive inverter: a223 DI traction control mode";
CM_ SG_ 1319 DI_a223_UI_tractionControlMode "Drive inverter: a223 UI traction control mode";
CM_ SG_ 1319 DI_a223_vehicleVelocity "Drive inverter: a223 vehicle velocity";
CM_ SG_ 1319 DI_a223_musurf "Drive inverter: a223 musurf";
CM_ SG_ 1319 DI_a223_musurfHigh "Drive inverter: a223 musurf high";
CM_ SG_ 1319 DI_a223_driveTCActive "Drive inverter: a223 drive TC active";
CM_ SG_ 1319 DI_a223_regenTCActive "Drive inverter: a223 regen TC active";
CM_ SG_ 1319 DI_a223_surfaceUtility "Drive inverter: a223 surface utility";
CM_ SG_ 1319 DI_a224_brakeFLTemp "Drive inverter: a224 brake FL temp";
CM_ SG_ 1319 DI_a224_brakeFRTemp "Drive inverter: a224 brake FR temp";
CM_ SG_ 1319 DI_a224_brakeRLTemp "Drive inverter: a224 brake RL temp";
CM_ SG_ 1319 DI_a224_brakeRRTemp "Drive inverter: a224 brake RR temp";
CM_ SG_ 1319 DI_a226_systState "Drive inverter: a226 syst state";
CM_ SG_ 1319 DI_a226_hvStateNotUpForDrive "Drive inverter: a226 hv state not up for drive";
CM_ SG_ 1319 DI_a226_frunkNotLatched "Drive inverter: a226 frunk not latched";
CM_ SG_ 1319 DI_a226_proxDetected "Drive inverter: a226 prox detected";
CM_ SG_ 1319 DI_a226_falconDoorOpen "Drive inverter: a226 falcon door open";
CM_ SG_ 1319 DI_a226_trunkOpen "Drive inverter: a226 trunk open";
CM_ SG_ 1319 DI_a227_hvState "Drive inverter: a227 hv state";
CM_ SG_ 1319 DI_a227_vehiclePowerState "Drive inverter: a227 vehicle power state";
CM_ SG_ 1319 DI_a230_CMP_HVStatus "Drive inverter: a230 CMP HV status";
CM_ SG_ 1319 DI_a230_CMPD_state "Drive inverter: a230 CMPD state";
CM_ SG_ 1319 DI_a232_velocityEstimatorState "Drive inverter: a232 velocity estimator state";
CM_ SG_ 1319 DI_a232_UI_tractionControlMode "Drive inverter: a232 UI traction control mode";
CM_ SG_ 1319 DI_a232_vehicleVelocity "Drive inverter: a232 vehicle velocity";
CM_ SG_ 1319 DI_a232_musurf "Drive inverter: a232 musurf";
CM_ SG_ 1319 DI_a232_musurfHigh "Drive inverter: a232 musurf high";
CM_ SG_ 1319 DI_a232_allWhlSpeedRotationAvail "Drive inverter: a232 all whl speed rotation avail";
CM_ SG_ 1319 DI_a232_BrakeMasterCylPressValid "Drive inverter: a232 brake master cyl press valid";
CM_ SG_ 1319 DI_a232_WheelBrakeTorquesValid "Drive inverter: a232 wheel brake torques valid";
CM_ SG_ 1319 DI_a232_AbsBrakeEventActiveValid "Drive inverter: a232 abs brake event active valid";
CM_ SG_ 1319 DI_a232_UndersteerActiveValid "Drive inverter: a232 understeer active valid";
CM_ SG_ 1319 DI_a232_OversteerActiveValid "Drive inverter: a232 oversteer active valid";
CM_ SG_ 1319 DI_a232_allMotorTorquesValid "Drive inverter: a232 all motor torques valid";
CM_ SG_ 1319 DI_a232_lateralAccelValid "Drive inverter: a232 lateral accel valid";
CM_ SG_ 1319 DI_a232_longitudinalAccelValid "Drive inverter: a232 longitudinal accel valid";
CM_ SG_ 1319 DI_a232_yawRateValid "Drive inverter: a232 yaw rate valid";
CM_ SG_ 1319 DI_a232_steerAngleValid "Drive inverter: a232 steer angle valid";
CM_ SG_ 1319 DI_a236_states "Drive inverter: a236 states";
CM_ SG_ 1319 DI_a239_numRequests "Drive inverter: a239 num requests";
CM_ SG_ 1319 DI_a243_RCU_status "Drive inverter: a243 RCU status";
CM_ SG_ 1319 DI_a243_RCU_actuation "Drive inverter: a243 RCU actuation";
CM_ SG_ 1319 DI_a245_ebrStatus "Drive inverter: a245 ebr status";
CM_ SG_ 1319 DI_a245_vehicleHoldState "Drive inverter: a245 vehicle hold state";
CM_ SG_ 1319 DI_a246_onePedalDrivingState "Drive inverter: a246 one pedal driving state";
CM_ SG_ 1319 DI_a246_opdUnavailableReason "Drive inverter: a246 opd unavailable reason";
CM_ SG_ 1319 DI_a249_learning_DIF "Drive inverter: a249 learning DIF";
CM_ SG_ 1319 DI_a249_learning_DIR "Drive inverter: a249 learning DIR";
CM_ SG_ 1319 DI_a250_tasRequest "Drive inverter: a250 tas request";
CM_ SG_ 1319 DI_a250_tasMIA "Drive inverter: a250 tas MIA";
CM_ BO_ 871 "Drive inverter message: alert matrix1";
CM_ SG_ 871 DI_a001_frunkSpeedLimitActive "Drive inverter: a001 frunk speed limit active";
CM_ SG_ 871 DI_a002_parkButtonDuringStalkReq "Drive inverter: a002 park button during stalk req";
CM_ SG_ 871 DI_a003_suggestedGearOverride "Drive inverter: a003 suggested gear override";
CM_ SG_ 871 DI_a004_smartShiftUnavailable "Drive inverter: a004 smart shift unavailable";
CM_ SG_ 871 DI_a005_stalkPanicked "Drive inverter: a005 stalk panicked";
CM_ SG_ 871 DI_a006_shifterUnavailable "Drive inverter: a006 shifter unavailable";
CM_ SG_ 871 DI_a007_secGearSelButtonStuck "Drive inverter: a007 sec gear sel button stuck";
CM_ SG_ 871 DI_a010_unintendedReset "Drive inverter: a010 unintended reset";
CM_ SG_ 871 DI_a012_accel5VSupply "Drive inverter: a012 accel5 v supply";
CM_ SG_ 871 DI_a013_eccError "Drive inverter: a013 ecc error";
CM_ SG_ 871 DI_a014_secGearSelActivated "Drive inverter: a014 sec gear sel activated";
CM_ SG_ 871 DI_a015_immobilizer "Drive inverter: a015 immobilizer";
CM_ SG_ 871 DI_a016_parkRequestByPM "Drive inverter: a016 park request by PM";
CM_ SG_ 871 DI_a017_hwPedalMonitor "Drive inverter: a017 hw pedal monitor";
CM_ SG_ 871 DI_a018_hwLVSupplyUV "Drive inverter: a018 hw LV supply UV";
CM_ SG_ 871 DI_a019_hwAccelPedalPower "Drive inverter: a019 hw accel pedal power";
CM_ SG_ 871 DI_a020_systemHvilNotClosed "Drive inverter: a020 system hvil not closed";
CM_ SG_ 871 DI_a021_packOvervoltage "Drive inverter: a021 pack overvoltage";
CM_ SG_ 871 DI_a022_hw5vSupplyUV "Drive inverter: a022 hw5v supply UV";
CM_ SG_ 871 DI_a023_carNotParked "Drive inverter: a023 car not parked";
CM_ SG_ 871 DI_a024_holdNForNeutral "Drive inverter: a024 hold n for neutral";
CM_ SG_ 871 DI_a025_regenBackfillUnavailable "Drive inverter: a025 regen backfill unavailable";
CM_ SG_ 871 DI_a026_parkPressedWithHighAPeda "Drive inverter: a026 park pressed with high a pedal";
CM_ SG_ 871 DI_a031_closureAccelerationLimit "Drive inverter: a031 closure acceleration limit";
CM_ SG_ 871 DI_a036_sysStandbyUnitLimitedWai "Drive inverter: a036 sys standby unit limited wait";
CM_ SG_ 871 DI_a038_idleTaskStarving "Drive inverter: a038 idle task starving";
CM_ SG_ 871 DI_a039_exceptionUndefinedInstru "Drive inverter: a039 exception undefined instruction";
CM_ SG_ 871 DI_a040_difMIA "Drive inverter: a040 dif MIA";
CM_ SG_ 871 DI_a041_driverBrakeApplyStuck "Drive inverter: a041 driver brake apply stuck";
CM_ SG_ 871 DI_a042_pmfMIA "Drive inverter: a042 pmf MIA";
CM_ SG_ 871 DI_a043_pmrMIA "Drive inverter: a043 pmr MIA";
CM_ SG_ 871 DI_a048_ecuLogAvailable "Drive inverter: a048 ecu log available";
CM_ SG_ 871 DI_a049_P0632_DI_ECU_OdometerNot "Drive inverter: a049 P0632 DI ECU odometer not programmed";
CM_ SG_ 871 DI_a050_P1234_DI_ECU_DemoTimer "Drive inverter: a050 P1234 DI ECU demo timer";
CM_ SG_ 871 DI_a051_batteryOvercurrent "Drive inverter: a051 battery overcurrent";
CM_ SG_ 871 DI_a052_dirMIA "Drive inverter: a052 dir MIA";
CM_ SG_ 871 DI_a053_canDataBusC "Drive inverter: a053 can data bus c";
CM_ SG_ 871 DI_a054_canOverrunBusC "Drive inverter: a054 can overrun bus c";
CM_ SG_ 871 DI_a055_canHardwareBusC "Drive inverter: a055 can hardware bus c";
CM_ SG_ 871 DI_a056_canDataBusD "Drive inverter: a056 can data bus d";
CM_ SG_ 871 DI_a057_canOverrunBusD "Drive inverter: a057 can overrun bus d";
CM_ SG_ 871 DI_a058_canHardwareBusD "Drive inverter: a058 can hardware bus d";
CM_ SG_ 871 DI_a059_canDataBusE "Drive inverter: a059 can data bus e";
CM_ SG_ 871 DI_a060_canOverrunBusE "Drive inverter: a060 can overrun bus e";
CM_ SG_ 871 DI_a061_canHardwareBusE "Drive inverter: a061 can hardware bus e";
CM_ SG_ 871 DI_a062_systemLimpMode "Drive inverter: a062 system limp mode";
CM_ SG_ 871 DI_a063_systemGracefulPowerOff "Drive inverter: a063 system graceful power off";
CM_ SG_ 871 DI_a064_pmsrmUnitMiaWithHvDown "Drive inverter: a064 pmsrm unit mia with hv down";
CM_ BO_ 872 "Drive inverter message: alert matrix2";
CM_ SG_ 872 DI_a065_canHardwareBusB "Drive inverter: a065 can hardware bus b";
CM_ SG_ 872 DI_a066_canDataBusB "Drive inverter: a066 can data bus b";
CM_ SG_ 872 DI_a067_canOverrunBusB "Drive inverter: a067 can overrun bus b";
CM_ SG_ 872 DI_a068_secondaryWheelSpeedIrrat "Drive inverter: a068 secondary wheel speed irrational";
CM_ SG_ 872 DI_a069_P1234_DI_ECU_DemoWindow "Drive inverter: a069 P1234 DI ECU demo window";
CM_ SG_ 872 DI_a070_udsTransactionInitiated "Drive inverter: a070 uds transaction initiated";
CM_ SG_ 872 DI_a076_lvSupplyOV "Drive inverter: a076 lv supply OV";
CM_ SG_ 872 DI_a077_lvSupplyUV "Drive inverter: a077 lv supply UV";
CM_ SG_ 872 DI_a078_adcRefLow "Drive inverter: a078 adc ref low";
CM_ SG_ 872 DI_a079_adcRefHigh "Drive inverter: a079 adc ref high";
CM_ SG_ 872 DI_a080_accelSynch "Drive inverter: a080 accel synch";
CM_ SG_ 872 DI_a081_accelTrack1 "Drive inverter: a081 accel track1";
CM_ SG_ 872 DI_a082_accelTrack2 "Drive inverter: a082 accel track2";
CM_ SG_ 872 DI_a083_brakePedalSensor "Drive inverter: a083 brake pedal sensor";
CM_ SG_ 872 DI_a084_eccTestData0 "Drive inverter: a084 ecc test data0";
CM_ SG_ 872 DI_a085_proximityInEnable "Drive inverter: a085 proximity in enable";
CM_ SG_ 872 DI_a086_dpbMIA "Drive inverter: a086 dpb MIA";
CM_ SG_ 872 DI_a087_gtwMIA "Drive inverter: a087 gtw MIA";
CM_ SG_ 872 DI_a088_uiMIA "Drive inverter: a088 ui MIA";
CM_ SG_ 872 DI_a089_sccmMIA "Drive inverter: a089 sccm MIA";
CM_ SG_ 872 DI_a090_pmMIA "Drive inverter: a090 pm MIA";
CM_ SG_ 872 DI_a091_espMIA "Drive inverter: a091 esp MIA";
CM_ SG_ 872 DI_a092_bmsMIA "Drive inverter: a092 bms MIA";
CM_ SG_ 872 DI_a093_canHardwareBusA "Drive inverter: a093 can hardware bus a";
CM_ SG_ 872 DI_a094_canDataBusA "Drive inverter: a094 can data bus a";
CM_ SG_ 872 DI_a095_canOverrunBusA "Drive inverter: a095 can overrun bus a";
CM_ SG_ 872 DI_a096_memoryError "Drive inverter: a096 memory error";
CM_ SG_ 872 DI_a097_eepromError "Drive inverter: a097 eeprom error";
CM_ SG_ 872 DI_a098_eepromManagerError "Drive inverter: a098 eeprom manager error";
CM_ SG_ 872 DI_a099_threadOverrun "Drive inverter: a099 thread overrun";
CM_ SG_ 872 DI_a100_nvramError "Drive inverter: a100 nvram error";
CM_ SG_ 872 DI_a101_eccTestData1 "Drive inverter: a101 ecc test data1";
CM_ SG_ 872 DI_a102_exceptionPrefetchAbort "Drive inverter: a102 exception prefetch abort";
CM_ SG_ 872 DI_a103_bbMIA "Drive inverter: a103 bb MIA";
CM_ SG_ 872 DI_a104_proximityIrrational "Drive inverter: a104 proximity irrational";
CM_ SG_ 872 DI_a105_cpMIA "Drive inverter: a105 cp MIA";
CM_ SG_ 872 DI_a108_appMIA "Drive inverter: a108 app MIA";
CM_ SG_ 872 DI_a109_ahbWriteError "Drive inverter: a109 ahb write error";
CM_ SG_ 872 DI_a110_brakeMIA "Drive inverter: a110 brake MIA";
CM_ SG_ 872 DI_a112_accelTrack1Incons "Drive inverter: a112 accel track1 incons";
CM_ SG_ 872 DI_a114_exceptionDataAbort "Drive inverter: a114 exception data abort";
CM_ SG_ 872 DI_a115_exceptionDataAbort2 "Drive inverter: a115 exception data abort2";
CM_ SG_ 872 DI_a116_motorRecovered "Drive inverter: a116 motor recovered";
CM_ SG_ 872 DI_a117_latentFaultCheckTripped "Drive inverter: a117 latent fault check tripped";
CM_ SG_ 872 DI_a118_diImmobilizedForFactoryF "Drive inverter: a118 di immobilized for factory failsafe";
CM_ SG_ 872 DI_a119_latentFaultCheckFailedOn "Drive inverter: a119 latent fault check failed once";
CM_ SG_ 872 DI_a120_regenBlendingUnavailable "Drive inverter: a120 regen blending unavailable";
CM_ SG_ 872 DI_a121_qualifiedBrakeEventMitig "Drive inverter: a121 qualified brake event mitigation";
CM_ SG_ 872 DI_a122_highStackUsage "Drive inverter: a122 high stack usage";
CM_ SG_ 872 DI_a124_cruiseFault "Drive inverter: a124 cruise fault";
CM_ SG_ 872 DI_a125_noBatteryPower "Drive inverter: a125 no battery power";
CM_ BO_ 875 "Drive inverter message: alert matrix3";
CM_ SG_ 875 DI_a129_epbNotApplied "Drive inverter: a129 epb not applied";
CM_ SG_ 875 DI_a130_aebFault "Drive inverter: a130 aeb fault";
CM_ SG_ 875 DI_a131_highSpeedWearLimit "Drive inverter: a131 high speed wear limit";
CM_ SG_ 875 DI_a133_vehicleHoldTimedOut "Drive inverter: a133 vehicle hold timed out";
CM_ SG_ 875 DI_a134_wheelSpeedIrrational "Drive inverter: a134 wheel speed irrational";
CM_ SG_ 875 DI_a135_vehicleHoldFault "Drive inverter: a135 vehicle hold fault";
CM_ SG_ 875 DI_a137_noCapableDriveUnits "Drive inverter: a137 no capable drive units";
CM_ SG_ 875 DI_a138_frontUnitDisabled "Drive inverter: a138 front unit disabled";
CM_ SG_ 875 DI_a139_rearUnitDisabled "Drive inverter: a139 rear unit disabled";
CM_ SG_ 875 DI_a140_ptcMIA "Drive inverter: a140 ptc MIA";
CM_ SG_ 875 DI_a141_dasMIA "Drive inverter: a141 das MIA";
CM_ SG_ 875 DI_a142_potholeDetected "Drive inverter: a142 pothole detected";
CM_ SG_ 875 DI_a143_mcuLimitActive "Drive inverter: a143 mcu limit active";
CM_ SG_ 875 DI_a144_configMismatch "Drive inverter: a144 config mismatch";
CM_ SG_ 875 DI_a146_pbrkPanicEpbFault "Drive inverter: a146 pbrk panic epb fault";
CM_ SG_ 875 DI_a154_vdcRearSteering "Drive inverter: a154 vdc rear steering";
CM_ SG_ 875 DI_a155_vcfrontMIA "Drive inverter: a155 vcfront MIA";
CM_ SG_ 875 DI_a157_rcmMIA "Drive inverter: a157 rcm MIA";
CM_ SG_ 875 DI_a158_ibstMIA "Drive inverter: a158 ibst MIA";
CM_ SG_ 875 DI_a159_cruiseSelfCheck "Drive inverter: a159 cruise self check";
CM_ SG_ 875 DI_a160_fastLearnComplete "Drive inverter: a160 fast learn complete";
CM_ SG_ 875 DI_a161_epas3pMIA "Drive inverter: a161 epas3p MIA";
CM_ SG_ 875 DI_a162_shiftDenied "Drive inverter: a162 shift denied";
CM_ SG_ 875 DI_a163_shiftMotorSpeed "Drive inverter: a163 shift motor speed";
CM_ SG_ 875 DI_a164_brakeOverride "Drive inverter: a164 brake override";
CM_ SG_ 875 DI_a165_cruiseCancelled "Drive inverter: a165 cruise cancelled";
CM_ SG_ 875 DI_a166_driverLeft "Drive inverter: a166 driver left";
CM_ SG_ 875 DI_a167_keyNotAuthenticated "Drive inverter: a167 key not authenticated";
CM_ SG_ 875 DI_a168_proximityDriveDenial "Drive inverter: a168 proximity drive denial";
CM_ SG_ 875 DI_a169_regenOffOverride "Drive inverter: a169 regen off override";
CM_ SG_ 875 DI_a170_tireConfigUpdated "Drive inverter: a170 tire config updated";
CM_ SG_ 875 DI_a171_driveRailNotRequested "Drive inverter: a171 drive rail not requested";
CM_ SG_ 875 DI_a172_accelPressedInNP "Drive inverter: a172 accel pressed in NP";
CM_ SG_ 875 DI_a173_bothPedalsPressed "Drive inverter: a173 both pedals pressed";
CM_ SG_ 875 DI_a174_notOkToStartDrive "Drive inverter: a174 not ok to start drive";
CM_ SG_ 875 DI_a175_crsNotAvailable "Drive inverter: a175 crs not available";
CM_ SG_ 875 DI_a176_EBRreleased "Drive inverter: a176 EB rreleased";
CM_ SG_ 875 DI_a177_tireFitmentChanged "Drive inverter: a177 tire fitment changed";
CM_ SG_ 875 DI_a178_steeringAngleOffsetFault "Drive inverter: a178 steering angle offset fault";
CM_ SG_ 875 DI_a179_steeringAngleOffsetWarni "Drive inverter: a179 steering angle offset warning";
CM_ SG_ 875 DI_a180_crsSeatbeltUnbuckled "Drive inverter: a180 crs seatbelt unbuckled";
CM_ SG_ 875 DI_a181_rearMotorMode "Drive inverter: a181 rear motor mode";
CM_ SG_ 875 DI_a182_frontMotorMode "Drive inverter: a182 front motor mode";
CM_ SG_ 875 DI_a183_holdReleaseRqrd "Drive inverter: a183 hold release rqrd";
CM_ SG_ 875 DI_a184_autoparkCanceled "Drive inverter: a184 autopark canceled";
CM_ SG_ 875 DI_a185_autoparkAborted "Drive inverter: a185 autopark aborted";
CM_ SG_ 875 DI_a186_brakeStand "Drive inverter: a186 brake stand";
CM_ SG_ 875 DI_a187_pedalMisapplication "Drive inverter: a187 pedal misapplication";
CM_ SG_ 875 DI_a188_tireRotationRecommendedG "Drive inverter: a188 tire rotation recommended ghosted";
CM_ SG_ 875 DI_a189_garageShiftWithPedal "Drive inverter: a189 garage shift with pedal";
CM_ SG_ 875 DI_a190_tireRotationRecommended "Drive inverter: a190 tire rotation recommended";
CM_ SG_ 875 DI_a191_brakeShiftReq "Drive inverter: a191 brake shift req";
CM_ SG_ 875 DI_a192_invalidOdometer "Drive inverter: a192 invalid odometer";
CM_ BO_ 878 "Drive inverter message: alert matrix4";
CM_ SG_ 878 DI_a193_vdcBrakeTorqueFr "Drive inverter: a193 vdc brake torque fr";
CM_ SG_ 878 DI_a194_vdcBrakeTorqueRe "Drive inverter: a194 vdc brake torque re";
CM_ SG_ 878 DI_a195_vdcEspSlipFr "Drive inverter: a195 vdc esp slip fr";
CM_ SG_ 878 DI_a196_vdcEspSlipRe "Drive inverter: a196 vdc esp slip re";
CM_ SG_ 878 DI_a197_vdcEspWheelSaturations "Drive inverter: a197 vdc esp wheel saturations";
CM_ SG_ 878 DI_a198_vdcEspMCPressAndSteering "Drive inverter: a198 vdc esp MC press and steering";
CM_ SG_ 878 DI_a199_vdcFaulted "Drive inverter: a199 vdc faulted";
CM_ SG_ 878 DI_a200_vdcModelBasedPlausibilit "Drive inverter: a200 vdc model based plausibility";
CM_ SG_ 878 DI_a201_decelTorqueLimited "Drive inverter: a201 decel torque limited";
CM_ SG_ 878 DI_a202_excessHeatUnavailable "Drive inverter: a202 excess heat unavailable";
CM_ SG_ 878 DI_a203_TCReducedByADD "Drive inverter: a203 TC reduced by ADD";
CM_ SG_ 878 DI_a204_vdcRcmLongitudinal "Drive inverter: a204 vdc rcm longitudinal";
CM_ SG_ 878 DI_a205_vdcRcmLateral "Drive inverter: a205 vdc rcm lateral";
CM_ SG_ 878 DI_a206_vdcRcmVertical "Drive inverter: a206 vdc rcm vertical";
CM_ SG_ 878 DI_a207_vdcPowertrainTorque_dif "Drive inverter: a207 vdc powertrain torque dif";
CM_ SG_ 878 DI_a208_vdcPowertrainTorque_dir "Drive inverter: a208 vdc powertrain torque dir";
CM_ SG_ 878 DI_a210_vdcOtherControllerStates "Drive inverter: a210 vdc other controller states";
CM_ SG_ 878 DI_a211_vdcMotorSpeed_dif "Drive inverter: a211 vdc motor speed dif";
CM_ SG_ 878 DI_a212_vdcWheelRotations "Drive inverter: a212 vdc wheel rotations";
CM_ SG_ 878 DI_a213_lowMuProbabilityChange "Drive inverter: a213 low mu probability change";
CM_ SG_ 878 DI_a214_vdcWheelSpeedFr "Drive inverter: a214 vdc wheel speed fr";
CM_ SG_ 878 DI_a215_vdcWheelSpeedRe "Drive inverter: a215 vdc wheel speed re";
CM_ SG_ 878 DI_a216_vdcMBPAlmostTripped "Drive inverter: a216 vdc MBP almost tripped";
CM_ SG_ 878 DI_a217_vdcOutputIrrational "Drive inverter: a217 vdc output irrational";
CM_ SG_ 878 DI_a218_vdcOSPreControlActive "Drive inverter: a218 vdc OS pre control active";
CM_ SG_ 878 DI_a219_vdcOversteerdMzActive "Drive inverter: a219 vdc oversteerd mz active";
CM_ SG_ 878 DI_a220_vdcUndersteerDecelActive "Drive inverter: a220 vdc understeer decel active";
CM_ SG_ 878 DI_a221_vdcUndersteerdMzActive "Drive inverter: a221 vdc understeerd mz active";
CM_ SG_ 878 DI_a222_vdcDisabled "Drive inverter: a222 vdc disabled";
CM_ SG_ 878 DI_a223_tractionControlDisabled "Drive inverter: a223 traction control disabled";
CM_ SG_ 878 DI_a224_brakeOverTemp "Drive inverter: a224 brake over temp";
CM_ SG_ 878 DI_a225_vyEstimatorDegradedDebug "Drive inverter: a225 vy estimator degraded debug";
CM_ SG_ 878 DI_a226_sysStartConditionNotMet "Drive inverter: a226 sys start condition not met";
CM_ SG_ 878 DI_a227_contactorsNotClosed "Drive inverter: a227 contactors not closed";
CM_ SG_ 878 DI_a228_brakeTempEstUnavailable "Drive inverter: a228 brake temp est unavailable";
CM_ SG_ 878 DI_a230_cmpMIA "Drive inverter: a230 cmp MIA";
CM_ SG_ 878 DI_a231_unintendedReset2 "Drive inverter: a231 unintended reset2";
CM_ SG_ 878 DI_a232_velocityEstimatorDegrade "Drive inverter: a232 velocity estimator degraded";
CM_ SG_ 878 DI_a233_frontWheelImpactDetected "Drive inverter: a233 front wheel impact detected";
CM_ SG_ 878 DI_a235_trackModeActive "Drive inverter: a235 track mode active";
CM_ SG_ 878 DI_a236_tasMIA "Drive inverter: a236 tas MIA";
CM_ SG_ 878 DI_a237_undersideAbuse "Drive inverter: a237 underside abuse";
CM_ SG_ 878 DI_a238_secondaryCollisionMitiga "Drive inverter: a238 secondary collision mitigation active";
CM_ SG_ 878 DI_a239_neutralRequestByPM "Drive inverter: a239 neutral request by PM";
CM_ SG_ 878 DI_a240_torqueSplitStuck "Drive inverter: a240 torque split stuck";
CM_ SG_ 878 DI_a241_vdcMotorSpeed_dir "Drive inverter: a241 vdc motor speed dir";
CM_ SG_ 878 DI_a242_vdcTrailerSwayDetected "Drive inverter: a242 vdc trailer sway detected";
CM_ SG_ 878 DI_a243_rcuMIA "Drive inverter: a243 rcu MIA";
CM_ SG_ 878 DI_a244_vseRLSMassMismatch "Drive inverter: a244 vse RLS mass mismatch";
CM_ SG_ 878 DI_a245_opdReducedWithoutEbr "Drive inverter: a245 opd reduced without ebr";
CM_ SG_ 878 DI_a246_opdUnavailable "Drive inverter: a246 opd unavailable";
CM_ SG_ 878 DI_a248_vdcPreControlHighDynamic "Drive inverter: a248 vdc pre control high dynamic active";
CM_ SG_ 878 DI_a249_spinDownLearningInProgre "Drive inverter: a249 spin down learning in progress";
CM_ SG_ 878 DI_a250_tasSpeedLimitActive "Drive inverter: a250 tas speed limit active";
CM_ SG_ 878 DI_a251_diPowerOnStateMismatch "Drive inverter: a251 di power on state mismatch";
CM_ SG_ 878 DI_a253_accelSynchWarn "Drive inverter: a253 accel synch warn";
CM_ SG_ 878 DI_a254_vehicleStuckDetected "Drive inverter: a254 vehicle stuck detected";
CM_ BO_ 328 "Drive inverter message: chassis control";
CM_ SG_ 328 DI_chassisControlChecksum "Drive inverter: chassis control checksum";
CM_ SG_ 328 DI_chassisControlCounter "Drive inverter: chassis control counter";
CM_ SG_ 328 DI_imuOffsetLearnRequest "Drive inverter: imu offset learn request";
CM_ SG_ 328 DI_brakeCommandType "Drive inverter: brake command type";
CM_ SG_ 328 DI_brakeTorqueRequestActive "Drive inverter: brake torque request active";
CM_ SG_ 328 DI_brakeTorqueCommand "Brake torque command to ESP";
CM_ SG_ 328 DI_ptcStateGlobal "Indicates state of Tesla traction control system; raw 3 = signal not available (SNA)";
CM_ SG_ 328 DI_ptcActive "TRUE when pedal-positive (drive) traction control is active";
CM_ SG_ 328 DI_vdcState "Status of VDC";
CM_ SG_ 328 DI_isAnyVdcControlActive "Drive inverter: is any vdc control active";
CM_ SG_ 328 DI_vdcMode "Indicates mode of VDC";
CM_ SG_ 328 DI_pedalAssistCurveSelect "Drive inverter: pedal assist curve select";
CM_ SG_ 328 DI_isAnyTcActive "TRUE when either drive or regen traction control is active";
CM_ SG_ 328 DI_VehicleMuConfidence "Confidence in surface mu estimate for development use only";
CM_ SG_ 328 DI_VehicleMu "Learn-up estimate of surface mu for development use only";
CM_ SG_ 328 DI_trailerSwayIndex "VDC trailer sway index";
CM_ SG_ 328 DI_vdcControlActive "Type of VDC control while VDC is actuating";
CM_ SG_ 328 DI_treadDepthAlertSet "Drive inverter: tread depth alert set";
CM_ BO_ 1861 "Drive inverter message: chassis control2";
CM_ SG_ 1861 DI_gradeAngle "Reports the grade angle.";
CM_ SG_ 1861 DI_bankAngle "Reports the bank angle.";
CM_ SG_ 1861 DI_chassisControlVideoRequest "Drive inverter: chassis control video request";
CM_ SG_ 1861 DI_tireUtilizationRatioFrL "Drive inverter: tire utilization ratio fr l";
CM_ SG_ 1861 DI_tireUtilizationRatioFrR "Drive inverter: tire utilization ratio fr r";
CM_ SG_ 1861 DI_tireUtilizationRatioReL "Drive inverter: tire utilization ratio re l";
CM_ SG_ 1861 DI_tireUtilizationRatioReR "Drive inverter: tire utilization ratio re r";
CM_ SG_ 1861 DI_counterSteerTarget "Drive inverter: counter steer target";
CM_ SG_ 1861 DI_splitMuProbability "Drive inverter: split mu probability";
CM_ SG_ 1861 DI_mzError "Drive inverter: mz error";
CM_ SG_ 1861 DI_slipDifferenceFrontRear "Drive inverter: slip difference front rear";
CM_ SG_ 1861 DI_highFreqYawRate "Drive inverter: high freq yaw rate";
CM_ SG_ 1861 DI_turnDirection "Drive inverter: turn direction";
CM_ SG_ 1861 DI_absolutePreControlRequest "Drive inverter: absolute pre control request";
CM_ SG_ 1861 DI_oppositeBuildDirFrontAxle "Drive inverter: opposite build dir front axle";
CM_ SG_ 1861 DI_oppositeBuildDirRearAxle "Drive inverter: opposite build dir rear axle";
CM_ SG_ 1861 DI_saturatedEffectiveness "Drive inverter: saturated effectiveness";
CM_ SG_ 1861 DI_driverPanicIndex "Drive inverter: driver panic index";
CM_ SG_ 1861 DI_learnDownMu "Drive inverter: learn down mu";
CM_ SG_ 1861 DI_preControlOpposingTurnDir "Drive inverter: pre control opposing turn dir";
CM_ SG_ 1861 DI_driverFxError "Drive inverter: driver fx error";
CM_ SG_ 1861 DI_targetSaturation "Drive inverter: target saturation";
CM_ BO_ 1869 "Drive inverter message: chassis control3";
CM_ SG_ 1869 DI_tireWearFactor_FrL "Drive inverter: tire wear factor fr l";
CM_ SG_ 1869 DI_tireWearFactor_FrR "Drive inverter: tire wear factor fr r";
CM_ SG_ 1869 DI_tireWearFactor_ReL "Drive inverter: tire wear factor re l";
CM_ SG_ 1869 DI_tireWearFactor_ReR "Drive inverter: tire wear factor re r";
CM_ SG_ 1869 DI_kTireEstReUnSat "Drive inverter: k tire est re un sat; raw 127 = signal not available (SNA)";
CM_ SG_ 1869 DI_tireConfigSaved "Drive inverter: tire config saved";
CM_ SG_ 1869 DI_distanceSinceLastTireConfig "distance since odometer reading when Tire Configuration was last run; raw 63 = signal not available (SNA)";
CM_ SG_ 1869 DI_hydroplaningRisk "Drive inverter: hydroplaning risk";
CM_ SG_ 1869 DI_hydroplaningPuddlesWet "Drive inverter: hydroplaning puddles wet";
CM_ SG_ 1869 DI_hydroplaningPuddlesDry "Drive inverter: hydroplaning puddles dry";
CM_ SG_ 1869 DI_vehicleStuck "Drive inverter: vehicle stuck";
CM_ SG_ 1869 DI_kTireEstRe "Drive inverter: k tire est re; raw 31 = signal not available (SNA)";
CM_ SG_ 1869 DI_stickyMu "Drive inverter: sticky mu";
CM_ SG_ 1869 DI_stickyMuConfidence "Drive inverter: sticky mu confidence";
CM_ BO_ 694 "Drive inverter message: chassis control status";
CM_ SG_ 694 DI_vdcTelltaleFlash "Request to flash telltale in UI when VDC is active";
CM_ SG_ 694 DI_vdcTelltaleOn "Request to turn telltale ON in UI when VDC is faulted";
CM_ SG_ 694 DI_tcTelltaleFlash "Request to flash telltale in UI when TC is active";
CM_ SG_ 694 DI_tcTelltaleOn "Request to turn telltale ON in UI when TC is faulted";
CM_ SG_ 694 DI_tractionControlModeUI "Drive inverter: traction control mode UI";
CM_ SG_ 694 DI_ptcStateGlobalUI "Drive inverter: ptc state global UI; raw 3 = signal not available (SNA)";
CM_ SG_ 694 DI_btcStateUI "Drive inverter: btc state UI";
CM_ SG_ 694 DI_vehicleHoldTelltaleOn "Drive inverter: vehicle hold telltale on";
CM_ SG_ 694 DI_opdFeedbackReset "Drive inverter: opd feedback reset";
CM_ SG_ 694 DI_opdFeedbackResetPositiveSpeed "Drive inverter: opd feedback reset positive speeds";
CM_ SG_ 694 DI_slipperySurfaceOnUI "Drive inverter: slippery surface on UI";
CM_ SG_ 694 DI_yellowBrakeTelltaleOn "Request to turn yellow BRAKE telltale ON in UI";
CM_ SG_ 694 DI_greenABSTelltaleOn "Drive inverter: green ABS telltale on";
CM_ BO_ 2007 "Drive inverter message: debug";
CM_ SG_ 2007 DI_debugSelector "Drive inverter: debug selector";
CM_ SG_ 2007 DI_regenBackfillCmd "Drive inverter: regen backfill cmd";
CM_ SG_ 2007 DI_regenBackfillUnavailableReaso "Drive inverter: regen backfill unavailable reason";
CM_ SG_ 2007 DI_regenBackfillAbsSatState "Drive inverter: regen backfill abs sat state";
CM_ SG_ 2007 DI_sysHeatPowerOptimal "Drive inverter: sys heat power optimal";
CM_ SG_ 2007 DI_sysPostPedalMinTorque "Drive inverter: sys post pedal min torque";
CM_ SG_ 2007 DI_sysPostPedalMaxTorque "Drive inverter: sys post pedal max torque";
CM_ SG_ 2007 DI_systemTorqueCommand "Drive inverter: system torque command";
CM_ BO_ 1866 "Drive inverter message: estimated brake temp";
CM_ SG_ 1866 DI_estimatedBrakeTempChecksum "Drive inverter: estimated brake temp checksum";
CM_ SG_ 1866 DI_estimatedBrakeTempCounter "Drive inverter: estimated brake temp counter";
CM_ SG_ 1866 DI_brakeFLTemp "Drive inverter: brake FL temp; raw 1023 = signal not available (SNA)";
CM_ SG_ 1866 DI_brakeFRTemp "Drive inverter: brake FR temp; raw 1023 = signal not available (SNA)";
CM_ SG_ 1866 DI_brakeRLTemp "Drive inverter: brake RL temp; raw 1023 = signal not available (SNA)";
CM_ SG_ 1866 DI_brakeRRTemp "Drive inverter: brake RR temp; raw 1023 = signal not available (SNA)";
CM_ BO_ 1623 "Drive inverter message: info";
CM_ SG_ 1623 DI_infoIndex "Drive inverter: info index";
CM_ SG_ 1623 DI_buildType "Drive inverter: build type";
CM_ SG_ 1623 DI_buildConfigurationId "Drive inverter: build configuration id";
CM_ SG_ 1623 DI_hardwareId "Drive inverter: hardware id";
CM_ SG_ 1623 DI_componentId "Drive inverter: component id";
CM_ SG_ 1623 DI_pcbaId "Drive inverter: pcba id";
CM_ SG_ 1623 DI_assemblyId "Drive inverter: assembly id";
CM_ SG_ 1623 DI_usageId "Drive inverter: usage id";
CM_ SG_ 1623 DI_subUsageId "Drive inverter: sub usage id";
CM_ SG_ 1623 DI_applicationCrc "Drive inverter: application crc";
CM_ SG_ 1623 DI_bootGitHash "Drive inverter: boot git hash";
CM_ BO_ 646 "Drive inverter message: loc status";
CM_ SG_ 646 DI_locStatusChecksum "Drive inverter: loc status checksum";
CM_ SG_ 646 DI_locStatusCounter "Drive inverter: loc status counter";
CM_ SG_ 646 DI_cruiseState "Cruise control state.";
CM_ SG_ 646 DI_cruiseSetSpeed "Cruise control set point.";
CM_ SG_ 646 DI_cruiseSetSpeedUnits "Drive inverter: cruise set speed units";
CM_ SG_ 646 DI_autoparkState "Drive inverter: autopark state; raw 15 = signal not available (SNA)";
CM_ SG_ 646 DI_parkBrakeState "DI Park Brake control and EPB interface state; raw 15 = signal not available (SNA)";
CM_ SG_ 646 DI_aebState "Reports the Automatic Emergency Braking (AEB) state; raw 7 = signal not available (SNA)";
CM_ SG_ 646 DI_loncDeactivationReason "Drive inverter: lonc deactivation reason";
CM_ SG_ 646 DI_vehicleHoldState "Vehicle hold state.";
CM_ SG_ 646 DI_summonInPanic "Drive inverter: summon in panic";
CM_ SG_ 646 DI_onePedalDrivingState "One Pedal Driving State machine state";
CM_ SG_ 646 DI_brakeStandActive "Detects active brake stand.";
CM_ SG_ 646 DI_regenBackfillState "Regen backfill state";
CM_ SG_ 646 DI_cruiseNotAvailableReason "Drive inverter: cruise not available reason; raw 20 = signal not available (SNA)";
CM_ SG_ 646 DI_cruiseFaultReason "Cruise control fault reason; raw 17 = signal not available (SNA)";
CM_ SG_ 646 DI_cruiseCancelReason "Cruise control cancel reason";
CM_ BO_ 1270 "Drive inverter message: loc status2";
CM_ SG_ 1270 DI_locStatus2Checksum "Drive inverter: loc status2 checksum";
CM_ SG_ 1270 DI_locStatus2Counter "Drive inverter: loc status2 counter";
CM_ SG_ 1270 DI_doublePedalState "Drive inverter: double pedal state";
CM_ SG_ 1270 DI_autopilotRequest "Drive inverter: autopilot request";
CM_ SG_ 1270 DI_rollPreventionState "Drive inverter: roll prevention state";
CM_ SG_ 1270 DI_locIntegratorSaturated "Drive inverter: loc integrator saturated";
CM_ SG_ 1270 DI_temporaryOpdActiveAfterLoncCa "Drive inverter: temporary opd active after lonc cancel";
CM_ SG_ 1270 DI_reapplyOnParkRequest "Drive inverter: reapply on park request";
CM_ SG_ 1270 DI_regenBlendingState "Drive inverter: regen blending state";
CM_ SG_ 1270 DI_brakeCpScale "Drive inverter: brake cp scale";
CM_ SG_ 1270 DI_rollbackDistance "Maximum vehicle rollback distance in current stopping event when OPD/Cruise is active";
CM_ SG_ 1270 DI_lowMuProbabilityConfidence "Drive inverter: low mu probability confidence";
CM_ SG_ 1270 DI_pedalAssistCurveSelectForSX "Drive inverter: pedal assist curve select for SX";
CM_ SG_ 1270 DI_longitudinalControlStack "Drive inverter: longitudinal control stack; raw 0 = signal not available (SNA)";
CM_ BO_ 822 "Drive inverter message: max rated power";
CM_ SG_ 822 DI_sysDrivePowerRated "Drive inverter: sys drive power rated; raw 511 = signal not available (SNA)";
CM_ SG_ 822 DI_obdDriveCycleStatus "OBD qualified drive cycle status";
CM_ SG_ 822 DI_performancePackage "Drive inverter: performance package; raw 7 = signal not available (SNA)";
CM_ SG_ 822 DI_sysRegenPowerRated "Drive inverter: sys regen power rated; raw 255 = signal not available (SNA)";
CM_ BO_ 950 "Drive inverter message: odometer status";
CM_ SG_ 950 DI_odometer "Total traveled distance; raw 4294967295 = signal not available (SNA)";
CM_ SG_ 950 DI_odometerStatusCounter "Drive inverter: odometer status counter";
CM_ SG_ 950 DI_odometerStatusChecksum "Drive inverter: odometer status checksum";
CM_ BO_ 599 "Drive inverter message: speed";
CM_ SG_ 599 DI_speedChecksum "Drive inverter: speed checksum";
CM_ SG_ 599 DI_speedCounter "Drive inverter: speed counter";
CM_ SG_ 599 DI_opdVehicleModelSpeedRef "Drive inverter: opd vehicle model speed ref";
CM_ SG_ 599 DI_uiSpeed "Drive inverter: ui speed; raw 511 = signal not available (SNA)";
CM_ SG_ 599 DI_uiSpeedUnits "Drive inverter: ui speed units";
CM_ SG_ 599 DI_accelPedalPressed "TRUE when the calibrated accel pedal position > 0.0";
CM_ SG_ 599 DI_sideslipEstimate "Drive inverter: sideslip estimate";
CM_ SG_ 599 DI_vehicleSpeed "Reports vehicle speed; raw 8191 = signal not available (SNA)";
CM_ SG_ 599 DI_velocityEstimatorState "Drive inverter: velocity estimator state";
CM_ SG_ 599 DI_autoEnableHazards "Drive inverter: auto enable hazards";
CM_ SG_ 599 DI_longControlCommandActive "Drive inverter: long control command active";
CM_ BO_ 2006 "Drive inverter message: stalkless interfaces";
CM_ SG_ 2006 DI_stalklessInterfacesChecksum "Drive inverter: stalkless interfaces checksum";
CM_ SG_ 2006 DI_stalklessInterfacesCounter "Drive inverter: stalkless interfaces counter";
CM_ SG_ 2006 DI_smartShiftClosureOpen "Drive inverter: smart shift closure open";
CM_ SG_ 2006 DI_smartShiftSeatbeltUnbuckled "Drive inverter: smart shift seatbelt unbuckled";
CM_ SG_ 2006 DI_smartShiftAvailable "Drive inverter: smart shift available";
CM_ SG_ 2006 DI_smartShiftPrimed "Drive inverter: smart shift primed";
CM_ SG_ 2006 DI_smartShiftBrakePressed "Drive inverter: smart shift brake pressed";
CM_ SG_ 2006 DI_smartShiftBrakeReapplyRequire "Drive inverter: smart shift brake reapply required";
CM_ BO_ 597 "Drive inverter message: suggested gear";
CM_ SG_ 597 DI_lastQualifiedGear "Drive inverter: last qualified gear; raw 7 = signal not available (SNA)";
CM_ SG_ 597 DI_lastDrivingGear "Drive inverter: last driving gear; raw 7 = signal not available (SNA)";
CM_ SG_ 597 DI_distDrivenInGear "Drive inverter: dist driven in gear";
CM_ SG_ 597 DI_frontBlocked "Drive inverter: front blocked";
CM_ SG_ 597 DI_rearBlocked "Drive inverter: rear blocked";
CM_ SG_ 597 DI_firstShiftOccurred "Drive inverter: first shift occurred";
CM_ SG_ 597 DI_suggestedGearReason "Reason for the suggested gear";
CM_ SG_ 597 DI_parallelParked "Drive inverter: parallel parked";
CM_ SG_ 597 DI_smartShiftGear "Gear vehicle will shift into if smart shift occurs";
CM_ SG_ 597 DI_smartShiftUnavailableReason "Reports the reason why Smart Shift is unavailable; raw 0 = signal not available (SNA)";
CM_ BO_ 296 "Drive inverter message: system limits";
CM_ SG_ 296 DI_limitRegenPower "TRUE when torque is limited due to regen power limit.";
CM_ SG_ 296 DI_limitIBat "TRUE when torque is limited due to battery current.";
CM_ SG_ 296 DI_limitVBatLow "Drive inverter: limit v bat low";
CM_ SG_ 296 DI_limitVBatHigh "Drive inverter: limit v bat high";
CM_ SG_ 296 DI_limitObstacleDetection "TRUE when torque is limited due to obstacle detected in vehicle path.";
CM_ SG_ 296 DI_limitSystemLimp "Drive inverter: limit system limp";
CM_ SG_ 296 DI_limitSystemGPO "Drive inverter: limit system GPO";
CM_ SG_ 296 DI_limitShift "Drive inverter: limit shift";
CM_ SG_ 296 DI_limitDriveTorque "TRUE when drive torque is limited due to driver torque limit command";
CM_ SG_ 296 DI_limitRegenTorque "TRUE when regen torque is limited due to driver torque limit command";
CM_ SG_ 296 DI_limitVehicleSpeed "Drive inverter: limit vehicle speed";
CM_ SG_ 296 DI_limitBmsMiaFreeze "Drive inverter: limit bms mia freeze";
CM_ SG_ 296 DI_limitSystemSpinDownLearning "Drive inverter: limit system spin down learning";
CM_ SG_ 296 DI_limitCdp "Drive inverter: limit cdp";
CM_ SG_ 296 DI_vehicleSpeedLimitType "Speed limit source/type of DI_vehicleSpeedLimit.";
CM_ SG_ 296 DI_vehicleSpeedLimit "Vehicle speed limit (including powertrain limits) being enforced by the DI and published to the UI; raw 511 = signal not available (SNA)";
CM_ SG_ 296 DI_vehicleSpeedLimitReason "Speed limit reason of DI_vehicleSpeedLimit.";
CM_ SG_ 296 DI_limitClosureNotClosed "Drive inverter: limit closure not closed";
CM_ SG_ 296 DI_proximity "TRUE if the proximity hardware input signal is active.";
CM_ SG_ 296 DI_undersideAbuse "Drive inverter: underside abuse";
BA_DEF_ BO_ "GenMsgCycleTime" INT 0 3600000;
BA_DEF_ BO_ "GenMsgSendType" ENUM "Cyclic","NotUsed","NotUsed","NotUsed","NotUsed","NotUsed","NotUsed","IfActive","NoMsgSendType","NotUsed";
BA_DEF_ BO_ "VFrameFormat" ENUM "StandardCAN","ExtendedCAN","reserved","J1939PG","reserved","reserved","reserved","reserved","reserved","reserved","reserved","reserved","reserved","reserved","StandardCAN_FD","ExtendedCAN_FD";
BA_DEF_ BO_ "CANFD_BRS" ENUM "0","1";
BA_DEF_ SG_ "GenSigSNA" STRING;
BA_DEF_ SG_ "SystemSignalLongSymbol" STRING;
BA_DEF_ SG_ "Confidence" ENUM "validated","plausible","layout-only","contradicted";
BA_DEF_DEF_ "GenMsgCycleTime" 0;
BA_DEF_DEF_ "GenMsgSendType" "NoMsgSendType";
BA_DEF_DEF_ "VFrameFormat" "StandardCAN";
BA_DEF_DEF_ "CANFD_BRS" "1";
BA_DEF_DEF_ "GenSigSNA" "";
BA_DEF_DEF_ "SystemSignalLongSymbol" "";
BA_DEF_DEF_ "Confidence" "layout-only";
BA_ "GenMsgCycleTime" BO_ 871 1000;
BA_ "GenMsgSendType" BO_ 871 0;
BA_ "GenMsgCycleTime" BO_ 872 1000;
BA_ "GenMsgSendType" BO_ 872 0;
BA_ "GenMsgCycleTime" BO_ 875 1000;
BA_ "GenMsgSendType" BO_ 875 0;
BA_ "GenMsgCycleTime" BO_ 878 1000;
BA_ "GenMsgSendType" BO_ 878 0;
BA_ "GenMsgCycleTime" BO_ 328 20;
BA_ "GenMsgSendType" BO_ 328 0;
BA_ "GenMsgCycleTime" BO_ 1861 100;
BA_ "GenMsgSendType" BO_ 1861 0;
BA_ "GenMsgCycleTime" BO_ 1869 1000;
BA_ "GenMsgSendType" BO_ 1869 0;
BA_ "GenMsgCycleTime" BO_ 694 100;
BA_ "GenMsgSendType" BO_ 694 0;
BA_ "GenMsgCycleTime" BO_ 2007 100;
BA_ "GenMsgSendType" BO_ 2007 0;
BA_ "GenMsgCycleTime" BO_ 1866 1000;
BA_ "GenMsgSendType" BO_ 1866 0;
BA_ "GenMsgCycleTime" BO_ 1623 1000;
BA_ "GenMsgSendType" BO_ 1623 0;
BA_ "GenMsgCycleTime" BO_ 646 100;
BA_ "GenMsgSendType" BO_ 646 0;
BA_ "GenMsgCycleTime" BO_ 1270 100;
BA_ "GenMsgSendType" BO_ 1270 0;
BA_ "GenMsgCycleTime" BO_ 822 1000;
BA_ "GenMsgSendType" BO_ 822 0;
BA_ "GenMsgCycleTime" BO_ 950 1000;
BA_ "GenMsgSendType" BO_ 950 0;
BA_ "GenMsgCycleTime" BO_ 599 20;
BA_ "GenMsgSendType" BO_ 599 0;
BA_ "GenMsgCycleTime" BO_ 2006 100;
BA_ "GenMsgSendType" BO_ 2006 0;
BA_ "GenMsgCycleTime" BO_ 597 100;
BA_ "GenMsgSendType" BO_ 597 0;
BA_ "GenMsgCycleTime" BO_ 296 100;
BA_ "GenMsgSendType" BO_ 296 0;
BA_ "Confidence" SG_ 1319 DI_alertID 1;
BA_ "Confidence" SG_ 1319 DI_alertState 1;
BA_ "Confidence" SG_ 1319 DI_a004_unavailableReason 1;
BA_ "GenSigSNA" SG_ 1319 DI_a004_unavailableReason "0";
BA_ "Confidence" SG_ 1319 DI_a007_button 1;
BA_ "Confidence" SG_ 1319 DI_a007_buttonStuckTime 1;
BA_ "Confidence" SG_ 1319 DI_a012_accel1SupplyV 1;
BA_ "Confidence" SG_ 1319 DI_a012_accel2SupplyV 1;
BA_ "Confidence" SG_ 1319 DI_a013_errorType 1;
BA_ "Confidence" SG_ 1319 DI_a015_reason 1;
BA_ "Confidence" SG_ 1319 DI_a020_difHvilStatus 1;
BA_ "GenSigSNA" SG_ 1319 DI_a020_difHvilStatus "3";
BA_ "Confidence" SG_ 1319 DI_a020_dirHvilStatus 1;
BA_ "GenSigSNA" SG_ 1319 DI_a020_dirHvilStatus "3";
BA_ "Confidence" SG_ 1319 DI_a020_vehiclePowerState 1;
BA_ "Confidence" SG_ 1319 DI_a020_hvilSystemStatus 1;
BA_ "GenSigSNA" SG_ 1319 DI_a020_hvilSystemStatus "3";
BA_ "Confidence" SG_ 1319 DI_a021_packVoltage 1;
BA_ "Confidence" SG_ 1319 DI_a021_maxBusVoltage 1;
BA_ "Confidence" SG_ 1319 DI_a024_pedalPos 1;
BA_ "Confidence" SG_ 1319 DI_a024_currentGear 1;
BA_ "GenSigSNA" SG_ 1319 DI_a024_currentGear "7";
BA_ "Confidence" SG_ 1319 DI_a025_backfillState 1;
BA_ "Confidence" SG_ 1319 DI_a025_bfillUnavailableReason 1;
BA_ "Confidence" SG_ 1319 DI_a051_dcCableCurrentEst 1;
BA_ "Confidence" SG_ 1319 DI_a051_packCurrent 1;
BA_ "Confidence" SG_ 1319 DI_a053_canID 1;
BA_ "Confidence" SG_ 1319 DI_a053_errorType 1;
BA_ "Confidence" SG_ 1319 DI_a056_canID 1;
BA_ "Confidence" SG_ 1319 DI_a056_errorType 1;
BA_ "Confidence" SG_ 1319 DI_a059_canID 1;
BA_ "Confidence" SG_ 1319 DI_a059_errorType 1;
BA_ "Confidence" SG_ 1319 DI_a062_limpReason 1;
BA_ "Confidence" SG_ 1319 DI_a063_gpoReason 1;
BA_ "Confidence" SG_ 1319 DI_a064_hvState 1;
BA_ "Confidence" SG_ 1319 DI_a064_vehiclePowerState 1;
BA_ "Confidence" SG_ 1319 DI_a064_vehicleSpeed 1;
BA_ "Confidence" SG_ 1319 DI_a066_canID 1;
BA_ "Confidence" SG_ 1319 DI_a066_errorType 1;
BA_ "Confidence" SG_ 1319 DI_a076_lvSupplyV 1;
BA_ "Confidence" SG_ 1319 DI_a077_lvSupplyV 1;
BA_ "Confidence" SG_ 1319 DI_a090_reason 1;
BA_ "Confidence" SG_ 1319 DI_a094_canID 1;
BA_ "Confidence" SG_ 1319 DI_a094_errorType 1;
BA_ "Confidence" SG_ 1319 DI_a097_errorType 1;
BA_ "Confidence" SG_ 1319 DI_a098_errorCode 1;
BA_ "Confidence" SG_ 1319 DI_a104_proxIrrationalReason 1;
BA_ "Confidence" SG_ 1319 DI_a120_blendingState 1;
BA_ "Confidence" SG_ 1319 DI_a120_blendingUnavailableReaso 1;
BA_ "SystemSignalLongSymbol" SG_ 1319 DI_a120_blendingUnavailableReaso "DI_a120_blendingUnavailableReason";
BA_ "Confidence" SG_ 1319 DI_a124_undrivenWheelMPH 1;
BA_ "Confidence" SG_ 1319 DI_a124_cruiseFaultReason 1;
BA_ "GenSigSNA" SG_ 1319 DI_a124_cruiseFaultReason "17";
BA_ "Confidence" SG_ 1319 DI_a125_maxDischargeCurrent 1;
BA_ "Confidence" SG_ 1319 DI_a125_maxChargeCurrent 1;
BA_ "Confidence" SG_ 1319 DI_a125_minBusVoltage 1;
BA_ "Confidence" SG_ 1319 DI_a130_aebFaultReason 1;
BA_ "GenSigSNA" SG_ 1319 DI_a130_aebFaultReason "6";
BA_ "Confidence" SG_ 1319 DI_a130_aebSmState 1;
BA_ "Confidence" SG_ 1319 DI_a130_dasAebEvent 1;
BA_ "GenSigSNA" SG_ 1319 DI_a130_dasAebEvent "3";
BA_ "Confidence" SG_ 1319 DI_a130_aebBrakeTorqueCommand 1;
BA_ "Confidence" SG_ 1319 DI_a131_warnSpeedLimit 1;
BA_ "Confidence" SG_ 1319 DI_a133_vhldGrade 1;
BA_ "Confidence" SG_ 1319 DI_a134_wheelSpeedDiffFrL 1;
BA_ "Confidence" SG_ 1319 DI_a134_wheelSpeedDiffFrR 1;
BA_ "Confidence" SG_ 1319 DI_a134_wheelSpeedDiffReL 1;
BA_ "Confidence" SG_ 1319 DI_a134_wheelSpeedDiffReR 1;
BA_ "Confidence" SG_ 1319 DI_a135_vhldFaultReason 1;
BA_ "Confidence" SG_ 1319 DI_a135_vhldBrakeTorqueCommand 1;
BA_ "Confidence" SG_ 1319 DI_a135_vhldTotalBrakeTorque 1;
BA_ "Confidence" SG_ 1319 DI_a135_vhldPropulsiveTorque 1;
BA_ "Confidence" SG_ 1319 DI_a135_vhldGrade 1;
BA_ "SystemSignalLongSymbol" SG_ 1319 DI_a141_DAS_longControlTuningPar "DI_a141_DAS_longControlTuningParameters";
BA_ "Confidence" SG_ 1319 DI_a146_panicReason 1;
BA_ "Confidence" SG_ 1319 DI_a160_kTire 1;
BA_ "Confidence" SG_ 1319 DI_a160_tireFitment 1;
BA_ "GenSigSNA" SG_ 1319 DI_a160_tireFitment "3";
BA_ "Confidence" SG_ 1319 DI_a160_wearFactorFrL 1;
BA_ "Confidence" SG_ 1319 DI_a160_wearFactorFrR 1;
BA_ "Confidence" SG_ 1319 DI_a160_wearFactorReL 1;
BA_ "Confidence" SG_ 1319 DI_a160_distanceSinceLastTireCon 1;
BA_ "GenSigSNA" SG_ 1319 DI_a160_distanceSinceLastTireCon "4095";
BA_ "SystemSignalLongSymbol" SG_ 1319 DI_a160_distanceSinceLastTireCon "DI_a160_distanceSinceLastTireConfig";
BA_ "Confidence" SG_ 1319 DI_a162_shiftDeniedReason 1;
BA_ "Confidence" SG_ 1319 DI_a162_motorSpeed 1;
BA_ "Confidence" SG_ 1319 DI_a162_pedalPos 1;
BA_ "Confidence" SG_ 1319 DI_a162_currentGear 1;
BA_ "GenSigSNA" SG_ 1319 DI_a162_currentGear "7";
BA_ "Confidence" SG_ 1319 DI_a162_requestedGear 1;
BA_ "GenSigSNA" SG_ 1319 DI_a162_requestedGear "7";
BA_ "Confidence" SG_ 1319 DI_a162_requestSource 1;
BA_ "Confidence" SG_ 1319 DI_a162_timeSinceCruiseCancel 1;
BA_ "Confidence" SG_ 1319 DI_a162_sysStateExitCondition 1;
BA_ "Confidence" SG_ 1319 DI_a163_motorSpeed 1;
BA_ "Confidence" SG_ 1319 DI_a163_currentGear 1;
BA_ "GenSigSNA" SG_ 1319 DI_a163_currentGear "7";
BA_ "Confidence" SG_ 1319 DI_a163_requestedGear 1;
BA_ "GenSigSNA" SG_ 1319 DI_a163_requestedGear "7";
BA_ "Confidence" SG_ 1319 DI_a163_requestSource 1;
BA_ "Confidence" SG_ 1319 DI_a164_motorSpeed 1;
BA_ "Confidence" SG_ 1319 DI_a164_pedalPos 1;
BA_ "Confidence" SG_ 1319 DI_a164_torqueDriver 1;
BA_ "Confidence" SG_ 1319 DI_a165_crsCancelReason 1;
BA_ "Confidence" SG_ 1319 DI_a170_tireSeasonSelected 1;
BA_ "Confidence" SG_ 1319 DI_a170_kTire 1;
BA_ "Confidence" SG_ 1319 DI_a170_tireFitment 1;
BA_ "GenSigSNA" SG_ 1319 DI_a170_tireFitment "3";
BA_ "Confidence" SG_ 1319 DI_a170_wearFactorFrL 1;
BA_ "Confidence" SG_ 1319 DI_a170_wearFactorFrR 1;
BA_ "Confidence" SG_ 1319 DI_a170_wearFactorReL 1;
BA_ "Confidence" SG_ 1319 DI_a170_odometer 1;
BA_ "GenSigSNA" SG_ 1319 DI_a170_odometer "4095";
BA_ "Confidence" SG_ 1319 DI_a170_distanceSinceLastTireCon 1;
BA_ "GenSigSNA" SG_ 1319 DI_a170_distanceSinceLastTireCon "63";
BA_ "SystemSignalLongSymbol" SG_ 1319 DI_a170_distanceSinceLastTireCon "DI_a170_distanceSinceLastTireConfig";
BA_ "Confidence" SG_ 1319 DI_a172_motorSpeed 1;
BA_ "Confidence" SG_ 1319 DI_a172_pedalPos 1;
BA_ "Confidence" SG_ 1319 DI_a172_currentGear 1;
BA_ "GenSigSNA" SG_ 1319 DI_a172_currentGear "7";
BA_ "Confidence" SG_ 1319 DI_a172_timeSinceCruiseCancel 1;
BA_ "Confidence" SG_ 1319 DI_a173_brakeApply 1;
BA_ "Confidence" SG_ 1319 DI_a173_pedalPos 1;
BA_ "Confidence" SG_ 1319 DI_a175_crsNotAvailableReason 1;
BA_ "GenSigSNA" SG_ 1319 DI_a175_crsNotAvailableReason "20";
BA_ "Confidence" SG_ 1319 DI_a177_newFitment 1;
BA_ "GenSigSNA" SG_ 1319 DI_a177_newFitment "3";
BA_ "Confidence" SG_ 1319 DI_a178_offsetValue 1;
BA_ "Confidence" SG_ 1319 DI_a180_crsNotAvailableReason 1;
BA_ "GenSigSNA" SG_ 1319 DI_a180_crsNotAvailableReason "20";
BA_ "Confidence" SG_ 1319 DI_a184_apcCancelReason 1;
BA_ "Confidence" SG_ 1319 DI_a184_apcUnavailableReason 1;
BA_ "Confidence" SG_ 1319 DI_a184_autoparkInternalState 1;
BA_ "Confidence" SG_ 1319 DI_a185_apcCancelReason 1;
BA_ "Confidence" SG_ 1319 DI_a185_apcUnavailableReason 1;
BA_ "Confidence" SG_ 1319 DI_a185_crsNotAvailableReason 1;
BA_ "GenSigSNA" SG_ 1319 DI_a185_crsNotAvailableReason "20";
BA_ "Confidence" SG_ 1319 DI_a185_crsFaultReason 1;
BA_ "GenSigSNA" SG_ 1319 DI_a185_crsFaultReason "17";
BA_ "Confidence" SG_ 1319 DI_a185_autoparkInternalState 1;
BA_ "Confidence" SG_ 1319 DI_a187_filteredAccel 1;
BA_ "Confidence" SG_ 1319 DI_a187_rawPedal 1;
BA_ "Confidence" SG_ 1319 DI_a187_systemTorqueCommand 1;
BA_ "Confidence" SG_ 1319 DI_a189_accelPedal 1;
BA_ "Confidence" SG_ 1319 DI_a189_grade 1;
BA_ "Confidence" SG_ 1319 DI_a189_systemTorque 1;
BA_ "Confidence" SG_ 1319 DI_a189_motorSpeed 1;
BA_ "Confidence" SG_ 1319 DI_a190_relativeTireTreadDepth 1;
BA_ "Confidence" SG_ 1319 DI_a190_treadWearFactorFrL 1;
BA_ "Confidence" SG_ 1319 DI_a190_treadWearFactorFrR 1;
BA_ "Confidence" SG_ 1319 DI_a190_treadWearFactorReL 1;
BA_ "Confidence" SG_ 1319 DI_a190_treadWearFactorAvgConfid 1;
BA_ "SystemSignalLongSymbol" SG_ 1319 DI_a190_treadWearFactorAvgConfid "DI_a190_treadWearFactorAvgConfidence";
BA_ "Confidence" SG_ 1319 DI_a191_motorSpeed 1;
BA_ "Confidence" SG_ 1319 DI_a191_currentGear 1;
BA_ "GenSigSNA" SG_ 1319 DI_a191_currentGear "7";
BA_ "Confidence" SG_ 1319 DI_a191_requestedGear 1;
BA_ "GenSigSNA" SG_ 1319 DI_a191_requestedGear "7";
BA_ "Confidence" SG_ 1319 DI_a191_requestSource 1;
BA_ "Confidence" SG_ 1319 DI_a191_timeSinceCruiseCancel 1;
BA_ "Confidence" SG_ 1319 DI_a193_brakeTorqueFrL 1;
BA_ "Confidence" SG_ 1319 DI_a193_brakeTorqueFrLLastVal 1;
BA_ "Confidence" SG_ 1319 DI_a193_brakeTorqueFrLCurrVal 1;
BA_ "Confidence" SG_ 1319 DI_a193_brakeTorqueFrR 1;
BA_ "Confidence" SG_ 1319 DI_a193_brakeTorqueFrRLastVal 1;
BA_ "Confidence" SG_ 1319 DI_a193_brakeTorqueFrRCurrVal 1;
BA_ "Confidence" SG_ 1319 DI_a194_brakeTorqueReL 1;
BA_ "Confidence" SG_ 1319 DI_a194_brakeTorqueReLLastVal 1;
BA_ "Confidence" SG_ 1319 DI_a194_brakeTorqueReLCurrVal 1;
BA_ "Confidence" SG_ 1319 DI_a194_brakeTorqueReR 1;
BA_ "Confidence" SG_ 1319 DI_a194_brakeTorqueReRLastVal 1;
BA_ "Confidence" SG_ 1319 DI_a194_brakeTorqueReRCurrVal 1;
BA_ "Confidence" SG_ 1319 DI_a199_muVehicleLearnDown 1;
BA_ "Confidence" SG_ 1319 DI_a199_muVehicleDecFilt 1;
BA_ "Confidence" SG_ 1319 DI_a199_bankAngle 1;
BA_ "Confidence" SG_ 1319 DI_a199_lateralAccelFilt 1;
BA_ "Confidence" SG_ 1319 DI_a199_driverIntendedYawRate 1;
BA_ "Confidence" SG_ 1319 DI_a199_vehicleVelocity 1;
BA_ "Confidence" SG_ 1319 DI_a199_sensorYawRate 1;
BA_ "Confidence" SG_ 1319 DI_a199_preControlActive 1;
BA_ "Confidence" SG_ 1319 DI_a199_oversteerdMzActive 1;
BA_ "Confidence" SG_ 1319 DI_a199_decelControlActive 1;
BA_ "Confidence" SG_ 1319 DI_a199_understeerdMzActive 1;
BA_ "Confidence" SG_ 1319 DI_a199_vdcMode 1;
BA_ "Confidence" SG_ 1319 DI_a200_MBPCheckStatus 1;
BA_ "Confidence" SG_ 1319 DI_a200_MBPFailedCase 1;
BA_ "Confidence" SG_ 1319 DI_a200_MBPFaultProbability 1;
BA_ "Confidence" SG_ 1319 DI_a202_reason 1;
BA_ "Confidence" SG_ 1319 DI_a202_movement 1;
BA_ "Confidence" SG_ 1319 DI_a202_sysStateExitCondition 1;
BA_ "Confidence" SG_ 1319 DI_a203_ptcStateLocal 1;
BA_ "GenSigSNA" SG_ 1319 DI_a203_ptcStateLocal "6";
BA_ "Confidence" SG_ 1319 DI_a203_btcState 1;
BA_ "Confidence" SG_ 1319 DI_a204_longAccel 1;
BA_ "Confidence" SG_ 1319 DI_a204_longAccelLastVal 1;
BA_ "Confidence" SG_ 1319 DI_a204_longAccelCurrVal 1;
BA_ "Confidence" SG_ 1319 DI_a204_rollRate 1;
BA_ "Confidence" SG_ 1319 DI_a204_rollRateLastVal 1;
BA_ "Confidence" SG_ 1319 DI_a204_rollRateCurrVal 1;
BA_ "Confidence" SG_ 1319 DI_a205_latAccel 1;
BA_ "Confidence" SG_ 1319 DI_a205_latAccelLastVal 1;
BA_ "Confidence" SG_ 1319 DI_a205_latAccelCurrVal 1;
BA_ "Confidence" SG_ 1319 DI_a205_pitchRate 1;
BA_ "Confidence" SG_ 1319 DI_a205_pitchRateLastVal 1;
BA_ "Confidence" SG_ 1319 DI_a205_pitchRateCurrVal 1;
BA_ "Confidence" SG_ 1319 DI_a206_verticalAccel 1;
BA_ "Confidence" SG_ 1319 DI_a206_verticalAccelLastVal 1;
BA_ "Confidence" SG_ 1319 DI_a206_verticalAccelCurrVal 1;
BA_ "Confidence" SG_ 1319 DI_a206_yawRate 1;
BA_ "Confidence" SG_ 1319 DI_a206_yawRateLastVal 1;
BA_ "Confidence" SG_ 1319 DI_a206_yawRateCurrVal 1;
BA_ "Confidence" SG_ 1319 DI_a210_ptcStateGlobal 1;
BA_ "GenSigSNA" SG_ 1319 DI_a210_ptcStateGlobal "3";
BA_ "Confidence" SG_ 1319 DI_a210_espActuatorState 1;
BA_ "SystemSignalLongSymbol" SG_ 1319 DI_a210_secondaryBrakeActuatorIs "DI_a210_secondaryBrakeActuatorIsMaster";
BA_ "Confidence" SG_ 1319 DI_a223_ptcStateLocal 1;
BA_ "GenSigSNA" SG_ 1319 DI_a223_ptcStateLocal "6";
BA_ "Confidence" SG_ 1319 DI_a223_btcState 1;
BA_ "Confidence" SG_ 1319 DI_a223_velocityEstimatorState 1;
BA_ "Confidence" SG_ 1319 DI_a223_addState_dir 1;
BA_ "Confidence" SG_ 1319 DI_a223_addState_dif 1;
BA_ "Confidence" SG_ 1319 DI_a223_DI_tractionControlMode 1;
BA_ "Confidence" SG_ 1319 DI_a223_UI_tractionControlMode 1;
BA_ "Confidence" SG_ 1319 DI_a223_vehicleVelocity 1;
BA_ "Confidence" SG_ 1319 DI_a223_musurf 1;
BA_ "Confidence" SG_ 1319 DI_a223_musurfHigh 1;
BA_ "Confidence" SG_ 1319 DI_a223_driveTCActive 1;
BA_ "Confidence" SG_ 1319 DI_a223_regenTCActive 1;
BA_ "Confidence" SG_ 1319 DI_a223_surfaceUtility 1;
BA_ "Confidence" SG_ 1319 DI_a224_brakeFLTemp 1;
BA_ "Confidence" SG_ 1319 DI_a224_brakeFRTemp 1;
BA_ "Confidence" SG_ 1319 DI_a224_brakeRLTemp 1;
BA_ "Confidence" SG_ 1319 DI_a224_brakeRRTemp 1;
BA_ "Confidence" SG_ 1319 DI_a226_systState 1;
BA_ "Confidence" SG_ 1319 DI_a227_hvState 1;
BA_ "Confidence" SG_ 1319 DI_a227_vehiclePowerState 1;
BA_ "Confidence" SG_ 1319 DI_a232_velocityEstimatorState 1;
BA_ "Confidence" SG_ 1319 DI_a232_UI_tractionControlMode 1;
BA_ "Confidence" SG_ 1319 DI_a232_vehicleVelocity 1;
BA_ "Confidence" SG_ 1319 DI_a232_musurf 1;
BA_ "Confidence" SG_ 1319 DI_a232_musurfHigh 1;
BA_ "Confidence" SG_ 1319 DI_a232_allWhlSpeedRotationAvail 1;
BA_ "Confidence" SG_ 1319 DI_a232_BrakeMasterCylPressValid 1;
BA_ "Confidence" SG_ 1319 DI_a232_WheelBrakeTorquesValid 1;
BA_ "Confidence" SG_ 1319 DI_a232_AbsBrakeEventActiveValid 1;
BA_ "Confidence" SG_ 1319 DI_a232_UndersteerActiveValid 1;
BA_ "Confidence" SG_ 1319 DI_a232_OversteerActiveValid 1;
BA_ "Confidence" SG_ 1319 DI_a232_allMotorTorquesValid 1;
BA_ "Confidence" SG_ 1319 DI_a232_lateralAccelValid 1;
BA_ "Confidence" SG_ 1319 DI_a232_longitudinalAccelValid 1;
BA_ "Confidence" SG_ 1319 DI_a232_yawRateValid 1;
BA_ "Confidence" SG_ 1319 DI_a232_steerAngleValid 1;
BA_ "Confidence" SG_ 1319 DI_a245_ebrStatus 1;
BA_ "Confidence" SG_ 1319 DI_a245_vehicleHoldState 1;
BA_ "Confidence" SG_ 1319 DI_a246_onePedalDrivingState 1;
BA_ "Confidence" SG_ 1319 DI_a246_opdUnavailableReason 1;
BA_ "SystemSignalLongSymbol" SG_ 871 DI_a026_parkPressedWithHighAPeda "DI_a026_parkPressedWithHighAPedal";
BA_ "SystemSignalLongSymbol" SG_ 871 DI_a036_sysStandbyUnitLimitedWai "DI_a036_sysStandbyUnitLimitedWait";
BA_ "SystemSignalLongSymbol" SG_ 871 DI_a039_exceptionUndefinedInstru "DI_a039_exceptionUndefinedInstruction";
BA_ "SystemSignalLongSymbol" SG_ 871 DI_a049_P0632_DI_ECU_OdometerNot "DI_a049_P0632_DI_ECU_OdometerNotProgrammed";
BA_ "SystemSignalLongSymbol" SG_ 872 DI_a068_secondaryWheelSpeedIrrat "DI_a068_secondaryWheelSpeedIrrational";
BA_ "SystemSignalLongSymbol" SG_ 872 DI_a118_diImmobilizedForFactoryF "DI_a118_diImmobilizedForFactoryFailsafe";
BA_ "SystemSignalLongSymbol" SG_ 872 DI_a119_latentFaultCheckFailedOn "DI_a119_latentFaultCheckFailedOnce";
BA_ "SystemSignalLongSymbol" SG_ 872 DI_a121_qualifiedBrakeEventMitig "DI_a121_qualifiedBrakeEventMitigation";
BA_ "SystemSignalLongSymbol" SG_ 875 DI_a179_steeringAngleOffsetWarni "DI_a179_steeringAngleOffsetWarning";
BA_ "SystemSignalLongSymbol" SG_ 875 DI_a188_tireRotationRecommendedG "DI_a188_tireRotationRecommendedGhosted";
BA_ "SystemSignalLongSymbol" SG_ 878 DI_a200_vdcModelBasedPlausibilit "DI_a200_vdcModelBasedPlausibility";
BA_ "SystemSignalLongSymbol" SG_ 878 DI_a232_velocityEstimatorDegrade "DI_a232_velocityEstimatorDegraded";
BA_ "SystemSignalLongSymbol" SG_ 878 DI_a238_secondaryCollisionMitiga "DI_a238_secondaryCollisionMitigationActive";
BA_ "SystemSignalLongSymbol" SG_ 878 DI_a248_vdcPreControlHighDynamic "DI_a248_vdcPreControlHighDynamicActive";
BA_ "SystemSignalLongSymbol" SG_ 878 DI_a249_spinDownLearningInProgre "DI_a249_spinDownLearningInProgress";
BA_ "Confidence" SG_ 328 DI_imuOffsetLearnRequest 1;
BA_ "Confidence" SG_ 328 DI_brakeCommandType 1;
BA_ "Confidence" SG_ 328 DI_brakeTorqueRequestActive 1;
BA_ "Confidence" SG_ 328 DI_brakeTorqueCommand 1;
BA_ "Confidence" SG_ 328 DI_ptcStateGlobal 1;
BA_ "GenSigSNA" SG_ 328 DI_ptcStateGlobal "3";
BA_ "Confidence" SG_ 328 DI_ptcActive 1;
BA_ "Confidence" SG_ 328 DI_vdcState 1;
BA_ "Confidence" SG_ 328 DI_isAnyVdcControlActive 1;
BA_ "Confidence" SG_ 328 DI_vdcMode 1;
BA_ "Confidence" SG_ 328 DI_pedalAssistCurveSelect 1;
BA_ "Confidence" SG_ 328 DI_isAnyTcActive 1;
BA_ "Confidence" SG_ 328 DI_VehicleMuConfidence 1;
BA_ "Confidence" SG_ 328 DI_VehicleMu 1;
BA_ "Confidence" SG_ 328 DI_trailerSwayIndex 1;
BA_ "Confidence" SG_ 328 DI_vdcControlActive 1;
BA_ "Confidence" SG_ 328 DI_treadDepthAlertSet 1;
BA_ "Confidence" SG_ 1861 DI_gradeAngle 1;
BA_ "Confidence" SG_ 1861 DI_bankAngle 1;
BA_ "Confidence" SG_ 1861 DI_chassisControlVideoRequest 1;
BA_ "Confidence" SG_ 1861 DI_tireUtilizationRatioFrL 1;
BA_ "Confidence" SG_ 1861 DI_tireUtilizationRatioFrR 1;
BA_ "Confidence" SG_ 1861 DI_tireUtilizationRatioReL 1;
BA_ "Confidence" SG_ 1861 DI_tireUtilizationRatioReR 1;
BA_ "Confidence" SG_ 1861 DI_counterSteerTarget 1;
BA_ "Confidence" SG_ 1861 DI_splitMuProbability 1;
BA_ "Confidence" SG_ 1861 DI_mzError 1;
BA_ "Confidence" SG_ 1861 DI_slipDifferenceFrontRear 1;
BA_ "Confidence" SG_ 1861 DI_highFreqYawRate 1;
BA_ "Confidence" SG_ 1861 DI_turnDirection 1;
BA_ "Confidence" SG_ 1861 DI_absolutePreControlRequest 1;
BA_ "Confidence" SG_ 1861 DI_oppositeBuildDirFrontAxle 1;
BA_ "Confidence" SG_ 1861 DI_oppositeBuildDirRearAxle 1;
BA_ "Confidence" SG_ 1861 DI_saturatedEffectiveness 1;
BA_ "Confidence" SG_ 1861 DI_driverPanicIndex 1;
BA_ "Confidence" SG_ 1861 DI_learnDownMu 1;
BA_ "Confidence" SG_ 1861 DI_preControlOpposingTurnDir 1;
BA_ "Confidence" SG_ 1861 DI_driverFxError 1;
BA_ "Confidence" SG_ 1861 DI_targetSaturation 1;
BA_ "Confidence" SG_ 1869 DI_tireWearFactor_FrL 1;
BA_ "Confidence" SG_ 1869 DI_tireWearFactor_FrR 1;
BA_ "Confidence" SG_ 1869 DI_tireWearFactor_ReL 1;
BA_ "Confidence" SG_ 1869 DI_tireWearFactor_ReR 1;
BA_ "Confidence" SG_ 1869 DI_kTireEstReUnSat 1;
BA_ "GenSigSNA" SG_ 1869 DI_kTireEstReUnSat "127";
BA_ "Confidence" SG_ 1869 DI_distanceSinceLastTireConfig 1;
BA_ "GenSigSNA" SG_ 1869 DI_distanceSinceLastTireConfig "63";
BA_ "Confidence" SG_ 1869 DI_hydroplaningRisk 1;
BA_ "Confidence" SG_ 1869 DI_hydroplaningPuddlesWet 1;
BA_ "Confidence" SG_ 1869 DI_hydroplaningPuddlesDry 1;
BA_ "Confidence" SG_ 1869 DI_kTireEstRe 1;
BA_ "GenSigSNA" SG_ 1869 DI_kTireEstRe "31";
BA_ "Confidence" SG_ 1869 DI_stickyMu 1;
BA_ "Confidence" SG_ 1869 DI_stickyMuConfidence 1;
BA_ "Confidence" SG_ 694 DI_vdcTelltaleFlash 1;
BA_ "Confidence" SG_ 694 DI_vdcTelltaleOn 1;
BA_ "Confidence" SG_ 694 DI_tcTelltaleFlash 1;
BA_ "Confidence" SG_ 694 DI_tcTelltaleOn 1;
BA_ "Confidence" SG_ 694 DI_tractionControlModeUI 1;
BA_ "Confidence" SG_ 694 DI_ptcStateGlobalUI 1;
BA_ "GenSigSNA" SG_ 694 DI_ptcStateGlobalUI "3";
BA_ "Confidence" SG_ 694 DI_btcStateUI 1;
BA_ "Confidence" SG_ 694 DI_vehicleHoldTelltaleOn 1;
BA_ "SystemSignalLongSymbol" SG_ 694 DI_opdFeedbackResetPositiveSpeed "DI_opdFeedbackResetPositiveSpeeds";
BA_ "Confidence" SG_ 694 DI_slipperySurfaceOnUI 1;
BA_ "Confidence" SG_ 694 DI_yellowBrakeTelltaleOn 1;
BA_ "Confidence" SG_ 694 DI_greenABSTelltaleOn 1;
BA_ "Confidence" SG_ 2007 DI_debugSelector 1;
BA_ "Confidence" SG_ 2007 DI_regenBackfillCmd 1;
BA_ "Confidence" SG_ 2007 DI_regenBackfillUnavailableReaso 1;
BA_ "SystemSignalLongSymbol" SG_ 2007 DI_regenBackfillUnavailableReaso "DI_regenBackfillUnavailableReason";
BA_ "Confidence" SG_ 2007 DI_regenBackfillAbsSatState 1;
BA_ "Confidence" SG_ 2007 DI_sysHeatPowerOptimal 1;
BA_ "Confidence" SG_ 2007 DI_sysPostPedalMinTorque 1;
BA_ "Confidence" SG_ 2007 DI_sysPostPedalMaxTorque 1;
BA_ "Confidence" SG_ 2007 DI_systemTorqueCommand 1;
BA_ "Confidence" SG_ 1866 DI_brakeFLTemp 1;
BA_ "GenSigSNA" SG_ 1866 DI_brakeFLTemp "1023";
BA_ "Confidence" SG_ 1866 DI_brakeFRTemp 1;
BA_ "GenSigSNA" SG_ 1866 DI_brakeFRTemp "1023";
BA_ "Confidence" SG_ 1866 DI_brakeRLTemp 1;
BA_ "GenSigSNA" SG_ 1866 DI_brakeRLTemp "1023";
BA_ "Confidence" SG_ 1866 DI_brakeRRTemp 1;
BA_ "GenSigSNA" SG_ 1866 DI_brakeRRTemp "1023";
BA_ "Confidence" SG_ 1623 DI_infoIndex 1;
BA_ "Confidence" SG_ 1623 DI_buildType 1;
BA_ "Confidence" SG_ 1623 DI_hardwareId 1;
BA_ "Confidence" SG_ 646 DI_cruiseState 1;
BA_ "Confidence" SG_ 646 DI_cruiseSetSpeed 1;
BA_ "Confidence" SG_ 646 DI_cruiseSetSpeedUnits 1;
BA_ "Confidence" SG_ 646 DI_autoparkState 1;
BA_ "GenSigSNA" SG_ 646 DI_autoparkState "15";
BA_ "Confidence" SG_ 646 DI_parkBrakeState 1;
BA_ "GenSigSNA" SG_ 646 DI_parkBrakeState "15";
BA_ "Confidence" SG_ 646 DI_aebState 1;
BA_ "GenSigSNA" SG_ 646 DI_aebState "7";
BA_ "Confidence" SG_ 646 DI_loncDeactivationReason 1;
BA_ "Confidence" SG_ 646 DI_vehicleHoldState 1;
BA_ "Confidence" SG_ 646 DI_onePedalDrivingState 1;
BA_ "Confidence" SG_ 646 DI_brakeStandActive 1;
BA_ "Confidence" SG_ 646 DI_regenBackfillState 1;
BA_ "Confidence" SG_ 646 DI_cruiseNotAvailableReason 1;
BA_ "GenSigSNA" SG_ 646 DI_cruiseNotAvailableReason "20";
BA_ "Confidence" SG_ 646 DI_cruiseFaultReason 1;
BA_ "GenSigSNA" SG_ 646 DI_cruiseFaultReason "17";
BA_ "Confidence" SG_ 646 DI_cruiseCancelReason 1;
BA_ "Confidence" SG_ 1270 DI_doublePedalState 1;
BA_ "Confidence" SG_ 1270 DI_autopilotRequest 1;
BA_ "Confidence" SG_ 1270 DI_rollPreventionState 1;
BA_ "SystemSignalLongSymbol" SG_ 1270 DI_temporaryOpdActiveAfterLoncCa "DI_temporaryOpdActiveAfterLoncCancel";
BA_ "Confidence" SG_ 1270 DI_regenBlendingState 1;
BA_ "Confidence" SG_ 1270 DI_brakeCpScale 1;
BA_ "Confidence" SG_ 1270 DI_rollbackDistance 1;
BA_ "Confidence" SG_ 1270 DI_lowMuProbabilityConfidence 1;
BA_ "Confidence" SG_ 1270 DI_pedalAssistCurveSelectForSX 1;
BA_ "Confidence" SG_ 1270 DI_longitudinalControlStack 1;
BA_ "GenSigSNA" SG_ 1270 DI_longitudinalControlStack "0";
BA_ "Confidence" SG_ 822 DI_sysDrivePowerRated 1;
BA_ "GenSigSNA" SG_ 822 DI_sysDrivePowerRated "511";
BA_ "Confidence" SG_ 822 DI_obdDriveCycleStatus 1;
BA_ "Confidence" SG_ 822 DI_performancePackage 1;
BA_ "GenSigSNA" SG_ 822 DI_performancePackage "7";
BA_ "Confidence" SG_ 822 DI_sysRegenPowerRated 1;
BA_ "GenSigSNA" SG_ 822 DI_sysRegenPowerRated "255";
BA_ "Confidence" SG_ 950 DI_odometer 1;
BA_ "GenSigSNA" SG_ 950 DI_odometer "4294967295";
BA_ "Confidence" SG_ 599 DI_opdVehicleModelSpeedRef 1;
BA_ "Confidence" SG_ 599 DI_uiSpeed 1;
BA_ "GenSigSNA" SG_ 599 DI_uiSpeed "511";
BA_ "Confidence" SG_ 599 DI_uiSpeedUnits 1;
BA_ "Confidence" SG_ 599 DI_accelPedalPressed 1;
BA_ "Confidence" SG_ 599 DI_sideslipEstimate 1;
BA_ "Confidence" SG_ 599 DI_vehicleSpeed 1;
BA_ "GenSigSNA" SG_ 599 DI_vehicleSpeed "8191";
BA_ "Confidence" SG_ 599 DI_velocityEstimatorState 1;
BA_ "SystemSignalLongSymbol" SG_ 2006 DI_smartShiftBrakeReapplyRequire "DI_smartShiftBrakeReapplyRequired";
BA_ "Confidence" SG_ 597 DI_lastQualifiedGear 1;
BA_ "GenSigSNA" SG_ 597 DI_lastQualifiedGear "7";
BA_ "Confidence" SG_ 597 DI_lastDrivingGear 1;
BA_ "GenSigSNA" SG_ 597 DI_lastDrivingGear "7";
BA_ "Confidence" SG_ 597 DI_distDrivenInGear 1;
BA_ "Confidence" SG_ 597 DI_suggestedGearReason 1;
BA_ "Confidence" SG_ 597 DI_smartShiftGear 1;
BA_ "Confidence" SG_ 597 DI_smartShiftUnavailableReason 1;
BA_ "GenSigSNA" SG_ 597 DI_smartShiftUnavailableReason "0";
BA_ "Confidence" SG_ 296 DI_limitRegenPower 1;
BA_ "Confidence" SG_ 296 DI_limitIBat 1;
BA_ "Confidence" SG_ 296 DI_limitObstacleDetection 1;
BA_ "Confidence" SG_ 296 DI_limitDriveTorque 1;
BA_ "Confidence" SG_ 296 DI_limitRegenTorque 1;
BA_ "Confidence" SG_ 296 DI_vehicleSpeedLimitType 1;
BA_ "Confidence" SG_ 296 DI_vehicleSpeedLimit 1;
BA_ "GenSigSNA" SG_ 296 DI_vehicleSpeedLimit "511";
BA_ "Confidence" SG_ 296 DI_vehicleSpeedLimitReason 1;
BA_ "Confidence" SG_ 296 DI_proximity 1;
VAL_ 1319 DI_alertID 254 "a254_vehicleStuckDetected" 253 "a253_accelSynchWarn" 251 "a251_diPowerOnStateMismatch" 250 "a250_tasSpeedLimitActive" 249 "a249_spinDownLearningInProgress" 248 "a248_vdcPreControlHighDynamicActive" 246 "a246_opdUnavailable" 245 "a245_opdReducedWithoutEbr" 244 "a244_vseRLSMassMismatch" 243 "a243_rcuMIA" 242 "a242_vdcTrailerSwayDetected" 241 "a241_vdcMotorSpeed_dir" 240 "a240_torqueSplitStuck" 239 "a239_neutralRequestByPM" 238 "a238_secondaryCollisionMitigationActive" 237 "a237_undersideAbuse" 236 "a236_tasMIA" 235 "a235_trackModeActive" 233 "a233_frontWheelImpactDetected" 232 "a232_velocityEstimatorDegraded" 231 "a231_unintendedReset2" 230 "a230_cmpMIA" 228 "a228_brakeTempEstUnavailable" 227 "a227_contactorsNotClosed" 226 "a226_sysStartConditionNotMet" 225 "a225_vyEstimatorDegradedDebug" 224 "a224_brakeOverTemp" 223 "a223_tractionControlDisabled" 222 "a222_vdcDisabled" 221 "a221_vdcUndersteerdMzActive" 220 "a220_vdcUndersteerDecelActive" 219 "a219_vdcOversteerdMzActive" 218 "a218_vdcOSPreControlActive" 217 "a217_vdcOutputIrrational" 216 "a216_vdcMBPAlmostTripped" 215 "a215_vdcWheelSpeedRe" 214 "a214_vdcWheelSpeedFr" 213 "a213_lowMuProbabilityChange" 212 "a212_vdcWheelRotations" 211 "a211_vdcMotorSpeed_dif" 210 "a210_vdcOtherControllerStates" 208 "a208_vdcPowertrainTorque_dir" 207 "a207_vdcPowertrainTorque_dif" 206 "a206_vdcRcmVertical" 205 "a205_vdcRcmLateral" 204 "a204_vdcRcmLongitudinal" 203 "a203_TCReducedByADD" 202 "a202_excessHeatUnavailable" 201 "a201_decelTorqueLimited" 200 "a200_vdcModelBasedPlausibility" 199 "a199_vdcFaulted" 198 "a198_vdcEspMCPressAndSteering" 197 "a197_vdcEspWheelSaturations" 196 "a196_vdcEspSlipRe" 195 "a195_vdcEspSlipFr" 194 "a194_vdcBrakeTorqueRe" 193 "a193_vdcBrakeTorqueFr" 192 "a192_invalidOdometer" 191 "a191_brakeShiftReq" 190 "a190_tireRotationRecommended" 189 "a189_garageShiftWithPedal" 188 "a188_tireRotationRecommendedGhosted" 187 "a187_pedalMisapplication" 186 "a186_brakeStand" 185 "a185_autoparkAborted" 184 "a184_autoparkCanceled" 183 "a183_holdReleaseRqrd" 182 "a182_frontMotorMode" 181 "a181_rearMotorMode" 180 "a180_crsSeatbeltUnbuckled" 179 "a179_steeringAngleOffsetWarning" 178 "a178_steeringAngleOffsetFault" 177 "a177_tireFitmentChanged" 176 "a176_EBRreleased" 175 "a175_crsNotAvailable" 174 "a174_notOkToStartDrive" 173 "a173_bothPedalsPressed" 172 "a172_accelPressedInNP" 171 "a171_driveRailNotRequested" 170 "a170_tireConfigUpdated" 169 "a169_regenOffOverride" 168 "a168_proximityDriveDenial" 167 "a167_keyNotAuthenticated" 166 "a166_driverLeft" 165 "a165_cruiseCancelled" 164 "a164_brakeOverride" 163 "a163_shiftMotorSpeed" 162 "a162_shiftDenied" 161 "a161_epas3pMIA" 160 "a160_fastLearnComplete" 159 "a159_cruiseSelfCheck" 158 "a158_ibstMIA" 157 "a157_rcmMIA" 155 "a155_vcfrontMIA" 154 "a154_vdcRearSteering" 146 "a146_pbrkPanicEpbFault" 144 "a144_configMismatch" 143 "a143_mcuLimitActive" 142 "a142_potholeDetected" 141 "a141_dasMIA" 140 "a140_ptcMIA" 139 "a139_rearUnitDisabled" 138 "a138_frontUnitDisabled" 137 "a137_noCapableDriveUnits" 135 "a135_vehicleHoldFault" 134 "a134_wheelSpeedIrrational" 133 "a133_vehicleHoldTimedOut" 131 "a131_highSpeedWearLimit" 130 "a130_aebFault" 129 "a129_epbNotApplied" 125 "a125_noBatteryPower" 124 "a124_cruiseFault" 122 "a122_highStackUsage" 121 "a121_qualifiedBrakeEventMitigation" 120 "a120_regenBlendingUnavailable" 119 "a119_latentFaultCheckFailedOnce" 118 "a118_diImmobilizedForFactoryFailsafe" 117 "a117_latentFaultCheckTripped" 116 "a116_motorRecovered" 115 "a115_exceptionDataAbort2" 114 "a114_exceptionDataAbort" 112 "a112_accelTrack1Incons" 110 "a110_brakeMIA" 109 "a109_ahbWriteError" 108 "a108_appMIA" 105 "a105_cpMIA" 104 "a104_proximityIrrational" 103 "a103_bbMIA" 102 "a102_exceptionPrefetchAbort" 101 "a101_eccTestData1" 100 "a100_nvramError" 99 "a099_threadOverrun" 98 "a098_eepromManagerError" 97 "a097_eepromError" 96 "a096_memoryError" 95 "a095_canOverrunBusA" 94 "a094_canDataBusA" 93 "a093_canHardwareBusA" 92 "a092_bmsMIA" 91 "a091_espMIA" 90 "a090_pmMIA" 89 "a089_sccmMIA" 88 "a088_uiMIA" 87 "a087_gtwMIA" 86 "a086_dpbMIA" 85 "a085_proximityInEnable" 84 "a084_eccTestData0" 83 "a083_brakePedalSensor" 82 "a082_accelTrack2" 81 "a081_accelTrack1" 80 "a080_accelSynch" 79 "a079_adcRefHigh" 78 "a078_adcRefLow" 77 "a077_lvSupplyUV" 76 "a076_lvSupplyOV" 70 "a070_udsTransactionInitiated" 69 "a069_P1234_DI_ECU_DemoWindow" 68 "a068_secondaryWheelSpeedIrrational" 67 "a067_canOverrunBusB" 66 "a066_canDataBusB" 65 "a065_canHardwareBusB" 64 "a064_pmsrmUnitMiaWithHvDown" 63 "a063_systemGracefulPowerOff" 62 "a062_systemLimpMode" 61 "a061_canHardwareBusE" 60 "a060_canOverrunBusE" 59 "a059_canDataBusE" 58 "a058_canHardwareBusD" 57 "a057_canOverrunBusD" 56 "a056_canDataBusD" 55 "a055_canHardwareBusC" 54 "a054_canOverrunBusC" 53 "a053_canDataBusC" 52 "a052_dirMIA" 51 "a051_batteryOvercurrent" 50 "a050_P1234_DI_ECU_DemoTimer" 49 "a049_P0632_DI_ECU_OdometerNotProgrammed" 48 "a048_ecuLogAvailable" 43 "a043_pmrMIA" 42 "a042_pmfMIA" 41 "a041_driverBrakeApplyStuck" 40 "a040_difMIA" 39 "a039_exceptionUndefinedInstruction" 38 "a038_idleTaskStarving" 36 "a036_sysStandbyUnitLimitedWait" 31 "a031_closureAccelerationLimit" 26 "a026_parkPressedWithHighAPedal" 25 "a025_regenBackfillUnavailable" 24 "a024_holdNForNeutral" 23 "a023_carNotParked" 22 "a022_hw5vSupplyUV" 21 "a021_packOvervoltage" 20 "a020_systemHvilNotClosed" 19 "a019_hwAccelPedalPower" 18 "a018_hwLVSupplyUV" 17 "a017_hwPedalMonitor" 16 "a016_parkRequestByPM" 15 "a015_immobilizer" 14 "a014_secGearSelActivated" 13 "a013_eccError" 12 "a012_accel5VSupply" 10 "a010_unintendedReset" 7 "a007_secGearSelButtonStuck" 6 "a006_shifterUnavailable" 5 "a005_stalkPanicked" 4 "a004_smartShiftUnavailable" 3 "a003_suggestedGearOverride" 2 "a002_parkButtonDuringStalkReq" 1 "a001_frunkSpeedLimitActive" 0 "ALERT_DO_NOT_USE_ZERO" ;
VAL_ 1319 DI_alertState 1 "SET" 0 "CLEARED" ;
VAL_ 1319 DI_a004_unavailableReason 18 "UNAVAILABLE_DAS_MIA" 17 "UNAVAILABLE_DAS_NOT_CONFIDENT" 16 "UNAVAILABLE_DISPLAY_ERROR" 15 "UNAVAILABLE_VDC_UNAVAILABLE" 14 "UNAVAILABLE_VHLD_UNAVAILABLE" 13 "UNAVAILABLE_OPD_UNAVAILABLE" 12 "UNAVAILABLE_BLS_UNKNOWN" 11 "UNAVAILABLE_IBST_MIA" 10 "SILENT_UNAVAILABLE_AEB_ACTIVE" 9 "SILENT_UNAVAILABLE_CRUISE_REGULATING" 8 "SILENT_UNAVAILABLE_GTW_NOT_QUALIFIED" 7 "SILENT_UNAVAILABLE_SGS_ACTIVE" 6 "SILENT_UNAVAILABLE_CLOSURE_OPEN" 5 "SILENT_UNAVAILABLE_CHARGE_CABLE_CONNECTED" 4 "SILENT_UNAVAILABLE_DRIVER_BUCKLED_QF" 3 "SILENT_UNAVAILABLE_NON_STANDARD_MODE" 2 "SILENT_UNAVAILABLE_UI_DISABLE" 1 "UNAVAILABLE_NONE" 0 "UNAVAILABLE_SNA" ;
VAL_ 1319 DI_a007_button 3 "D" 2 "N" 1 "R" 0 "P" ;
VAL_ 1319 DI_a013_errorType 12 "RAM_CORRECTABLE_DMA" 11 "RAM_CORRECTABLE_CLA" 10 "RAM_CORRECTABLE_CPU" 9 "RAM_UNCORRECTABLE_DMA" 8 "RAM_UNCORRECTABLE_CLA" 7 "RAM_UNCORRECTABLE_CPU" 6 "FLASH_FAIL1_HIGH" 5 "FLASH_FAIL1_LOW" 4 "FLASH_FAIL0_HIGH" 3 "FLASH_FAIL0_LOW" 2 "FLASH_UNCORRECTABLE_HIGH" 1 "FLASH_UNCORRECTABLE_LOW" 0 "UNKNOWN" ;
VAL_ 1319 DI_a015_reason 1 "ARMED_AFTER_PREAUTH" 0 "AUTH_FAIL" ;
VAL_ 1319 DI_a020_difHvilStatus 3 "SNA" 2 "CLOSED" 1 "OPEN" 0 "DISABLED" ;
VAL_ 1319 DI_a020_dirHvilStatus 3 "SNA" 2 "CLOSED" 1 "OPEN" 0 "DISABLED" ;
VAL_ 1319 DI_a020_vehiclePowerState 3 "DRIVE" 2 "ACCESSORY" 1 "CONDITIONING" 0 "OFF" ;
VAL_ 1319 DI_a020_hvilSystemStatus 3 "SNA" 2 "CLOSED" 1 "OPEN" 0 "DISABLED" ;
VAL_ 1319 DI_a024_currentGear 7 "SNA" 4 "D" 3 "N" 2 "R" 1 "P" 0 "INVALID" ;
VAL_ 1319 DI_a025_backfillState 2 "ACTIVE" 1 "STANDBY" 0 "UNAVAILABLE" ;
VAL_ 1319 DI_a025_bfillUnavailableReason 18 "DI_LATENT_FAULT_TRIP" 17 "EBR_FULL_FAULT" 16 "PM_DISABLE_REQUEST_BPED" 15 "PM_DISABLE_REQUEST_BLEND" 14 "CARBON_CERAMIC_BRAKES" 13 "BRAKE_TEMP" 12 "EBR_FAULT" 11 "PM_DISABLE_REQUEST" 10 "TRACK_MODE_ACTIVE" 9 "VELOCITY_ESTIMATOR_UNAVAILABLE" 8 "TRACTION_CONTROL_UNAVAILABLE" 7 "ACTIVE_DAMPING_UNAVAILABLE" 6 "UI_COASTDOWN_MODE" 5 "SYSTEM_STATE" 4 "NON_DRIVE_GEAR" 3 "EBR_UNAVAILABLE" 2 "UI_DISABLE" 1 "GTW_DISABLE" 0 "NONE" ;
VAL_ 1319 DI_a053_canID 2047 "GTW_carConfig" 1926 "DBG_dynoVehicleSim" 1911 "XCP_diRequest" 1863 "DBG_vdcControl" 1656 "GTW_gearControl" 1589 "UDS_diRequest" 1349 "VCFRONT_systemStatus" 1320 "GTW_time" 1280 "UI_debugECU" 1106 "BMS_voltageRegGain" 1021 "UI_autopilotControl" 1005 "GTW_updateStatus" 985 "VCSEC_authenticityResponse" 962 "VCLEFT_switchStatus" 947 "UI_vehicleControl2" 944 "DPB_actuator3" 943 "BB_status" 929 "VCFRONT_vehicleStatus" 925 "IBST_status" 914 "BMS_packConfig" 911 "ESP_party3" 901 "ESP_offsets" 851 "UI_status" 825 "VCSEC_authentication" 820 "UI_powertrainControl" 801 "VCFRONT_sensors" 799 "TPMS_data" 792 "GTW_carState" 787 "UI_trackModeSettings" 786 "BMS_thermalStatus" 762 "VCLEFT_prndStatus" 744 "EPBR_status" 741 "DIF_power" 737 "VCFRONT_status" 722 "BMS_driveLimits" 680 "EPBL_status" 679 "CMPD_state" 662 "UI_chassisControlDebug" 659 "UI_chassisControl" 644 "UI_vehicleModes" 634 "DIF_hvStatus" 633 "DIR_hvStatus" 614 "DIR_power" 605 "CP_status" 604 "APP_environment" 603 "APP_status" 602 "VCSEC_TPMSDisplay" 594 "BMS_powerAvailable" 583 "CMP_HVStatus" 578 "VCLEFT_LVPowerState" 577 "VCFRONT_coolant" 568 "UI_driverAssistMapData" 553 "SCCM_rightStalk" 549 "VCRIGHT_LVPowerState" 545 "VCFRONT_LVPowerState" 531 "UI_cruiseControl" 530 "BMS_status" 525 "TAS_states" 519 "PTC_feedbackStatus" 472 "PMR_state4" 469 "PMF_state4" 463 "PM_systemState" 389 "ESP_brakeTorque" 373 "ESP_wheelSpeeds" 344 "ESP_wheelRotation" 328 "ESP_status" 327 "RCU_actuation" 322 "VCLEFT_liftgateStatus" 306 "BMS_hvBusStatus" 285 "ESP_vdcStatus" 272 "BB_brakeActuation" 271 "DBG_swanCommand" 261 "ESP_motorLimits" 259 "VCRIGHT_doorStatus" 258 "VCLEFT_doorStatus" 130 "UI_tripPlanning" ;
VAL_ 1319 DI_a053_errorType 6 "UNKNOWN_ID" 5 "DATA_INVALID" 4 "SEQUENCE" 3 "CHECKSUM" 2 "LENGTH_LONG" 1 "LENGTH_SHORT" 0 "NONE" ;
VAL_ 1319 DI_a056_canID 2047 "GTW_carConfig" 1926 "DBG_dynoVehicleSim" 1911 "XCP_diRequest" 1863 "DBG_vdcControl" 1656 "GTW_gearControl" 1589 "UDS_diRequest" 1349 "VCFRONT_systemStatus" 1320 "GTW_time" 1280 "UI_debugECU" 1106 "BMS_voltageRegGain" 1021 "UI_autopilotControl" 1005 "GTW_updateStatus" 985 "VCSEC_authenticityResponse" 962 "VCLEFT_switchStatus" 947 "UI_vehicleControl2" 944 "DPB_actuator3" 943 "BB_status" 929 "VCFRONT_vehicleStatus" 925 "IBST_status" 914 "BMS_packConfig" 911 "ESP_party3" 901 "ESP_offsets" 851 "UI_status" 825 "VCSEC_authentication" 820 "UI_powertrainControl" 801 "VCFRONT_sensors" 799 "TPMS_data" 792 "GTW_carState" 787 "UI_trackModeSettings" 786 "BMS_thermalStatus" 762 "VCLEFT_prndStatus" 744 "EPBR_status" 741 "DIF_power" 737 "VCFRONT_status" 722 "BMS_driveLimits" 680 "EPBL_status" 679 "CMPD_state" 662 "UI_chassisControlDebug" 659 "UI_chassisControl" 644 "UI_vehicleModes" 634 "DIF_hvStatus" 633 "DIR_hvStatus" 614 "DIR_power" 605 "CP_status" 604 "APP_environment" 603 "APP_status" 602 "VCSEC_TPMSDisplay" 594 "BMS_powerAvailable" 583 "CMP_HVStatus" 578 "VCLEFT_LVPowerState" 577 "VCFRONT_coolant" 568 "UI_driverAssistMapData" 553 "SCCM_rightStalk" 549 "VCRIGHT_LVPowerState" 545 "VCFRONT_LVPowerState" 531 "UI_cruiseControl" 530 "BMS_status" 525 "TAS_states" 519 "PTC_feedbackStatus" 472 "PMR_state4" 469 "PMF_state4" 463 "PM_systemState" 389 "ESP_brakeTorque" 373 "ESP_wheelSpeeds" 344 "ESP_wheelRotation" 328 "ESP_status" 327 "RCU_actuation" 322 "VCLEFT_liftgateStatus" 306 "BMS_hvBusStatus" 285 "ESP_vdcStatus" 272 "BB_brakeActuation" 271 "DBG_swanCommand" 261 "ESP_motorLimits" 259 "VCRIGHT_doorStatus" 258 "VCLEFT_doorStatus" 130 "UI_tripPlanning" ;
VAL_ 1319 DI_a056_errorType 6 "UNKNOWN_ID" 5 "DATA_INVALID" 4 "SEQUENCE" 3 "CHECKSUM" 2 "LENGTH_LONG" 1 "LENGTH_SHORT" 0 "NONE" ;
VAL_ 1319 DI_a059_canID 2047 "GTW_carConfig" 1926 "DBG_dynoVehicleSim" 1911 "XCP_diRequest" 1863 "DBG_vdcControl" 1656 "GTW_gearControl" 1589 "UDS_diRequest" 1349 "VCFRONT_systemStatus" 1320 "GTW_time" 1280 "UI_debugECU" 1106 "BMS_voltageRegGain" 1021 "UI_autopilotControl" 1005 "GTW_updateStatus" 985 "VCSEC_authenticityResponse" 962 "VCLEFT_switchStatus" 947 "UI_vehicleControl2" 944 "DPB_actuator3" 943 "BB_status" 929 "VCFRONT_vehicleStatus" 925 "IBST_status" 914 "BMS_packConfig" 911 "ESP_party3" 901 "ESP_offsets" 851 "UI_status" 825 "VCSEC_authentication" 820 "UI_powertrainControl" 801 "VCFRONT_sensors" 799 "TPMS_data" 792 "GTW_carState" 787 "UI_trackModeSettings" 786 "BMS_thermalStatus" 762 "VCLEFT_prndStatus" 744 "EPBR_status" 741 "DIF_power" 737 "VCFRONT_status" 722 "BMS_driveLimits" 680 "EPBL_status" 679 "CMPD_state" 662 "UI_chassisControlDebug" 659 "UI_chassisControl" 644 "UI_vehicleModes" 634 "DIF_hvStatus" 633 "DIR_hvStatus" 614 "DIR_power" 605 "CP_status" 604 "APP_environment" 603 "APP_status" 602 "VCSEC_TPMSDisplay" 594 "BMS_powerAvailable" 583 "CMP_HVStatus" 578 "VCLEFT_LVPowerState" 577 "VCFRONT_coolant" 568 "UI_driverAssistMapData" 553 "SCCM_rightStalk" 549 "VCRIGHT_LVPowerState" 545 "VCFRONT_LVPowerState" 531 "UI_cruiseControl" 530 "BMS_status" 525 "TAS_states" 519 "PTC_feedbackStatus" 472 "PMR_state4" 469 "PMF_state4" 463 "PM_systemState" 389 "ESP_brakeTorque" 373 "ESP_wheelSpeeds" 344 "ESP_wheelRotation" 328 "ESP_status" 327 "RCU_actuation" 322 "VCLEFT_liftgateStatus" 306 "BMS_hvBusStatus" 285 "ESP_vdcStatus" 272 "BB_brakeActuation" 271 "DBG_swanCommand" 261 "ESP_motorLimits" 259 "VCRIGHT_doorStatus" 258 "VCLEFT_doorStatus" 130 "UI_tripPlanning" ;
VAL_ 1319 DI_a059_errorType 6 "UNKNOWN_ID" 5 "DATA_INVALID" 4 "SEQUENCE" 3 "CHECKSUM" 2 "LENGTH_LONG" 1 "LENGTH_SHORT" 0 "NONE" ;
VAL_ 1319 DI_a062_limpReason 42 "DEGRADED_REQUEST_VCRIGHT" 41 "DEGRADED_REQUEST_VCLEFT" 40 "DEGRADED_REQUEST_PEPS" 39 "DEGRADED_REQUEST_SEPS" 38 "DEGRADED_REQUEST_PSFA" 37 "DEGRADED_REQUEST_SSFA" 36 "XTAL_OSCILLATOR" 35 "CURRENT_CORE_FALLBACK" 34 "MECHANICAL_SAFE_ST_UNAVAIL" 33 "MOTION_IN_DYNO" 32 "RESIST_STATOR_TEMP" 31 "OIL_PRESSURE_LOW" 30 "HEATSINK_SENSOR_IRRATIONAL" 29 "OIL_PUMP_FLUID_OVERTEMP" 28 "OIL_PUMP_FAILURE" 27 "FACTORY_GLIDER" 26 "SLAVE_MIA" 25 "SLAVE_REQUEST" 24 "CONTACTOR_WELD" 23 "CAPACITOR_OVERTEMP" 22 "GTW_MIA" 21 "TRQCMD_VALIDITY_UNKNOWN" 20 "DI_MIA" 19 "CONFIG_MISMATCH" 18 "HEATSINK_TEMP" 17 "PMREQUEST" 16 "PMHEARTBEAT" 15 "TRQ_CROSS_CHECK" 14 "EXTERNAL_COMMAND" 13 "WRONG_CS_CALIBRATION" 12 "STATOR_TEMP" 11 "DELTAT_TOO_NEGATIVE" 10 "DELTAT_TOO_POSITIVE" 9 "AMBIENT_TEMP" 8 "OUTLET_TEMP" 7 "LOW_FLOW" 6 "BMS_MIA" 5 "LV_SUPPLY_UNDERVOLTAGE" 4 "NO_FLUID" 3 "NO_FUNC_HEATSINK_SENSOR" 2 "NO_FUNC_STATORT_SENSOR" 1 "BUSV_SENSOR_IRRATIONAL" 0 "PHASE_IMBALANCE" ;
VAL_ 1319 DI_a063_gpoReason 14 "MOTION_EXPECTED_DURING_SPINDOWN_LEARNING" 13 "FACTORY_DRIVE_DISTANCE_EXCEEDED" 12 "DEGRADED_LIMP_NO_DECEL" 11 "DEGRADED_LIMP_TIMEOUT" 10 "SBW_NODE_UNAVAILABLE" 9 "MOTION_DURING_SPINDOWN_LEARNING" 8 "MOTOR_HALT_REQUEST" 7 "CAPACITOR_OVERTEMP" 6 "NOT_ENOUGH_12V" 5 "NO_BATTERY_POWER" 4 "AMBIENT_OVERTEMP" 3 "FLUID_DELTAT" 2 "STATOR_OVERTEMP" 1 "HEATSINK_OVERTEMP" 0 "OUTLET_OVERTEMP" ;
VAL_ 1319 DI_a064_hvState 6 "UP" 5 "UP_FOR_DC_CHARGE" 4 "UP_FOR_CHARGE" 3 "UP_FOR_DRIVE" 2 "GOING_DOWN" 1 "COMING_UP" 0 "DOWN" ;
VAL_ 1319 DI_a064_vehiclePowerState 3 "DRIVE" 2 "ACCESSORY" 1 "CONDITIONING" 0 "OFF" ;
VAL_ 1319 DI_a066_canID 2047 "GTW_carConfig" 1926 "DBG_dynoVehicleSim" 1911 "XCP_diRequest" 1863 "DBG_vdcControl" 1656 "GTW_gearControl" 1589 "UDS_diRequest" 1349 "VCFRONT_systemStatus" 1320 "GTW_time" 1280 "UI_debugECU" 1106 "BMS_voltageRegGain" 1021 "UI_autopilotControl" 1005 "GTW_updateStatus" 985 "VCSEC_authenticityResponse" 962 "VCLEFT_switchStatus" 947 "UI_vehicleControl2" 944 "DPB_actuator3" 943 "BB_status" 929 "VCFRONT_vehicleStatus" 925 "IBST_status" 914 "BMS_packConfig" 911 "ESP_party3" 901 "ESP_offsets" 851 "UI_status" 825 "VCSEC_authentication" 820 "UI_powertrainControl" 801 "VCFRONT_sensors" 799 "TPMS_data" 792 "GTW_carState" 787 "UI_trackModeSettings" 786 "BMS_thermalStatus" 762 "VCLEFT_prndStatus" 744 "EPBR_status" 741 "DIF_power" 737 "VCFRONT_status" 722 "BMS_driveLimits" 680 "EPBL_status" 679 "CMPD_state" 662 "UI_chassisControlDebug" 659 "UI_chassisControl" 644 "UI_vehicleModes" 634 "DIF_hvStatus" 633 "DIR_hvStatus" 614 "DIR_power" 605 "CP_status" 604 "APP_environment" 603 "APP_status" 602 "VCSEC_TPMSDisplay" 594 "BMS_powerAvailable" 583 "CMP_HVStatus" 578 "VCLEFT_LVPowerState" 577 "VCFRONT_coolant" 568 "UI_driverAssistMapData" 553 "SCCM_rightStalk" 549 "VCRIGHT_LVPowerState" 545 "VCFRONT_LVPowerState" 531 "UI_cruiseControl" 530 "BMS_status" 525 "TAS_states" 519 "PTC_feedbackStatus" 472 "PMR_state4" 469 "PMF_state4" 463 "PM_systemState" 389 "ESP_brakeTorque" 373 "ESP_wheelSpeeds" 344 "ESP_wheelRotation" 328 "ESP_status" 327 "RCU_actuation" 322 "VCLEFT_liftgateStatus" 306 "BMS_hvBusStatus" 285 "ESP_vdcStatus" 272 "BB_brakeActuation" 271 "DBG_swanCommand" 261 "ESP_motorLimits" 259 "VCRIGHT_doorStatus" 258 "VCLEFT_doorStatus" 130 "UI_tripPlanning" ;
VAL_ 1319 DI_a066_errorType 6 "UNKNOWN_ID" 5 "DATA_INVALID" 4 "SEQUENCE" 3 "CHECKSUM" 2 "LENGTH_LONG" 1 "LENGTH_SHORT" 0 "NONE" ;
VAL_ 1319 DI_a090_reason 1 "TOOFAST" 0 "TOOSLOW" ;
VAL_ 1319 DI_a094_canID 2047 "GTW_carConfig" 1926 "DBG_dynoVehicleSim" 1911 "XCP_diRequest" 1863 "DBG_vdcControl" 1656 "GTW_gearControl" 1589 "UDS_diRequest" 1349 "VCFRONT_systemStatus" 1320 "GTW_time" 1280 "UI_debugECU" 1106 "BMS_voltageRegGain" 1021 "UI_autopilotControl" 1005 "GTW_updateStatus" 985 "VCSEC_authenticityResponse" 962 "VCLEFT_switchStatus" 947 "UI_vehicleControl2" 944 "DPB_actuator3" 943 "BB_status" 929 "VCFRONT_vehicleStatus" 925 "IBST_status" 914 "BMS_packConfig" 911 "ESP_party3" 901 "ESP_offsets" 851 "UI_status" 825 "VCSEC_authentication" 820 "UI_powertrainControl" 801 "VCFRONT_sensors" 799 "TPMS_data" 792 "GTW_carState" 787 "UI_trackModeSettings" 786 "BMS_thermalStatus" 762 "VCLEFT_prndStatus" 744 "EPBR_status" 741 "DIF_power" 737 "VCFRONT_status" 722 "BMS_driveLimits" 680 "EPBL_status" 679 "CMPD_state" 662 "UI_chassisControlDebug" 659 "UI_chassisControl" 644 "UI_vehicleModes" 634 "DIF_hvStatus" 633 "DIR_hvStatus" 614 "DIR_power" 605 "CP_status" 604 "APP_environment" 603 "APP_status" 602 "VCSEC_TPMSDisplay" 594 "BMS_powerAvailable" 583 "CMP_HVStatus" 578 "VCLEFT_LVPowerState" 577 "VCFRONT_coolant" 568 "UI_driverAssistMapData" 553 "SCCM_rightStalk" 549 "VCRIGHT_LVPowerState" 545 "VCFRONT_LVPowerState" 531 "UI_cruiseControl" 530 "BMS_status" 525 "TAS_states" 519 "PTC_feedbackStatus" 472 "PMR_state4" 469 "PMF_state4" 463 "PM_systemState" 389 "ESP_brakeTorque" 373 "ESP_wheelSpeeds" 344 "ESP_wheelRotation" 328 "ESP_status" 327 "RCU_actuation" 322 "VCLEFT_liftgateStatus" 306 "BMS_hvBusStatus" 285 "ESP_vdcStatus" 272 "BB_brakeActuation" 271 "DBG_swanCommand" 261 "ESP_motorLimits" 259 "VCRIGHT_doorStatus" 258 "VCLEFT_doorStatus" 130 "UI_tripPlanning" ;
VAL_ 1319 DI_a094_errorType 6 "UNKNOWN_ID" 5 "DATA_INVALID" 4 "SEQUENCE" 3 "CHECKSUM" 2 "LENGTH_LONG" 1 "LENGTH_SHORT" 0 "NONE" ;
VAL_ 1319 DI_a097_errorType 6 "DPOT_WRITE" 5 "DPOT_READ" 4 "LOST" 3 "CRC" 2 "WRITE" 1 "READ" 0 "OPEN" ;
VAL_ 1319 DI_a098_errorCode 8 "POST_SWAP_ERASE" 7 "PRE_SWAP_ERASE" 6 "EXCEPTION_ERASE" 5 "NO_RECORD" 4 "BAD_RECORD" 3 "BAD_PAGE" 2 "INIT_ERASE" 1 "SWAP_WRITE" 0 "RECORD_WRITE" ;
VAL_ 1319 DI_a104_proxIrrationalReason 1 "CP_MISMATCH" 0 "PROX_HARDLINE_TOGGLE" ;
VAL_ 1319 DI_a120_blendingState 3 "FRICTION_ONLY" 2 "ACTIVE" 1 "STANDBY" 0 "UNAVAILABLE" ;
VAL_ 1319 DI_a120_blendingUnavailableReaso 18 "DI_LATENT_FAULT_TRIP" 17 "EBR_FULL_FAULT" 16 "PM_DISABLE_REQUEST_BPED" 15 "PM_DISABLE_REQUEST_BLEND" 14 "CARBON_CERAMIC_BRAKES" 13 "BRAKE_TEMP" 12 "EBR_FAULT" 11 "PM_DISABLE_REQUEST" 10 "TRACK_MODE_ACTIVE" 9 "VELOCITY_ESTIMATOR_UNAVAILABLE" 8 "TRACTION_CONTROL_UNAVAILABLE" 7 "ACTIVE_DAMPING_UNAVAILABLE" 6 "UI_COASTDOWN_MODE" 5 "SYSTEM_STATE" 4 "NON_DRIVE_GEAR" 3 "EBR_UNAVAILABLE" 2 "UI_DISABLE" 1 "GTW_DISABLE" 0 "NONE" ;
VAL_ 1319 DI_a124_cruiseFaultReason 22 "VHLD_FAULTED" 21 "CONFIG_MISMATCH" 20 "EPB_MIA" 19 "ACCEL_JERK_OUT_OF_ISO_BOUNDS" 17 "DAS_SNA" 16 "VELOCITY_ESTIMATE_NOT_NORMAL" 15 "ACCEL_OUT_OF_BOUNDS" 14 "EBR_FAULT" 13 "TC_FAULT" 12 "ESP_MIA" 11 "VDC_FAULT" 10 "EPB_FAULT" 9 "BRAKE_MIA" 8 "CRS_STATE_MISM" 7 "ABS_MIA" 6 "CRUISE_SCCM_MIA" 5 "BRAKE_INVALID" 4 "STALK" 3 "PM_REQUEST" 2 "PM_MIA" 1 "MOTOR_SPEED_MISMATCH" 0 "NONE" ;
VAL_ 1319 DI_a130_aebFaultReason 15 "DAS_REQ_DI_UNAVAIL" 14 "ACCEL_REQ_INVALID" 13 "MIN_TIME_BTWN_EVENTS" 12 "ESP_MIA" 11 "ESP_FAULT" 10 "EPB_NOT_PARKED" 9 "ACCEL_OUT_OF_BOUNDS" 8 "PM_REQUEST" 7 "VEL_EST_ABNORMAL" 6 "DAS_SNA" 4 "SPEED_DELTA" 3 "EBR_FAULT" 2 "PM_MIA" 1 "EPB_MIA" 0 "NONE" ;
VAL_ 1319 DI_a130_aebSmState 5 "FAULT" 4 "EXIT" 3 "STANDSTILL" 2 "ENABLE" 1 "STANDBY" 0 "UNAVAILABLE" ;
VAL_ 1319 DI_a130_dasAebEvent 3 "SNA" 2 "FAULT" 1 "ACTIVE" 0 "NOT_ACTIVE" ;
VAL_ 1319 DI_a135_vhldFaultReason 10 "ESP_MIA" 9 "VDC_FAULT" 8 "NOT_STOPPED" 7 "EPB_NOT_PARKED" 6 "PM_REQUEST" 5 "WHEEL_SPDS_INVAL" 4 "BRAKE_INVALID" 3 "EBR_FAULT" 2 "EPB_MIA" 1 "PM_MIA" 0 "NONE" ;
VAL_ 1319 DI_a146_panicReason 6 "EPB_RELEASE_TIMEOUT" 5 "SKID_DETECTED" 4 "EPB_INVALID" 3 "EPB_APPLY_TIMEOUT" 2 "EPB_MIA" 1 "EPB_FAULT" 0 "NONE" ;
VAL_ 1319 DI_a160_tireFitment 3 "SNA" 1 "STAGGERED" 0 "SQUARE" ;
VAL_ 1319 DI_a160_distanceSinceLastTireCon 4095 "SNA" ;
VAL_ 1319 DI_a162_shiftDeniedReason 9 "GARAGE_SHIFT_PEDAL" 8 "DRIVE_RAIL_GOING_DOWN" 7 "SHIFT_AFTER_CRUISE_CANCEL" 6 "BRAKE_AFTER_CRUISE_CANCEL" 5 "ACCEL_PEDAL_PRESSED" 4 "SYS_STATE_NOT_ENABLED" 3 "APC_PARKING" 2 "AUTOPILOT_DRIVER_LOCKOUT" 1 "NO_BRAKES_FACTORY" 0 "MOTOR_SPEED" ;
VAL_ 1319 DI_a162_currentGear 7 "SNA" 4 "D" 3 "N" 2 "R" 1 "P" 0 "INVALID" ;
VAL_ 1319 DI_a162_requestedGear 7 "SNA" 4 "D" 3 "N" 2 "R" 1 "P" 0 "INVALID" ;
VAL_ 1319 DI_a162_requestSource 8 "SMART_SHIFT" 7 "CCCM_SHIFT" 6 "GTW_SHIFT" 5 "PM" 4 "DENIED_SHIFT" 3 "LONC" 2 "AUTOPARK" 1 "EPB" 0 "DRIVER" ;
VAL_ 1319 DI_a162_sysStateExitCondition 19 "IDLE_TRUNK_OPEN" 18 "UNAVAILABLE_EXIT_OK" 17 "UNAVAILABLE_UNITS_NOT_AVAILABLE" 16 "UNAVAILABLE_SSPD_SPEED_IS_NOT_PUBLISHED" 15 "UNAVAILABLE_ALERTS_ACTIVE" 14 "UNAVAILABLE_HV_IS_NOT_UP" 13 "UNAVAILABLE_SLIM_GPO_OR_CAN_DRIVE_GOING_DOWN" 12 "IDLE_EXIT_OK" 11 "IDLE_FIRMWARE_VERIFICATION" 10 "IDLE_BATTERY_POWER_LIMITS" 9 "IDLE_NON_ZERO_PEDAL_POS" 8 "IDLE_FALCON_DOOR_OPEN" 7 "IDLE_PROX_DETECTED" 6 "IDLE_FRUNK_NOT_LATCHED" 5 "IDLE_IMMOBILIZER_INHIBIT" 4 "IDLE_HV_NOT_UP_FOR_DRIVE" 3 "IDLE_LV_OR_SBW_STATUS_LIMP" 2 "IDLE_LV_OR_SBW_STATUS_NOT_READY" 1 "IDLE_DRIVE_RAIL_NOT_REQUESTED" 0 "IDLE_VEHICLE_POWER_STATE_NOT_DRIVE" ;
VAL_ 1319 DI_a163_currentGear 7 "SNA" 4 "D" 3 "N" 2 "R" 1 "P" 0 "INVALID" ;
VAL_ 1319 DI_a163_requestedGear 7 "SNA" 4 "D" 3 "N" 2 "R" 1 "P" 0 "INVALID" ;
VAL_ 1319 DI_a163_requestSource 8 "SMART_SHIFT" 7 "CCCM_SHIFT" 6 "GTW_SHIFT" 5 "PM" 4 "DENIED_SHIFT" 3 "LONC" 2 "AUTOPARK" 1 "EPB" 0 "DRIVER" ;
VAL_ 1319 DI_a165_crsCancelReason 10 "ACC_FSD_EXIT" 9 "SHIFT_REQUEST" 8 "ACCEL_OVERRIDE_IN_REVERSE" 7 "DAS" 6 "PARK" 5 "GEAR" 4 "STALK" 3 "BRAKE" 2 "SKID" 1 "APC_REQUEST" 0 "NONE" ;
VAL_ 1319 DI_a170_tireSeasonSelected 1 "WINTER" 0 "NON_WINTER" ;
VAL_ 1319 DI_a170_tireFitment 3 "SNA" 1 "STAGGERED" 0 "SQUARE" ;
VAL_ 1319 DI_a170_odometer 4095 "SNA" ;
VAL_ 1319 DI_a170_distanceSinceLastTireCon 63 "SNA" ;
VAL_ 1319 DI_a172_currentGear 7 "SNA" 4 "D" 3 "N" 2 "R" 1 "P" 0 "INVALID" ;
VAL_ 1319 DI_a175_crsNotAvailableReason 40 "FACTORY_MODE" 36 "DFLK_ENGAGED" 35 "INTERFACE_NOT_SUPPORTED" 34 "CANCEL_ACTIVE" 33 "CONTROL_STACK_SWITCH" 32 "SHIFT_OUTSIDE_SPEED_THRESHOLD" 31 "SHIFT_TIMEOUT" 30 "OFFROAD_MODE_ACTIVE" 29 "DAS_CONTROL_MIA" 28 "UNIT0_FAULT" 27 "BRAKE_TEMPERATURE" 26 "ACC_BACKWARD_AT_HIGH_FORWARD_SPEED" 25 "DAS_SET_SPEED_TOO_HIGH_IN_REVERSE" 24 "MOTOR_SPEED_TOO_HIGH_IN_REVERSE" 23 "VHLD_UNAVAILABLE" 22 "CRUISE_FAULTED" 21 "TRACK_MODE_ACTIVE" 20 "DAS_SNA" 19 "UI_MIA" 18 "WAIT_INIT" 17 "VEL_EST" 16 "MAX_SPEED" 15 "MIN_SPEED" 14 "AEB" 13 "CONFIG" 12 "DI_STATE" 11 "MOTOR_SPEED" 10 "EBR" 9 "VALET_MODE" 8 "SEAT_BELT_UNBUCKLED" 7 "CLOSURE_OPEN" 6 "ACC_CANCEL" 5 "ABS_ACTIVE" 4 "TC_ACTIVE" 3 "VDC_ACTIVE_OR_DEGRADED" 2 "VDC_OR_TC_OFF" 1 "NO_ALERT" 0 "NONE" ;
VAL_ 1319 DI_a177_newFitment 3 "SNA" 1 "STAGGERED" 0 "SQUARE" ;
VAL_ 1319 DI_a180_crsNotAvailableReason 40 "FACTORY_MODE" 36 "DFLK_ENGAGED" 35 "INTERFACE_NOT_SUPPORTED" 34 "CANCEL_ACTIVE" 33 "CONTROL_STACK_SWITCH" 32 "SHIFT_OUTSIDE_SPEED_THRESHOLD" 31 "SHIFT_TIMEOUT" 30 "OFFROAD_MODE_ACTIVE" 29 "DAS_CONTROL_MIA" 28 "UNIT0_FAULT" 27 "BRAKE_TEMPERATURE" 26 "ACC_BACKWARD_AT_HIGH_FORWARD_SPEED" 25 "DAS_SET_SPEED_TOO_HIGH_IN_REVERSE" 24 "MOTOR_SPEED_TOO_HIGH_IN_REVERSE" 23 "VHLD_UNAVAILABLE" 22 "CRUISE_FAULTED" 21 "TRACK_MODE_ACTIVE" 20 "DAS_SNA" 19 "UI_MIA" 18 "WAIT_INIT" 17 "VEL_EST" 16 "MAX_SPEED" 15 "MIN_SPEED" 14 "AEB" 13 "CONFIG" 12 "DI_STATE" 11 "MOTOR_SPEED" 10 "EBR" 9 "VALET_MODE" 8 "SEAT_BELT_UNBUCKLED" 7 "CLOSURE_OPEN" 6 "ACC_CANCEL" 5 "ABS_ACTIVE" 4 "TC_ACTIVE" 3 "VDC_ACTIVE_OR_DEGRADED" 2 "VDC_OR_TC_OFF" 1 "NO_ALERT" 0 "NONE" ;
VAL_ 1319 DI_a184_apcCancelReason 25 "ABORT_CONTROL_STACK_SWITCH" 24 "ABORT_GEAR_STALK" 23 "ABORT_EPB_INTERLOCK" 22 "ABORT_EPB_FAULT" 21 "ABORT_DISTANCE" 20 "ABORT_GRADE_TOO_STEEP" 19 "ABORT_VEHICLE_SPEED" 18 "ABORT_DAS_SPEED" 17 "CANCEL_SELFPARK_STATE_TIMEOUT" 16 "ABORT_DRIVER_LEAVING" 15 "ABORT_CLOSURE" 14 "ABORT_BRAKE" 13 "ABORT_CRUISE_STATE" 12 "ABORT_STOPPING_TIMEOUT" 11 "ABORT_DI_SYS_STATE" 10 "ABORT_SHIFT_TIMEOUT" 9 "ABORT_CONTROL_INTEGRATOR" 8 "ABORT_DAS_STATE" 7 "ABORT_DAS_REQUEST" 6 "CANCEL_CRUISE" 5 "CANCEL_AEB_ACTIVE" 4 "ABORT_MOTION_TIMEOUT" 3 "ABORT_OVERRIDE" 2 "CANCEL_EPB_APPLY" 1 "CANCEL_GEAR" 0 "CANCEL_NONE" ;
VAL_ 1319 DI_a184_apcUnavailableReason 15 "TEMP_TOO_COLD" 14 "ACCEL_PEDAL" 13 "BRAKE_PEDAL" 12 "SYSTEM_STATE" 11 "EBR" 10 "GEAR" 9 "NOT_SUPPORTED" 8 "TRAILER_MODE" 7 "EPB" 6 "VALET_MODE" 5 "GRADE_TOO_STEEP" 4 "DRIVER_LEAVING" 3 "CLOSURE_OPEN" 2 "VDC" 1 "CRUISE" 0 "NONE" ;
VAL_ 1319 DI_a184_autoparkInternalState 17 "ABORTED" 16 "ABORTING" 15 "UNPARK_COMPLETE" 14 "COMPLETE" 13 "PRE_COMPLETE" 12 "ACTIVE_SHFT_R" 11 "ACTIVE_SHFT_D" 10 "ACTIVE_DRIVE_FW" 9 "ACTIVE_DRIVE_BW" 8 "RESUMED" 7 "PAUSED" 6 "PAUSING" 5 "SELFPARK_UNPARK" 4 "SELFPARK_START" 3 "STARTED_CRUISE" 2 "STARTED_BRAKE" 1 "STANDBY" 0 "UNAVAILABLE" ;
VAL_ 1319 DI_a185_apcCancelReason 25 "ABORT_CONTROL_STACK_SWITCH" 24 "ABORT_GEAR_STALK" 23 "ABORT_EPB_INTERLOCK" 22 "ABORT_EPB_FAULT" 21 "ABORT_DISTANCE" 20 "ABORT_GRADE_TOO_STEEP" 19 "ABORT_VEHICLE_SPEED" 18 "ABORT_DAS_SPEED" 17 "CANCEL_SELFPARK_STATE_TIMEOUT" 16 "ABORT_DRIVER_LEAVING" 15 "ABORT_CLOSURE" 14 "ABORT_BRAKE" 13 "ABORT_CRUISE_STATE" 12 "ABORT_STOPPING_TIMEOUT" 11 "ABORT_DI_SYS_STATE" 10 "ABORT_SHIFT_TIMEOUT" 9 "ABORT_CONTROL_INTEGRATOR" 8 "ABORT_DAS_STATE" 7 "ABORT_DAS_REQUEST" 6 "CANCEL_CRUISE" 5 "CANCEL_AEB_ACTIVE" 4 "ABORT_MOTION_TIMEOUT" 3 "ABORT_OVERRIDE" 2 "CANCEL_EPB_APPLY" 1 "CANCEL_GEAR" 0 "CANCEL_NONE" ;
VAL_ 1319 DI_a185_apcUnavailableReason 15 "TEMP_TOO_COLD" 14 "ACCEL_PEDAL" 13 "BRAKE_PEDAL" 12 "SYSTEM_STATE" 11 "EBR" 10 "GEAR" 9 "NOT_SUPPORTED" 8 "TRAILER_MODE" 7 "EPB" 6 "VALET_MODE" 5 "GRADE_TOO_STEEP" 4 "DRIVER_LEAVING" 3 "CLOSURE_OPEN" 2 "VDC" 1 "CRUISE" 0 "NONE" ;
VAL_ 1319 DI_a185_crsNotAvailableReason 40 "FACTORY_MODE" 36 "DFLK_ENGAGED" 35 "INTERFACE_NOT_SUPPORTED" 34 "CANCEL_ACTIVE" 33 "CONTROL_STACK_SWITCH" 32 "SHIFT_OUTSIDE_SPEED_THRESHOLD" 31 "SHIFT_TIMEOUT" 30 "OFFROAD_MODE_ACTIVE" 29 "DAS_CONTROL_MIA" 28 "UNIT0_FAULT" 27 "BRAKE_TEMPERATURE" 26 "ACC_BACKWARD_AT_HIGH_FORWARD_SPEED" 25 "DAS_SET_SPEED_TOO_HIGH_IN_REVERSE" 24 "MOTOR_SPEED_TOO_HIGH_IN_REVERSE" 23 "VHLD_UNAVAILABLE" 22 "CRUISE_FAULTED" 21 "TRACK_MODE_ACTIVE" 20 "DAS_SNA" 19 "UI_MIA" 18 "WAIT_INIT" 17 "VEL_EST" 16 "MAX_SPEED" 15 "MIN_SPEED" 14 "AEB" 13 "CONFIG" 12 "DI_STATE" 11 "MOTOR_SPEED" 10 "EBR" 9 "VALET_MODE" 8 "SEAT_BELT_UNBUCKLED" 7 "CLOSURE_OPEN" 6 "ACC_CANCEL" 5 "ABS_ACTIVE" 4 "TC_ACTIVE" 3 "VDC_ACTIVE_OR_DEGRADED" 2 "VDC_OR_TC_OFF" 1 "NO_ALERT" 0 "NONE" ;
VAL_ 1319 DI_a185_crsFaultReason 22 "VHLD_FAULTED" 21 "CONFIG_MISMATCH" 20 "EPB_MIA" 19 "ACCEL_JERK_OUT_OF_ISO_BOUNDS" 17 "DAS_SNA" 16 "VELOCITY_ESTIMATE_NOT_NORMAL" 15 "ACCEL_OUT_OF_BOUNDS" 14 "EBR_FAULT" 13 "TC_FAULT" 12 "ESP_MIA" 11 "VDC_FAULT" 10 "EPB_FAULT" 9 "BRAKE_MIA" 8 "CRS_STATE_MISM" 7 "ABS_MIA" 6 "CRUISE_SCCM_MIA" 5 "BRAKE_INVALID" 4 "STALK" 3 "PM_REQUEST" 2 "PM_MIA" 1 "MOTOR_SPEED_MISMATCH" 0 "NONE" ;
VAL_ 1319 DI_a185_autoparkInternalState 17 "ABORTED" 16 "ABORTING" 15 "UNPARK_COMPLETE" 14 "COMPLETE" 13 "PRE_COMPLETE" 12 "ACTIVE_SHFT_R" 11 "ACTIVE_SHFT_D" 10 "ACTIVE_DRIVE_FW" 9 "ACTIVE_DRIVE_BW" 8 "RESUMED" 7 "PAUSED" 6 "PAUSING" 5 "SELFPARK_UNPARK" 4 "SELFPARK_START" 3 "STARTED_CRUISE" 2 "STARTED_BRAKE" 1 "STANDBY" 0 "UNAVAILABLE" ;
VAL_ 1319 DI_a191_currentGear 7 "SNA" 4 "D" 3 "N" 2 "R" 1 "P" 0 "INVALID" ;
VAL_ 1319 DI_a191_requestedGear 7 "SNA" 4 "D" 3 "N" 2 "R" 1 "P" 0 "INVALID" ;
VAL_ 1319 DI_a191_requestSource 8 "SMART_SHIFT" 7 "CCCM_SHIFT" 6 "GTW_SHIFT" 5 "PM" 4 "DENIED_SHIFT" 3 "LONC" 2 "AUTOPARK" 1 "EPB" 0 "DRIVER" ;
VAL_ 1319 DI_a193_brakeTorqueFrL 7 "TEMP_QF_INVALID" 6 "QF_VALIDITY" 5 "CAN" 4 "QF" 3 "RATE" 2 "FREEZE" 1 "RANGE" 0 "VALID" ;
VAL_ 1319 DI_a193_brakeTorqueFrR 7 "TEMP_QF_INVALID" 6 "QF_VALIDITY" 5 "CAN" 4 "QF" 3 "RATE" 2 "FREEZE" 1 "RANGE" 0 "VALID" ;
VAL_ 1319 DI_a194_brakeTorqueReL 7 "TEMP_QF_INVALID" 6 "QF_VALIDITY" 5 "CAN" 4 "QF" 3 "RATE" 2 "FREEZE" 1 "RANGE" 0 "VALID" ;
VAL_ 1319 DI_a194_brakeTorqueReR 7 "TEMP_QF_INVALID" 6 "QF_VALIDITY" 5 "CAN" 4 "QF" 3 "RATE" 2 "FREEZE" 1 "RANGE" 0 "VALID" ;
VAL_ 1319 DI_a199_preControlActive 1 "ACTIVE" 0 "NOT_ACTIVE" ;
VAL_ 1319 DI_a199_oversteerdMzActive 1 "ACTIVE" 0 "NOT_ACTIVE" ;
VAL_ 1319 DI_a199_decelControlActive 1 "ACTIVE" 0 "NOT_ACTIVE" ;
VAL_ 1319 DI_a199_understeerdMzActive 1 "ACTIVE" 0 "NOT_ACTIVE" ;
VAL_ 1319 DI_a199_vdcMode 2 "TRACK" 1 "ON" 0 "OFF" ;
VAL_ 1319 DI_a200_MBPCheckStatus 1 "ACTIVE" 0 "GHOSTED" ;
VAL_ 1319 DI_a200_MBPFailedCase 33 "FR_DFLK_VS_WHEEL_SPEED_DIFF" 32 "RE_DFLK_VS_WHEEL_SPEED_DIFF" 31 "NONLINEAR_YAW_RATE_STEERING_ANGLE_VELOCITY" 30 "PERSIST_PITCH_RATE" 29 "PERSIST_ROLL_RATE" 28 "GRADE_ANGLE" 27 "BANK_ANGLE" 26 "RWD_FR_RIGHT_WHEEL_SPEED" 25 "RWD_FR_LEFT_WHEEL_SPEED" 24 "IBST_STROKE_VS_MC_PRESSURE" 23 "RER_WHEEL_SLIP_WHEELS_SPEEDS_VEHICLE_VELOCITY" 22 "REL_WHEEL_SLIP_WHEELS_SPEEDS_VEHICLE_VELOCITY" 21 "FRR_WHEEL_SLIP_WHEELS_SPEEDS_VEHICLE_VELOCITY" 20 "FRL_WHEEL_SLIP_WHEELS_SPEEDS_VEHICLE_VELOCITY" 19 "RE_WHEEL_SPEED_VS_VDC_MOTOR_SPEED" 18 "FR_WHEEL_SPEED_VS_VDC_MOTOR_SPEED" 17 "OFFSET_VERT_ACCEL" 16 "VERT_ACCEL" 15 "LAT_ACCEL" 14 "LONG_ACCEL" 13 "YAW_RATE" 12 "PITCH_RATE" 11 "ROLL_RATE" 10 "STEERING_ANGLE_OFFSET" 9 "MC_PRESSURE_BRAKE_PEDAL" 8 "BRAKE_TORQUES_VS_LONG_ACCEL" 7 "VELOCITY_ESTIMATE_VS_WHEEL_SPEEDS" 6 "US_VELOCITY_YAW_RATE_VS_LAT_ACCEL" 5 "OS_VELOCITY_YAW_RATE_VS_LAT_ACCEL" 4 "VELOCITY_YAW_RATE_VS_LAT_ACCEL" 3 "TIRE_MISMATCH_DETECTED" 2 "YAW_RATE_WHEEL_SPEEDS" 1 "LAT_ACCEL_STEERING_ANGLE_VELOCITY" 0 "YAW_RATE_STEERING_ANGLE_VELOCITY" ;
VAL_ 1319 DI_a202_reason 12 "HV_DOWN" 11 "CRUISE" 10 "OPD" 9 "DRV_FAULT" 8 "IMMEDIATE" 7 "SERVICE_MODE" 6 "UPDATE_STARTED" 5 "GPO" 4 "LIMP" 3 "MOVEMENT" 2 "PARKBRAKE" 1 "NO_ALERT" 0 "NONE" ;
VAL_ 1319 DI_a202_sysStateExitCondition 19 "IDLE_TRUNK_OPEN" 18 "UNAVAILABLE_EXIT_OK" 17 "UNAVAILABLE_UNITS_NOT_AVAILABLE" 16 "UNAVAILABLE_SSPD_SPEED_IS_NOT_PUBLISHED" 15 "UNAVAILABLE_ALERTS_ACTIVE" 14 "UNAVAILABLE_HV_IS_NOT_UP" 13 "UNAVAILABLE_SLIM_GPO_OR_CAN_DRIVE_GOING_DOWN" 12 "IDLE_EXIT_OK" 11 "IDLE_FIRMWARE_VERIFICATION" 10 "IDLE_BATTERY_POWER_LIMITS" 9 "IDLE_NON_ZERO_PEDAL_POS" 8 "IDLE_FALCON_DOOR_OPEN" 7 "IDLE_PROX_DETECTED" 6 "IDLE_FRUNK_NOT_LATCHED" 5 "IDLE_IMMOBILIZER_INHIBIT" 4 "IDLE_HV_NOT_UP_FOR_DRIVE" 3 "IDLE_LV_OR_SBW_STATUS_LIMP" 2 "IDLE_LV_OR_SBW_STATUS_NOT_READY" 1 "IDLE_DRIVE_RAIL_NOT_REQUESTED" 0 "IDLE_VEHICLE_POWER_STATE_NOT_DRIVE" ;
VAL_ 1319 DI_a203_ptcStateLocal 6 "SNA" 5 "STARTUP" 4 "ON" 3 "ADD_REDUCED" 2 "WHEELS_REDUCED" 1 "BACKUP" 0 "FAULTED" ;
VAL_ 1319 DI_a203_btcState 1 "ON" 0 "OFF" ;
VAL_ 1319 DI_a204_longAccel 7 "TEMP_QF_INVALID" 6 "QF_VALIDITY" 5 "CAN" 4 "QF" 3 "RATE" 2 "FREEZE" 1 "RANGE" 0 "VALID" ;
VAL_ 1319 DI_a204_rollRate 7 "TEMP_QF_INVALID" 6 "QF_VALIDITY" 5 "CAN" 4 "QF" 3 "RATE" 2 "FREEZE" 1 "RANGE" 0 "VALID" ;
VAL_ 1319 DI_a205_latAccel 7 "TEMP_QF_INVALID" 6 "QF_VALIDITY" 5 "CAN" 4 "QF" 3 "RATE" 2 "FREEZE" 1 "RANGE" 0 "VALID" ;
VAL_ 1319 DI_a205_pitchRate 7 "TEMP_QF_INVALID" 6 "QF_VALIDITY" 5 "CAN" 4 "QF" 3 "RATE" 2 "FREEZE" 1 "RANGE" 0 "VALID" ;
VAL_ 1319 DI_a206_verticalAccel 7 "TEMP_QF_INVALID" 6 "QF_VALIDITY" 5 "CAN" 4 "QF" 3 "RATE" 2 "FREEZE" 1 "RANGE" 0 "VALID" ;
VAL_ 1319 DI_a206_yawRate 7 "TEMP_QF_INVALID" 6 "QF_VALIDITY" 5 "CAN" 4 "QF" 3 "RATE" 2 "FREEZE" 1 "RANGE" 0 "VALID" ;
VAL_ 1319 DI_a210_ptcStateGlobal 3 "SNA" 2 "ON" 1 "BACKUP" 0 "FAULTED" ;
VAL_ 1319 DI_a210_espActuatorState 3 "COMMAND_INVALID" 2 "ACTUATOR_AVAILABLE" 1 "ACTUATOR_DEGRADED" 0 "ACTUATOR_UNAVAILABLE" ;
VAL_ 1319 DI_a223_ptcStateLocal 6 "SNA" 5 "STARTUP" 4 "ON" 3 "ADD_REDUCED" 2 "WHEELS_REDUCED" 1 "BACKUP" 0 "FAULTED" ;
VAL_ 1319 DI_a223_btcState 1 "ON" 0 "OFF" ;
VAL_ 1319 DI_a223_velocityEstimatorState 5 "BACKUP_MOTOR" 4 "BACKUP_WHEELS_B" 3 "BACKUP_WHEELS_A" 2 "WHEELS_REDUCED" 1 "WHEELS_NORMAL" 0 "NOT_INITIALIZED" ;
VAL_ 1319 DI_a223_addState_dir 3 "FAULTED" 2 "BACKUP" 1 "NORMAL" 0 "STARTUP" ;
VAL_ 1319 DI_a223_addState_dif 3 "FAULTED" 2 "BACKUP" 1 "NORMAL" 0 "STARTUP" ;
VAL_ 1319 DI_a223_DI_tractionControlMode 7 "SLIPPERY_SURFACE" 6 "OFFROAD_ASSIST" 5 "DYNO_MODE" 4 "ROLLS_MODE" 3 "DEV_MODE_2" 2 "DEV_MODE_1" 1 "SLIP_START" 0 "NORMAL" ;
VAL_ 1319 DI_a223_UI_tractionControlMode 7 "SLIPPERY_SURFACE_SELECTED" 6 "OFFROAD_ASSIST_SELECTED" 5 "DYNO_MODE_SELECTED" 4 "ROLLS_MODE_SELECTED" 3 "DEV_MODE_2_SELECTED" 2 "DEV_MODE_1_SELECTED" 1 "SLIP_START_SELECTED" 0 "NORMAL_SELECTED" ;
VAL_ 1319 DI_a223_driveTCActive 1 "ACTIVE" 0 "INACTIVE" ;
VAL_ 1319 DI_a223_regenTCActive 1 "ACTIVE" 0 "INACTIVE" ;
VAL_ 1319 DI_a226_systState 8 "FAULT" 7 "RETRY" 6 "WAIT_FOR_RETRY" 5 "ABORT" 4 "ENABLE" 3 "STANDBY" 2 "IDLE" 1 "UNAVAILABLE" 0 "START" ;
VAL_ 1319 DI_a227_hvState 6 "UP" 5 "UP_FOR_DC_CHARGE" 4 "UP_FOR_CHARGE" 3 "UP_FOR_DRIVE" 2 "GOING_DOWN" 1 "COMING_UP" 0 "DOWN" ;
VAL_ 1319 DI_a227_vehiclePowerState 3 "DRIVE" 2 "ACCESSORY" 1 "CONDITIONING" 0 "OFF" ;
VAL_ 1319 DI_a232_velocityEstimatorState 5 "BACKUP_MOTOR" 4 "BACKUP_WHEELS_B" 3 "BACKUP_WHEELS_A" 2 "WHEELS_REDUCED" 1 "WHEELS_NORMAL" 0 "NOT_INITIALIZED" ;
VAL_ 1319 DI_a232_UI_tractionControlMode 7 "SLIPPERY_SURFACE_SELECTED" 6 "OFFROAD_ASSIST_SELECTED" 5 "DYNO_MODE_SELECTED" 4 "ROLLS_MODE_SELECTED" 3 "DEV_MODE_2_SELECTED" 2 "DEV_MODE_1_SELECTED" 1 "SLIP_START_SELECTED" 0 "NORMAL_SELECTED" ;
VAL_ 1319 DI_a232_allWhlSpeedRotationAvail 1 "AVAILABLE" 0 "UNAVAILABLE" ;
VAL_ 1319 DI_a232_BrakeMasterCylPressValid 1 "VALID" 0 "INVALID" ;
VAL_ 1319 DI_a232_WheelBrakeTorquesValid 1 "VALID" 0 "INVALID" ;
VAL_ 1319 DI_a232_AbsBrakeEventActiveValid 1 "VALID" 0 "INVALID" ;
VAL_ 1319 DI_a232_UndersteerActiveValid 1 "VALID" 0 "INVALID" ;
VAL_ 1319 DI_a232_OversteerActiveValid 1 "VALID" 0 "INVALID" ;
VAL_ 1319 DI_a232_allMotorTorquesValid 1 "VALID" 0 "INVALID" ;
VAL_ 1319 DI_a232_lateralAccelValid 1 "VALID" 0 "INVALID" ;
VAL_ 1319 DI_a232_longitudinalAccelValid 1 "VALID" 0 "INVALID" ;
VAL_ 1319 DI_a232_yawRateValid 1 "VALID" 0 "INVALID" ;
VAL_ 1319 DI_a232_steerAngleValid 1 "VALID" 0 "INVALID" ;
VAL_ 1319 DI_a245_ebrStatus 3 "EBR_COMMAND_INVALID" 2 "ACTUATING_DI_EBR" 1 "EBR_IS_AVAILABLE" 0 "EBR_IS_NOT_AVAILABLE" ;
VAL_ 1319 DI_a245_vehicleHoldState 7 "INIT" 6 "FAULT" 5 "PARK" 4 "BLEND_OUT" 3 "STANDSTILL" 2 "BLEND_IN" 1 "STANDBY" 0 "UNAVAILABLE" ;
VAL_ 1319 DI_a246_onePedalDrivingState 8 "NUM_STATES" 7 "MOTOR_BLEND_IN" 6 "NO_MOTOR" 5 "MOTOR_BLEND_OUT_ACTIVE" 4 "MOTOR_BLEND_OUT_PENDING" 3 "NOMINAL" 2 "STANDBY" 1 "QUICK_BRAKE_RAMP" 0 "UNAVAILABLE" ;
VAL_ 1319 DI_a246_opdUnavailableReason 16 "UNIT0_FAULT" 15 "MOTOR_HOLD_TIMEOUT" 14 "INVALID_MSPD" 13 "PARKED" 12 "TORQUE_LIMIT" 11 "GRADE_ESTIMATE" 10 "TRACTION_CONTROL" 9 "VELOCITY_ESTIMATE" 8 "TRACK_MODE" 7 "EPB_FAULT" 6 "SKID" 5 "INVALID_BRAKE_SENSE" 4 "DI_SYS_STATE" 3 "GEAR" 2 "PM_FAULT" 1 "DISABLED" 0 "NONE" ;
VAL_ 328 DI_imuOffsetLearnRequest 2 "IMU_FAST_LEARNING_TIME" 1 "IMU_SLOW_LEARNING_DISTANCE" 0 "IMU_OFFSET_LEARNING_OFF" ;
VAL_ 328 DI_brakeCommandType 1 "QUIET" 0 "FAST" ;
VAL_ 328 DI_brakeTorqueRequestActive 1 "ACTIVE" 0 "INACTIVE" ;
VAL_ 328 DI_ptcStateGlobal 3 "GLOBAL_PTC_STATE_SNA" 2 "GLOBAL_PTC_STATE_ON" 1 "GLOBAL_PTC_STATE_BACKUP" 0 "GLOBAL_PTC_STATE_FAULTED" ;
VAL_ 328 DI_ptcActive 1 "ACTIVE" 0 "INACTIVE" ;
VAL_ 328 DI_vdcState 3 "VDC_STATE_STARTUP" 2 "VDC_STATE_NORMAL" 1 "VDC_STATE_BACKUP_A" 0 "VDC_STATE_FAULTED" ;
VAL_ 328 DI_isAnyVdcControlActive 2 "UNUSED_VALUE" 1 "VDC_CONTROL_ACTIVE" 0 "VDC_NO_CONTROL_ACTIVE" ;
VAL_ 328 DI_vdcMode 2 "VDC_MODE_TRACK" 1 "VDC_MODE_ON" 0 "VDC_MODE_OFF" ;
VAL_ 328 DI_pedalAssistCurveSelect 15 "PEDAL_ASSIST_CURVE_15" 12 "PEDAL_ASSIST_CURVE_12" 11 "PEDAL_ASSIST_CURVE_11" 8 "PEDAL_ASSIST_CURVE_8" 6 "PEDAL_ASSIST_CURVE_6" 3 "PEDAL_ASSIST_CURVE_3" 0 "PEDAL_ASSIST_CURVE_0" ;
VAL_ 328 DI_isAnyTcActive 1 "ACTIVE" 0 "INACTIVE" ;
VAL_ 328 DI_vdcControlActive 4 "VDC_DECEL_ACTIVE" 3 "VDC_TRAILER_SWAY_ACTIVE" 2 "VDC_UNDERSTEER_ACTIVE" 1 "VDC_OVERSTEER_ACTIVE" 0 "VDC_NOT_ACTIVE" ;
VAL_ 328 DI_treadDepthAlertSet 1 "TRUE" 0 "FALSE" ;
VAL_ 1861 DI_chassisControlVideoRequest 15 "CHASSIS_CONTROL_EVENT_15" 14 "CHASSIS_CONTROL_EVENT_14" 13 "CHASSIS_CONTROL_EVENT_13" 12 "CHASSIS_CONTROL_EVENT_12" 11 "CHASSIS_CONTROL_EVENT_11" 10 "CHASSIS_CONTROL_EVENT_10" 9 "CHASSIS_CONTROL_EVENT_9" 8 "CHASSIS_CONTROL_EVENT_8" 7 "CHASSIS_CONTROL_EVENT_7" 6 "CHASSIS_CONTROL_EVENT_6" 5 "CHASSIS_CONTROL_EVENT_5" 4 "CHASSIS_CONTROL_EVENT_4" 3 "CHASSIS_CONTROL_EVENT_3" 2 "CHASSIS_CONTROL_EVENT_2" 1 "CHASSIS_CONTROL_EVENT_1" 0 "CHASSIS_CONTROL_EVENT_NONE" ;
VAL_ 1861 DI_counterSteerTarget 2 "EXPIRED" 1 "ACTIVE" 0 "INACTIVE" ;
VAL_ 1861 DI_turnDirection 1 "VDC_TURNING_LEFT" 0 "VDC_TURNING_RIGHT" ;
VAL_ 1861 DI_oppositeBuildDirFrontAxle 1 "TRUE" 0 "FALSE" ;
VAL_ 1861 DI_oppositeBuildDirRearAxle 1 "TRUE" 0 "FALSE" ;
VAL_ 1861 DI_saturatedEffectiveness 1 "TRUE" 0 "FALSE" ;
VAL_ 1861 DI_preControlOpposingTurnDir 1 "TRUE" 0 "FALSE" ;
VAL_ 1869 DI_kTireEstReUnSat 127 "SNA" ;
VAL_ 1869 DI_distanceSinceLastTireConfig 63 "SNA" ;
VAL_ 1869 DI_kTireEstRe 31 "SNA" ;
VAL_ 694 DI_vdcTelltaleFlash 1 "TELLTALE_ON" 0 "TELLTALE_OFF" ;
VAL_ 694 DI_vdcTelltaleOn 1 "TELLTALE_ON" 0 "TELLTALE_OFF" ;
VAL_ 694 DI_tcTelltaleFlash 1 "TELLTALE_ON" 0 "TELLTALE_OFF" ;
VAL_ 694 DI_tcTelltaleOn 1 "TELLTALE_ON" 0 "TELLTALE_OFF" ;
VAL_ 694 DI_tractionControlModeUI 7 "TC_SLIPPERY_SURFACE" 6 "TC_OFFROAD_ASSIST" 5 "TC_DYNO_MODE" 4 "TC_ROLLS_MODE" 3 "TC_DEV_MODE_2" 2 "TC_DEV_MODE_1" 1 "TC_SLIP_START" 0 "TC_NORMAL" ;
VAL_ 694 DI_ptcStateGlobalUI 3 "GLOBAL_PTC_STATE_SNA" 2 "GLOBAL_PTC_STATE_ON" 1 "GLOBAL_PTC_STATE_BACKUP" 0 "GLOBAL_PTC_STATE_FAULTED" ;
VAL_ 694 DI_btcStateUI 1 "ON" 0 "OFF" ;
VAL_ 694 DI_vehicleHoldTelltaleOn 1 "TELLTALE_ON" 0 "TELLTALE_OFF" ;
VAL_ 694 DI_slipperySurfaceOnUI 1 "SLIPPERY_SURFACE_ON" 0 "SLIPPERY_SURFACE_OFF" ;
VAL_ 694 DI_yellowBrakeTelltaleOn 1 "TELLTALE_ON" 0 "TELLTALE_OFF" ;
VAL_ 694 DI_greenABSTelltaleOn 1 "TELLTALE_ON" 0 "TELLTALE_OFF" ;
VAL_ 2007 DI_debugSelector 75 "longControl" 69 "Mux69" 68 "Mux68" 67 "Mux67" 66 "Mux66" 65 "Mux65" 53 "Mux53" 50 "sysHeat" 45 "aeb" 39 "regenBackfill" 38 "pedalTorque1" 37 "onePedalDriving3" 36 "onePedalDriving2" 35 "onePedalDriving1" 34 "sysPedal" 33 "Mux33" 32 "pwrSat" 2 "Mux2" ;
VAL_ 2007 DI_regenBackfillUnavailableReaso 18 "DI_LATENT_FAULT_TRIP" 17 "EBR_FULL_FAULT" 16 "PM_DISABLE_REQUEST_BPED" 15 "PM_DISABLE_REQUEST_BLEND" 14 "CARBON_CERAMIC_BRAKES" 13 "BRAKE_TEMP" 12 "EBR_FAULT" 11 "PM_DISABLE_REQUEST" 10 "TRACK_MODE_ACTIVE" 9 "VELOCITY_ESTIMATOR_UNAVAILABLE" 8 "TRACTION_CONTROL_UNAVAILABLE" 7 "ACTIVE_DAMPING_UNAVAILABLE" 6 "UI_COASTDOWN_MODE" 5 "SYSTEM_STATE" 4 "NON_DRIVE_GEAR" 3 "EBR_UNAVAILABLE" 2 "UI_DISABLE" 1 "GTW_DISABLE" 0 "NONE" ;
VAL_ 2007 DI_regenBackfillAbsSatState 2 "RAMP_IN" 1 "RAMP_OUT" 0 "IDLE" ;
VAL_ 1866 DI_brakeFLTemp 1023 "SNA" ;
VAL_ 1866 DI_brakeFRTemp 1023 "SNA" ;
VAL_ 1866 DI_brakeRLTemp 1023 "SNA" ;
VAL_ 1866 DI_brakeRRTemp 1023 "SNA" ;
VAL_ 1623 DI_infoIndex 255 "INFO_END" 44 "TRACKING_DATA_5" 43 "TRACKING_DATA_4" 42 "TRACKING_DATA_3" 41 "TRACKING_DATA_2" 40 "TRACKING_DATA_1" 34 "INFO_SUBCOMPONENT2_HWID" 33 "INFO_SUBCOMPONENT_HWID" 32 "INFO_SUBCOMPONENT2_GITHASH" 31 "INFO_SUBCOMPONENT_GITHASH" 23 "INFO_SUBCOMPONENT2" 20 "INFO_UDS_PROTOCOL_BOOTCRC" 19 "INFO_VERSION_DEPRECATED" 18 "INFO_BOOTLOADER_GITHASH" 17 "INFO_APP_GITHASH" 16 "INFO_SUBCOMPONENT" 15 "INFO_BOOTLOADER_CRC" 14 "INFO_BOOTLOADER_SVN" 13 "INFO_APP_CRC" 11 "INFO_PCBAID_ASSYID_USAGEID" 10 "INFO_BUILD_HWID_COMPONENTID" 9 "INFO_DEPRECATED_9" 8 "INFO_DEPRECATED_8" 7 "INFO_DEPRECATED_7" 6 "INFO_DEPRECATED_6" 5 "INFO_DEPRECATED_5" 4 "INFO_DEPRECATED_4" 3 "INFO_DEPRECATED_3" 2 "INFO_DEPRECATED_2" 1 "INFO_DEPRECATED_1" 0 "INFO_DEPRECATED_0" ;
VAL_ 1623 DI_buildType 4 "INFO_MFG_BUILD" 3 "INFO_TRACEABLE_CI_BUILD" 2 "INFO_LOCAL_BUILD" 1 "INFO_PLATFORM_BUILD" 0 "INFO_UNKNOWN_BUILD" ;
VAL_ 1623 DI_hardwareId 252 "CONFIGURABLE_HWID_PLACEHOLDER" ;
VAL_ 646 DI_cruiseState 7 "CRS_STATE_PRE_CANCEL" 6 "CRS_STATE_PRE_FAULT" 5 "CRS_STATE_FAULT" 4 "CRS_STATE_OVERRIDE" 3 "CRS_STATE_STANDSTILL" 2 "CRS_STATE_ENABLED" 1 "CRS_STATE_STANDBY" 0 "CRS_STATE_UNAVAILABLE" ;
VAL_ 646 DI_cruiseSetSpeedUnits 1 "DI_SPEED_KPH" 0 "DI_SPEED_MPH" ;
VAL_ 646 DI_autoparkState 15 "DI_APC_SNA" 9 "DI_APC_SELFPARK_STARTED" 8 "DI_APC_UNPARK_COMPLETE" 7 "DI_APC_RESUMED" 6 "DI_APC_ABORTED" 5 "DI_APC_PAUSED" 4 "DI_APC_COMPLETE" 3 "DI_APC_ACTIVE" 2 "DI_APC_STARTED" 1 "DI_APC_STANDBY" 0 "DI_APC_UNAVAILABLE" ;
VAL_ 646 DI_parkBrakeState 15 "DI_PBRK_SNA" 7 "DI_PBRK_RELEASING" 6 "DI_PBRK_PANIC_SKID" 5 "DI_PBRK_PANIC_EPB" 4 "DI_PBRK_FAULTED" 3 "DI_PBRK_APPLIED" 2 "DI_PBRK_REQUESTED" 1 "DI_PBRK_RELEASED" 0 "DI_PBRK_UNAVAILABLE" ;
VAL_ 646 DI_aebState 7 "AEB_CAN_STATE_SNA" 5 "AEB_CAN_STATE_UNAVAILABLE_ALERT" 4 "AEB_CAN_STATE_FAULT" 3 "AEB_CAN_STATE_STANDSTILL" 2 "AEB_CAN_STATE_ENABLED" 1 "AEB_CAN_STATE_STANDBY" 0 "AEB_CAN_STATE_UNAVAILABLE" ;
VAL_ 646 DI_loncDeactivationReason 3 "ABORT" 2 "DAS_CANCEL" 1 "USER_CANCEL" 0 "NO_CANCEL" ;
VAL_ 646 DI_vehicleHoldState 7 "DI_VHLD_STATE_INIT" 6 "DI_VHLD_STATE_FAULT" 5 "DI_VHLD_STATE_PARK" 4 "DI_VHLD_STATE_BLEND_OUT" 3 "DI_VHLD_STATE_STANDSTILL" 2 "DI_VHLD_STATE_BLEND_IN" 1 "DI_VHLD_STATE_STANDBY" 0 "DI_VHLD_STATE_UNAVAILABLE" ;
VAL_ 646 DI_onePedalDrivingState 8 "DI_OPD_NUM_STATES" 7 "DI_OPD_MOTOR_BLEND_IN" 6 "DI_OPD_NO_MOTOR" 5 "DI_OPD_MOTOR_BLEND_OUT_ACTIVE" 4 "DI_OPD_MOTOR_BLEND_OUT_PENDING" 3 "DI_OPD_NOMINAL" 2 "DI_OPD_STANDBY" 1 "DI_OPD_QUICK_BRAKE_RAMP" 0 "DI_OPD_UNAVAILABLE" ;
VAL_ 646 DI_regenBackfillState 2 "BFILL_ACTIVE" 1 "BFILL_STANDBY" 0 "BFILL_UNAVAILABLE" ;
VAL_ 646 DI_cruiseNotAvailableReason 50 "DI_CRUISE_NOT_AVAILABLE_AIR_COMPRESSOR_FAULT" 49 "DI_CRUISE_NOT_AVAILABLE_ABS_FAULT" 48 "DI_CRUISE_NOT_AVAILABLE_DRIVERLESS_AUTONOMY_BEHAVIOR" 47 "DI_CRUISE_NOT_AVAILABLE_EPB_DYNAMIC_APPLY" 46 "DI_CRUISE_NOT_AVAILABLE_SGS_REQUEST" 45 "DI_CRUISE_NOT_AVAILABLE_VDC_FAULT" 44 "DI_CRUISE_NOT_AVAILABLE_ACCEL_JERK_OUT_OF_ISO_BOUNDS" 43 "DI_CRUISE_NOT_AVAILABLE_REDUNDANT_BRAKES_ACTIVE" 42 "DI_CRUISE_NOT_AVAILABLE_ABS_UNAVAILABLE" 41 "DI_CRUISE_NOT_AVAILABLE_LONC_DEGRADED" 40 "DI_CRUISE_NOT_AVAILABLE_FACTORY_MODE" 39 "DI_CRUISE_NOT_AVAILABLE_EPB_FAULT" 38 "DI_CRUISE_NOT_AVAILABLE_AEB_STACK_UNAVAILABLE" 37 "DI_CRUISE_NOT_AVAILABLE_AEB_STACK_EVENT_INACTIVE" 36 "DI_CRUISE_NOT_AVAILABLE_DFLK_ENGAGED" 35 "DI_CRUISE_NOT_AVAILABLE_INTERFACE_NOT_SUPPORTED" 34 "DI_CRUISE_NOT_AVAILABLE_CANCEL_ACTIVE" 33 "DI_CRUISE_NOT_AVAILABLE_CONTROL_STACK_SWITCH" 32 "DI_CRUISE_NOT_AVAILABLE_SHIFT_OUTSIDE_SPEED_THRESHOLD" 31 "DI_CRUISE_NOT_AVAILABLE_SHIFT_TIMEOUT" 30 "DI_CRUISE_NOT_AVAILABLE_OFFROAD_MODE_ACTIVE" 29 "DI_CRUISE_NOT_AVAILABLE_DAS_CONTROL_MIA" 28 "DI_CRUISE_NOT_AVAILABLE_UNIT0_FAULT" 27 "DI_CRUISE_NOT_AVAILABLE_BRAKE_TEMPERATURE" 26 "DI_CRUISE_NOT_AVAILABLE_ACC_BACKWARD_AT_HIGH_FORWARD_SPEED" 25 "DI_CRUISE_NOT_AVAILABLE_DAS_SET_SPEED_TOO_HIGH_IN_REVERSE" 24 "DI_CRUISE_NOT_AVAILABLE_MOTOR_SPEED_TOO_HIGH_IN_REVERSE" 23 "DI_CRUISE_NOT_AVAILABLE_VHLD_UNAVAILABLE" 22 "DI_CRUISE_NOT_AVAILABLE_CRUISE_FAULTED" 21 "DI_CRUISE_NOT_AVAILABLE_TRACK_MODE_ACTIVE" 20 "DI_CRUISE_NOT_AVAILABLE_DAS_SNA" 19 "DI_CRUISE_NOT_AVAILABLE_UI_MIA" 18 "DI_CRUISE_NOT_AVAILABLE_WAIT_INIT" 17 "DI_CRUISE_NOT_AVAILABLE_VEL_EST" 16 "DI_CRUISE_NOT_AVAILABLE_MAX_SPEED" 15 "DI_CRUISE_NOT_AVAILABLE_MIN_SPEED" 14 "DI_CRUISE_NOT_AVAILABLE_AEB" 13 "DI_CRUISE_NOT_AVAILABLE_CONFIG" 12 "DI_CRUISE_NOT_AVAILABLE_DI_STATE" 11 "DI_CRUISE_NOT_AVAILABLE_MOTOR_SPEED" 10 "DI_CRUISE_NOT_AVAILABLE_EBR" 9 "DI_CRUISE_NOT_AVAILABLE_VALET_MODE" 8 "DI_CRUISE_NOT_AVAILABLE_SEAT_BELT_UNBUCKLED" 7 "DI_CRUISE_NOT_AVAILABLE_CLOSURE_OPEN" 6 "DI_CRUISE_NOT_AVAILABLE_ACC_CANCEL" 5 "DI_CRUISE_NOT_AVAILABLE_ABS_ACTIVE" 4 "DI_CRUISE_NOT_AVAILABLE_TC_ACTIVE" 3 "DI_CRUISE_NOT_AVAILABLE_VDC_ACTIVE_OR_DEGRADED" 2 "DI_CRUISE_NOT_AVAILABLE_VDC_OR_TC_OFF" 1 "DI_CRUISE_NOT_AVAILABLE_NO_ALERT" 0 "DI_CRUISE_NOT_AVAILABLE_NONE" ;
VAL_ 646 DI_cruiseFaultReason 22 "DI_CRUISE_FAULT_VHLD_FAULTED" 21 "DI_CRUISE_FAULT_CONFIG_MISMATCH" 20 "DI_CRUISE_FAULT_EPB_MIA" 19 "DI_CRUISE_FAULT_ACCEL_JERK_OUT_OF_ISO_BOUNDS" 17 "DI_CRUISE_FAULT_DAS_SNA" 16 "DI_CRUISE_FAULT_VELOCITY_ESTIMATE_NOT_NORMAL" 15 "DI_CRUISE_FAULT_ACCEL_OUT_OF_BOUNDS" 14 "DI_CRUISE_FAULT_EBR_FAULT" 13 "DI_CRUISE_FAULT_TC_FAULT" 12 "DI_CRUISE_FAULT_ESP_MIA" 11 "DI_CRUISE_FAULT_VDC_FAULT" 10 "DI_CRUISE_FAULT_EPB_FAULT" 9 "DI_CRUISE_FAULT_BRAKE_MIA" 8 "DI_CRUISE_FAULT_CRS_STATE_MISM" 7 "DI_CRUISE_FAULT_ABS_MIA" 6 "DI_CRUISE_FAULT_CRUISE_SCCM_MIA" 5 "DI_CRUISE_FAULT_BRAKE_INVALID" 4 "DI_CRUISE_FAULT_STALK" 3 "DI_CRUISE_FAULT_PM_REQUEST" 2 "DI_CRUISE_FAULT_PM_MIA" 1 "DI_CRUISE_FAULT_MOTOR_SPEED_MISMATCH" 0 "DI_CRUISE_FAULT_NONE" ;
VAL_ 646 DI_cruiseCancelReason 11 "DI_CRUISE_CANCEL_DAS_MIA_PEDAL_APPLY" 10 "DI_CRUISE_CANCEL_ACC_FSD_EXIT" 9 "DI_CRUISE_CANCEL_SHIFT_REQUEST" 8 "DI_CRUISE_CANCEL_ACCEL_OVERRIDE_IN_REVERSE" 7 "DI_CRUISE_CANCEL_DAS" 6 "DI_CRUISE_CANCEL_PARK" 5 "DI_CRUISE_CANCEL_GEAR" 4 "DI_CRUISE_CANCEL_STALK" 3 "DI_CRUISE_CANCEL_BRAKE" 2 "DI_CRUISE_CANCEL_SKID" 1 "DI_CRUISE_CANCEL_APC_REQUEST" 0 "DI_CRUISE_CANCEL_NONE" ;
VAL_ 1270 DI_doublePedalState 12 "DBL_BRKSTAND_TRQ_RAMPUP_DONE" 11 "DBL_BRKSTAND_LAUNCH" 10 "DBL_BRKSTAND_TRQ_HOLD" 9 "DBL_BRKSTAND_INIT_TRQ_RAMPUP" 8 "DBL_BRKSTAND_ARMED2" 7 "DBL_BRKSTAND_ARMED1" 6 "DBL_BRKOVR_RAMPUP" 5 "DBL_BRKOVR_RAMPDOWN" 4 "DBL_BRKPRESS_PREOVR" 3 "DBL_BRKPRESS_RAMPUP" 2 "DBL_BRKPRESS_RAMPDOWN" 1 "DBL_DRIVING" 0 "DBL_IDLE" ;
VAL_ 1270 DI_autopilotRequest 1 "DI_AP_RQST_ACTIVATE" 0 "DI_AP_RQST_IDLE" ;
VAL_ 1270 DI_rollPreventionState 7 "DI_RP_STATE_INIT" 6 "DI_RP_STATE_FAULT" 5 "DI_RP_STATE_MAX_BRAKE_TORQUE" 4 "DI_RP_STATE_HOLD" 3 "DI_RP_STATE_BUILD" 2 "DI_RP_STATE_READY" 1 "DI_RP_STATE_STANDBY" 0 "DI_RP_STATE_UNAVAILABLE" ;
VAL_ 1270 DI_regenBlendingState 3 "BLEND_FRICTION_ONLY" 2 "BLEND_ACTIVE" 1 "BLEND_STANDBY" 0 "BLEND_UNAVAILABLE" ;
VAL_ 1270 DI_pedalAssistCurveSelectForSX 15 "PEDAL_ASSIST_CURVE_15" 12 "PEDAL_ASSIST_CURVE_12" 11 "PEDAL_ASSIST_CURVE_11" 8 "PEDAL_ASSIST_CURVE_8" 6 "PEDAL_ASSIST_CURVE_6" 3 "PEDAL_ASSIST_CURVE_3" 0 "PEDAL_ASSIST_CURVE_0" ;
VAL_ 1270 DI_longitudinalControlStack 7 "VELOCITY_PROFILE_CONTROL_SUPPRESS_CANCEL" 6 "DIRECT_TORQUE_CONTROL" 5 "DIRECT_PEDAL_CONTROL" 4 "AEB_CONTROL" 3 "VELOCITY_PROFILE_CONTROL" 2 "LONC_TORQUE_PROFILER" 1 "LEGACY_CRUISE" 0 "REQUEST_SNA" ;
VAL_ 822 DI_sysDrivePowerRated 511 "SNA" ;
VAL_ 822 DI_performancePackage 7 "SNA" 6 "PERFORMANCE_2022" 5 "BASE_PLUS_2022" 4 "BASE_2022" 3 "BASE_PLUS" 2 "BASE_2024" 1 "PERFORMANCE" 0 "BASE" ;
VAL_ 822 DI_sysRegenPowerRated 255 "SNA" ;
VAL_ 950 DI_odometer 4294967295 "SNA" ;
VAL_ 599 DI_uiSpeed 511 "DI_UI_SPEED_SNA" ;
VAL_ 599 DI_uiSpeedUnits 1 "DI_SPEED_KPH" 0 "DI_SPEED_MPH" ;
VAL_ 599 DI_vehicleSpeed 8191 "SNA" ;
VAL_ 599 DI_velocityEstimatorState 5 "VE_STATE_BACKUP_MOTOR" 4 "VE_STATE_BACKUP_WHEELS_B" 3 "VE_STATE_BACKUP_WHEELS_A" 2 "VE_STATE_WHEELS_REDUCED" 1 "VE_STATE_WHEELS_NORMAL" 0 "VE_STATE_NOT_INITIALIZED" ;
VAL_ 597 DI_lastQualifiedGear 7 "DI_GEAR_SNA" 4 "DI_GEAR_D" 3 "DI_GEAR_N" 2 "DI_GEAR_R" 1 "DI_GEAR_P" 0 "DI_GEAR_INVALID" ;
VAL_ 597 DI_lastDrivingGear 7 "DI_GEAR_SNA" 4 "DI_GEAR_D" 3 "DI_GEAR_N" 2 "DI_GEAR_R" 1 "DI_GEAR_P" 0 "DI_GEAR_INVALID" ;
VAL_ 597 DI_suggestedGearReason 14 "REASON_1ST_SHFT_PAR_PARK_NO_USS" 13 "REASON_AP_NOT_READY" 12 "REASON_EEPROM" 11 "REASON_AP_MIA" 10 "REASON_AP_NOT_CONFIDENT" 9 "REASON_AP" 8 "REASON_SUB_SHFT" 7 "REASON_SUB_SHFT_PAR_PARK" 6 "REASON_SUB_SHFT_RE_BLCK_PAR_PARK" 5 "REASON_SUB_SHFT_RE_BLCK" 4 "REASON_1ST_SHFT_FR_BLCK_PAR_PARK" 3 "REASON_1ST_SHFT_RE_BLCK" 2 "REASON_1ST_SHFT_FR_BLCK" 1 "REASON_1ST_SHFT_PAR_PARK" 0 "REASON_RETRACE" ;
VAL_ 597 DI_smartShiftGear 2 "REVERSE" 1 "DRIVE" 0 "NONE" ;
VAL_ 597 DI_smartShiftUnavailableReason 18 "SMART_SHIFT_UNAVAILABLE_DAS_MIA" 17 "SMART_SHIFT_UNAVAILABLE_DAS_NOT_CONFIDENT" 16 "SMART_SHIFT_UNAVAILABLE_DISPLAY_ERROR" 15 "SMART_SHIFT_UNAVAILABLE_VDC_UNAVAILABLE" 14 "SMART_SHIFT_UNAVAILABLE_VHLD_UNAVAILABLE" 13 "SMART_SHIFT_UNAVAILABLE_OPD_UNAVAILABLE" 12 "SMART_SHIFT_UNAVAILABLE_BLS_UNKNOWN" 11 "SMART_SHIFT_UNAVAILABLE_IBST_MIA" 10 "SMART_SHIFT_SILENT_UNAVAILABLE_AEB_ACTIVE" 9 "SMART_SHIFT_SILENT_UNAVAILABLE_CRUISE_REGULATING" 8 "SMART_SHIFT_SILENT_UNAVAILABLE_GTW_NOT_QUALIFIED" 7 "SMART_SHIFT_SILENT_UNAVAILABLE_SGS_ACTIVE" 6 "SMART_SHIFT_SILENT_UNAVAILABLE_CLOSURE_OPEN" 5 "SMART_SHIFT_SILENT_UNAVAILABLE_CHARGE_CABLE_CONNECTED" 4 "SMART_SHIFT_SILENT_UNAVAILABLE_DRIVER_BUCKLED_QF" 3 "SMART_SHIFT_SILENT_UNAVAILABLE_NON_STANDARD_MODE" 2 "SMART_SHIFT_SILENT_UNAVAILABLE_UI_DISABLE" 1 "SMART_SHIFT_UNAVAILABLE_NONE" 0 "SMART_SHIFT_UNAVAILABLE_SNA" ;
VAL_ 296 DI_vehicleSpeedLimitType 2 "POWERTRAIN" 1 "USER" 0 "NONE" ;
VAL_ 296 DI_vehicleSpeedLimit 511 "SNA" ;
VAL_ 296 DI_vehicleSpeedLimitReason 15 "FACTORY_BRAKE_BURNISHING" 14 "TAS_OFFROAD" 13 "SLIP_START_LIMIT" 12 "LV_DEGRADED" 11 "MAX_TIRE_TYPE" 10 "USER" 9 "FRUNK_OPEN" 8 "DAS_PEDAL_CONTROL" 7 "TAS" 6 "TRAILER_MODE" 5 "MAX_CAR_CONFIG" 4 "SERVICE_MODE" 3 "FACTORY_MODE" 2 "FACTORY_LOW_BRAKE_FLUID" 1 "DRIVE_UNIT_LIMIT" 0 "NONE" ;
